VERSION ""

NS_ :

BS_:

BU_: Airbag Allrad EPS Teves_MK60_ESP LWS LWR Teves_MK70_MABS Waehlhebel EPB TRW_ESP ACC_Radar AFS Magne_Ride RKA_Plus Selespeed Waehlhebel_Sele PDC_PLA Lenkhilfe_APA VAQ Daempfer Hybrid_BMS Hybrid_PWR Hybrid_DQ200 EKlimakomp SWA HCA ACC_Lidar Lenkhilfe_ZF_3G FLA AG6 DQ Hybrid_MSG Diesel Otto Gateway_PQ35_A Gateway_PQ46_A Vector_XXX Fzg_CAN

BO_ 1488 mSysteminfo_1: 8 Gateway_PQ35_A
 SG_ SY1_Diag_Ant : 1|1@1+ (1,0) [0|1] "" Vector__XXX
 SG_ SY1_CAN_extern : 0|1@1+ (1,0) [0|1] "" Vector__XXX
 SG_ SY1_Diag_Komf : 3|1@1+ (1,0) [0|1] "" Vector__XXX
 SG_ SY1_Sleep_Info : 4|1@1+ (1,0) [0|1] "" Vector__XXX
 SG_ SY1_Sleep_Komf : 2|1@1+ (1,0) [0|1] "" Vector__XXX
 SG_ SY1_CAN_Info : 6|1@1+ (1,0) [0|1] "" Vector__XXX
 SG_ SY1_Diag_Info : 5|1@1+ (1,0) [0|1] "" Vector__XXX
 SG_ SY1_Verbauinfo : 7|1@1+ (1,0) [0|1] ""  Airbag,Diesel
 SG_ SY1_Fzg_Marke : 12|4@1+ (1,0) [0|15] "" Vector__XXX
 SG_ SY1_Fzg_Klasse : 8|4@1+ (1,0) [0|15] "" Vector__XXX
 SG_ SY1_Fzg_Index : 24|4@1+ (1,0) [0|15] "" Vector__XXX
 SG_ SY1_Fzg_Gen : 20|4@1+ (1,0) [0|15] "" Vector__XXX
 SG_ SY1_Tueren : 29|1@1+ (1,0) [0|1] "" Vector__XXX
 SG_ SY1_Fzg_Derivat : 16|4@1+ (1,0) [0|15] "" Vector__XXX
 SG_ SY1_Lenker : 28|1@1+ (1,0) [0|1] ""  TRW_ESP
 SG_ SY1_Fehlereintr : 31|1@1+ (1,0) [0|1] "" Vector__XXX
 SG_ SY1_Komf_HV : 36|4@1+ (1,0) [0|9] "" Vector__XXX
 SG_ SY1_Transportmode : 30|1@1+ (1,0) [0|1] ""  Daempfer
 SG_ SY1_Ant_NV : 40|4@1+ (1,0) [0|9] "" Vector__XXX
 SG_ SY1_Komf_NV : 32|4@1+ (1,0) [0|9] "" Vector__XXX
 SG_ SY1_Ant_HV : 44|4@1+ (1,0) [0|9] "" Vector__XXX
 SG_ SY1_Notbrems_Status : 56|1@1+ (1,0) [0|1] "" Vector__XXX
 SG_ SY1_ELV_Lock_Supply : 50|1@1+ (1,0) [0|1] "" Vector__XXX
 SG_ SY1_Relais_FAS_Zweig : 48|2@1+ (1,0) [0|3] ""  TRW_ESP,HCA
 SG_ SY1_QRS_Messmodus : 51|1@1+ (1,0) [0|1] ""  Otto
 SG_ SY1_res52 : 52|1@1+ (1,0) [0|1] "" Vector__XXX
 SG_ SY1_NWDF_gueltig : 54|1@1+ (1,0) [0|1] "" Vector__XXX
 SG_ SY1_res53 : 53|1@1+ (1,0) [0|1] "" Vector__XXX
 SG_ SY1_res59 : 59|1@1+ (1,0) [0|1] "" Vector__XXX
 SG_ SY1_NWDF : 55|1@1+ (1,0) [0|1] "" Vector__XXX
 SG_ SY1_res60 : 60|1@1+ (1,0) [0|1] "" Vector__XXX
 SG_ SY1_res62 : 62|1@1+ (1,0) [0|1] "" Vector__XXX
 SG_ SY1_res58 : 58|1@1+ (1,0) [0|1] "" Vector__XXX
 SG_ SY1_res57 : 57|1@1+ (1,0) [0|1] "" Vector__XXX
 SG_ SY1_res61 : 61|1@1+ (1,0) [0|1] "" Vector__XXX
 SG_ SY1_res63 : 63|1@1+ (1,0) [0|1] "" Vector__XXX

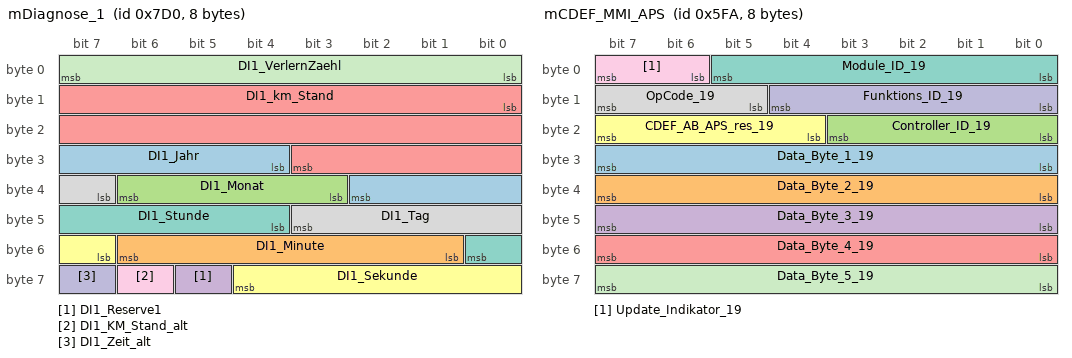
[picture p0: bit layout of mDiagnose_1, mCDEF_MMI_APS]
BO_ 2000 mDiagnose_1: 8 Gateway_PQ35_A
 SG_ DI1_Jahr : 28|7@1+ (1,2000) [2000|2127] "a"  Airbag,Diesel,Otto,Teves_MK60_ESP,LWR,Teves_MK70_MABS,EPB,TRW_ESP,ACC_Radar,AFS,Magne_Ride,RKA_Plus,PDC_PLA,Lenkhilfe_APA,VAQ,Daempfer,Hybrid_MSG,Hybrid_BMS,Hybrid_PWR,HCA,SWA,Allrad,ACC_Lidar,FLA,EPS,Lenkhilfe_ZF_3G
 SG_ DI1_Minute : 49|6@1+ (1,0) [0|59] "min"  Airbag,Diesel,Otto,LWR,EPB,TRW_ESP,ACC_Radar,AFS,Magne_Ride,RKA_Plus,PDC_PLA,Lenkhilfe_APA,VAQ,Daempfer,Hybrid_MSG,Hybrid_BMS,Hybrid_PWR,HCA,SWA,Allrad,ACC_Lidar,FLA,Teves_MK60_ESP,EPS,Lenkhilfe_ZF_3G
 SG_ DI1_Monat : 35|4@1+ (1,0) [0|15] ""  Airbag,Diesel,Otto,Teves_MK60_ESP,LWR,Teves_MK70_MABS,EPB,TRW_ESP,ACC_Radar,AFS,Magne_Ride,RKA_Plus,PDC_PLA,Lenkhilfe_APA,VAQ,Daempfer,Hybrid_MSG,Hybrid_BMS,Hybrid_PWR,HCA,SWA,Allrad,ACC_Lidar,FLA,Lenkhilfe_ZF_3G,EPS
 SG_ DI1_Reserve1 : 61|1@1+ (1,0) [0|1] ""  Allrad
 SG_ DI1_km_Stand : 8|20@1+ (1,0) [0|1048575] "km"  Airbag,Diesel,Otto,LWR,EPB,TRW_ESP,ACC_Radar,AFS,Magne_Ride,RKA_Plus,PDC_PLA,Lenkhilfe_APA,VAQ,Daempfer,Hybrid_MSG,Hybrid_BMS,Hybrid_PWR,HCA,SWA,Allrad,ACC_Lidar,FLA
 SG_ DI1_Sekunde : 55|6@1+ (1,0) [0|59] "s"  Airbag,Diesel,Otto,LWR,EPB,TRW_ESP,ACC_Radar,AFS,Magne_Ride,RKA_Plus,PDC_PLA,Lenkhilfe_APA,Daempfer,VAQ,Hybrid_MSG,Hybrid_BMS,Hybrid_PWR,HCA,SWA,Allrad,ACC_Lidar,FLA,Teves_MK60_ESP,EPS,Lenkhilfe_ZF_3G
 SG_ DI1_Stunde : 44|5@1+ (1,0) [0|23] "h"  Airbag,Diesel,Otto,LWR,EPB,TRW_ESP,ACC_Radar,AFS,Magne_Ride,RKA_Plus,PDC_PLA,Lenkhilfe_APA,VAQ,Daempfer,Hybrid_MSG,Hybrid_BMS,Hybrid_PWR,HCA,SWA,Allrad,ACC_Lidar,FLA,Teves_MK60_ESP,EPS,Lenkhilfe_ZF_3G
 SG_ DI1_Tag : 39|5@1+ (1,0) [0|31] ""  Airbag,Diesel,Otto,Teves_MK60_ESP,LWR,Teves_MK70_MABS,EPB,TRW_ESP,ACC_Radar,AFS,Magne_Ride,RKA_Plus,PDC_PLA,Lenkhilfe_APA,VAQ,Daempfer,Hybrid_MSG,Hybrid_BMS,Hybrid_PWR,HCA,SWA,Allrad,ACC_Lidar,FLA,EPS,Lenkhilfe_ZF_3G
 SG_ DI1_KM_Stand_alt : 62|1@1+ (1,0) [0|1] ""  Airbag,Diesel,Otto,LWR,EPB,TRW_ESP,ACC_Radar,AFS,Magne_Ride,RKA_Plus,PDC_PLA,Lenkhilfe_APA,VAQ,Hybrid_MSG,Hybrid_BMS,Hybrid_PWR,HCA,Daempfer,SWA,Allrad,ACC_Lidar,FLA
 SG_ DI1_Zeit_alt : 63|1@1+ (1,0) [0|1] ""  Airbag,Diesel,Otto,LWR,EPB,TRW_ESP,ACC_Radar,AFS,Magne_Ride,RKA_Plus,PDC_PLA,Lenkhilfe_APA,Hybrid_MSG,Hybrid_PWR,Hybrid_BMS,HCA,Daempfer,SWA,Allrad,ACC_Lidar,FLA,Teves_MK60_ESP,Lenkhilfe_ZF_3G,EPS
 SG_ DI1_VerlernZaehl : 0|8@1+ (1,0) [0|254] ""  Airbag,Diesel,Otto,LWR,EPB,TRW_ESP,ACC_Radar,AFS,Magne_Ride,RKA_Plus,PDC_PLA,Lenkhilfe_APA,VAQ,Daempfer,Hybrid_MSG,Hybrid_BMS,Hybrid_PWR,HCA,SWA,Allrad,ACC_Lidar,FLA,Teves_MK60_ESP

BO_ 1500 mSoll_Verbauliste_neu: 8 Gateway_PQ35_A
 SG_ VL1_Getr_SG : 1|1@1+ (1,0) [0|1] ""  TRW_ESP
 SG_ VL1_Airbag : 5|1@1+ (1,0) [0|1] ""  Otto,TRW_ESP,Hybrid_MSG
 SG_ VL1_Motor_SG : 0|1@1+ (1,0) [0|1] ""  TRW_ESP
 SG_ VL1_ABS : 2|1@1+ (1,0) [0|1] ""  Otto,Hybrid_MSG
 SG_ VL1_res_08 : 8|1@1+ (1,0) [0|1] "" Vector__XXX
 SG_ VL1_EPB : 12|1@1+ (1,0) [0|1] "" Vector__XXX
 SG_ VL1_Kombi : 3|1@1+ (1,0) [0|1] "" Vector__XXX
 SG_ VL1_Allrad : 9|1@1+ (1,0) [0|1] ""  Teves_MK60_ESP,Teves_MK70_MABS,TRW_ESP
 SG_ VL1_LSM : 4|1@1+ (1,0) [0|1] ""  Otto,Hybrid_MSG,TRW_ESP
 SG_ VL1_Lenkhilfe : 6|1@1+ (1,0) [0|1] "" Vector__XXX
 SG_ VL1_ADR : 10|1@1+ (1,0) [0|1] ""  TRW_ESP,Teves_MK60_ESP
 SG_ VL1_Daempfer : 14|1@1+ (1,0) [0|1] "" Vector__XXX
 SG_ VL1_dyn_LWR : 7|1@1+ (1,0) [0|1] "" Vector__XXX
 SG_ VL1_DAB : 57|1@1+ (1,0) [0|1] "" Vector__XXX
 SG_ VL1_MotorSlave : 16|1@1+ (1,0) [0|1] "" Vector__XXX
 SG_ VL1_res_13 : 13|1@1+ (1,0) [0|1] "" Vector__XXX
 SG_ VL1_TSG_BT : 27|1@1+ (1,0) [0|1] "" Vector__XXX
 SG_ VL1_TSG_FT : 26|1@1+ (1,0) [0|1] "" Vector__XXX
 SG_ VL1_TSG_HL : 28|1@1+ (1,0) [0|1] "" Vector__XXX
 SG_ VL1_ZKE : 25|1@1+ (1,0) [0|1] "" Vector__XXX
 SG_ VL1_BSG_Komf : 24|1@1+ (1,0) [0|1] ""  Otto,Hybrid_MSG
 SG_ VL1_Memory : 30|1@1+ (1,0) [0|1] "" Vector__XXX
 SG_ VL1_Dachmodul_K : 31|1@1+ (1,0) [0|1] "" Vector__XXX
 SG_ VL1_TSG_HR : 29|1@1+ (1,0) [0|1] "" Vector__XXX
 SG_ VL1_Zentralelektrik_II : 32|1@1+ (1,0) [0|1] "" Vector__XXX
 SG_ VL1_Lenksaeule : 34|1@1+ (1,0) [0|1] ""  Otto,Hybrid_MSG
 SG_ VL1_Einparkhilfe : 37|1@1+ (1,0) [0|1] "" Vector__XXX
 SG_ VL1_Gateway : 35|1@1+ (1,0) [0|1] ""  Otto,Hybrid_MSG
 SG_ VL1_RDK : 33|1@1+ (1,0) [0|1] "" Vector__XXX
 SG_ VL1_PTC_Heizung : 38|1@1+ (1,0) [0|1] "" Vector__XXX
 SG_ VL1_Standheiz : 39|1@1+ (1,0) [0|1] "" Vector__XXX
 SG_ VL1_Clima_Komf : 36|1@1+ (1,0) [0|1] ""  Diesel,Otto,Hybrid_MSG
 SG_ VL1_res_42 : 42|1@1+ (1,0) [0|1] "" Vector__XXX
 SG_ VL1_RSE_I : 41|1@1+ (1,0) [0|1] "" Vector__XXX
 SG_ VL1_Verdeck : 40|1@1+ (1,0) [0|1] "" Vector__XXX
 SG_ VL1_MDI_I : 43|1@1+ (1,0) [0|1] "" Vector__XXX
 SG_ VL1_Memory_BF : 45|1@1+ (1,0) [0|1] "" Vector__XXX
 SG_ VL1_Heckdeckel : 48|1@1+ (1,0) [0|1] "" Vector__XXX
 SG_ VL1_Anhaenger : 44|1@1+ (1,0) [0|1] ""  TRW_ESP
 SG_ VL1_Easy_Entry_VF : 46|1@1+ (1,0) [0|1] "" Vector__XXX
 SG_ VL1_Sonderfzg_SG : 50|1@1+ (1,0) [0|1] "" Vector__XXX
 SG_ VL1_Tastenmodul : 51|1@1+ (1,0) [0|1] "" Vector__XXX
 SG_ VL1_Radio : 62|1@1+ (1,0) [0|1] "" Vector__XXX
 SG_ VL1_Telefon : 63|1@1+ (1,0) [0|1] "" Vector__XXX
 SG_ VL1_Navigation : 59|1@1+ (1,0) [0|1] "" Vector__XXX
 SG_ VL1_Neigungsmodul_I : 61|1@1+ (1,0) [0|1] "" Vector__XXX
 SG_ VL1_ADR_getrennt : 11|1@1+ (1,0) [0|1] "" Vector__XXX
 SG_ VL1_DSP : 56|1@1+ (1,0) [0|1] "" Vector__XXX
 SG_ VL1_Easy_Entry_VB : 47|1@1+ (1,0) [0|1] "" Vector__XXX
 SG_ VL1_Telematik : 58|1@1+ (1,0) [0|1] "" Vector__XXX
 SG_ VL1_TV_Tuner : 60|1@1+ (1,0) [0|1] "" Vector__XXX
 SG_ VL1_WFS_K : 53|1@1+ (1,0) [0|1] "" Vector__XXX
 SG_ VL1_Kompass : 52|1@1+ (1,0) [0|1] "" Vector__XXX
 SG_ VL1_Rearview : 49|1@1+ (1,0) [0|1] "" Vector__XXX
 SG_ VL1_GSM_Pager : 54|1@1+ (1,0) [0|1] "" Vector__XXX
 SG_ VL1_InfoElektronik : 55|1@1+ (1,0) [0|1] "" Vector__XXX
 SG_ VL1_Kombi_KBI : 22|1@1+ (1,0) [0|1] "" Vector__XXX
 SG_ VL1_Soll_eq_Ist : 23|1@1+ (1,0) [0|1] ""  Otto,Hybrid_MSG
 SG_ VL1_Quersperre : 15|1@1+ (1,0) [0|1] "" Vector__XXX
 SG_ VL1_SWA : 17|1@1+ (1,0) [0|1] "" Vector__XXX
 SG_ VL1_PLA : 20|1@1+ (1,0) [0|1] "" Vector__XXX
 SG_ VL1_HCA : 18|1@1+ (1,0) [0|1] ""  HCA
 SG_ VL1_WFS_KBI : 21|1@1+ (1,0) [0|1] "" Vector__XXX
 SG_ VL1_RKA_Plus : 19|1@1+ (1,0) [0|1] "" Vector__XXX

BO_ 1504 mClima_1: 8 Gateway_PQ35_A
 SG_ CL1_Hecksch : 2|1@1+ (1,0) [0|1] "" Vector__XXX
 SG_ CL1_Heizleist : 5|1@1+ (1,0) [0|1] ""  Diesel
 SG_ CL1_Fa_Zuheiz : 1|1@1+ (1,0) [0|1] ""  Diesel,Hybrid_MSG
 SG_ CL1_Kompressor : 4|1@1+ (1,0) [0|1] ""  Diesel,Otto,Hybrid_MSG
 SG_ CL1_Sta_Druck : 7|1@1+ (1,0) [0|1] ""  Otto,Hybrid_MSG
 SG_ CL1_Frontsch : 3|1@1+ (1,0) [0|1] "" Vector__XXX
 SG_ CL1_Sta_Moment : 6|1@1+ (1,0) [0|1] ""  Otto,Hybrid_MSG
 SG_ CL1_Kompr_Last : 24|8@1+ (0.25,0) [0|63.5] "Nm"  Diesel,Otto,Hybrid_MSG
 SG_ CL1_Druck : 16|8@1+ (0.2,0) [0|50.8] "bar"  Diesel,Otto,Hybrid_MSG
 SG_ CL1_Aussentemp : 8|8@1+ (0.5,-50) [-50|77] "°C" Vector__XXX
 SG_ CL1_Gebl_last : 32|8@1+ (0.4,0) [0|101.6] "%"  Hybrid_BMS,Otto
 SG_ CL1_Einheit_Temp : 48|1@1+ (1,0) [0|1] "" Vector__XXX
 SG_ CL1_Luefter : 40|8@1+ (0.4,0) [0|101.6] "%"  Diesel,Otto,Hybrid_MSG
 SG_ CL1_Fehlereintr : 55|1@1+ (1,0) [0|1] "" Vector__XXX
 SG_ CL1_WAPU_Zuschaltung : 50|1@1+ (1,0) [0|1] "" Vector__XXX
 SG_ CL1_Restwaerme : 51|1@1+ (1,0) [0|1] "" Vector__XXX
 SG_ CL1_LL_Dz : 0|1@1+ (1,0) [0|1] ""  Diesel,Otto,Hybrid_MSG
 SG_ CL1_AC_Schalter : 49|1@1+ (1,0) [0|1] ""  Diesel,Otto
 SG_ CL1_Temp_Stoss : 56|8@1+ (0.5,-50) [-50|77] "°C" Vector__XXX
 SG_ CL1_PTC_Hzg : 52|3@1+ (25,0) [0|100] "%" Vector__XXX

BO_ 1952 mTP_Dyn_LWS: 8 Gateway_PQ35_A
 SG_ TPDyn_LWS : 0|64@1+ (1,0) [0|1.8446744074E+019] ""  LWS

BO_ 1857 mTP_Dyn_Motor_2: 8 Gateway_PQ35_A
 SG_ TPDyn_Motor_2 : 0|64@1+ (1,0) [0|1.8446744074E+019] ""  Diesel,Otto,Hybrid_MSG

BO_ 1856 mTP_Dyn_Motor_1: 8 Gateway_PQ35_A
 SG_ TPDyn_Motor_1 : 0|64@1+ (1,0) [0|1.8446744074E+019] ""  Diesel,Otto,Hybrid_MSG

BO_ 1859 mTP_Dyn_Motor_4: 8 Gateway_PQ35_A
 SG_ TPDyn_Motor_4 : 0|64@1+ (1,0) [0|1.8446744074E+019] ""  Diesel,Otto,Hybrid_MSG

BO_ 512 mTP_Er_Tester: 7 Gateway_PQ35_A
 SG_ Tester_TP_Er : 0|56@1+ (1,0) [0|7.2057594038E+016] ""  AG6,Airbag,Allrad,Diesel,EPS,Otto,Teves_MK60_ESP,LWS,LWR,Teves_MK70_MABS,DQ,EPB,TRW_ESP,ACC_Radar,AFS,Magne_Ride,RKA_Plus,Selespeed,PDC_PLA,Lenkhilfe_APA,VAQ,Daempfer,Hybrid_MSG,Hybrid_DQ200,SWA

BO_ 1858 mTP_Dyn_Motor_3: 8 Gateway_PQ35_A
 SG_ TPDyn_Motor_3 : 0|64@1+ (1,0) [0|1.8446744074E+019] ""  Diesel,Otto,Hybrid_MSG

BO_ 1893 mTP_Dyn_Allrad_2: 8 Gateway_PQ35_A
 SG_ TPDyn_Allrad_2 : 0|64@1+ (1,0) [0|1.8446744074E+019] ""  Allrad

BO_ 1906 mTP_Dyn_Daempfer_1: 8 Gateway_PQ35_A
 SG_ TPDyn_Daempfer_1 : 0|64@1+ (1,0) [0|1.8446744074E+019] ""  Magne_Ride,Daempfer

BO_ 1875 mTP_Dyn_RKA_Plus_2: 8 Gateway_PQ35_A
 SG_ TPDyn_RKA_Plus_2 : 0|64@1+ (1,0) [0|1.8446744074E+019] ""  RKA_Plus

BO_ 1874 mTP_Dyn_RKA_Plus_1: 8 Gateway_PQ35_A
 SG_ TPDyn_RKA_Plus_1 : 0|64@1+ (1,0) [0|1.8446744074E+019] ""  RKA_Plus

BO_ 914 mGate_Komf_2: 8 Gateway_PQ35_A
 SG_ GK2_Sta_Lichtsensor : 1|1@1+ (1,0) [0|1] ""  AFS,SWA
 SG_ GK2_Sta_Kessy_4 : 8|1@1+ (1,0) [0|1] ""  Diesel,Otto
 SG_ GK2_res_09 : 9|1@1+ (1,0) [0|1] "" Vector__XXX
 SG_ GK2_Sta_LSM : 0|1@1+ (1,0) [0|1] "" Vector__XXX
 SG_ GK2_Helligkeit : 16|3@1+ (714.286,0) [0|5000.002] "Lux"  AFS,SWA
 SG_ GK2_Sta_VSG : 3|1@1+ (1,0) [0|1] ""  Airbag,PDC_PLA,Otto
 SG_ GK2_Sta_Profil : 5|1@1+ (1,0) [0|1] ""  SWA,PDC_PLA
 SG_ GK2_Sta_Clima2 : 6|1@1+ (1,0) [0|1] ""  Diesel,Otto
 SG_ GK2_Sta_Licht1 : 2|1@1+ (1,0) [0|1] ""  HCA,SWA,AFS
 SG_ GK2_Feh_VLR : 10|1@1+ (1,0) [0|1] "" Vector__XXX
 SG_ GK2_Sta_BSG4 : 7|1@1+ (1,0) [0|1] ""  Diesel,Otto
 SG_ GK2_Blk_L_Kontrolle : 11|1@1+ (1,0) [0|1] ""  HCA,SWA
 SG_ GK2_Sta_Schluessel : 4|1@1+ (1,0) [0|1] ""  TRW_ESP,Daempfer,EPB
 SG_ GK2_res_13 : 13|1@1+ (1,0) [0|1] "" Vector__XXX
 SG_ GK2_LS_KomFehler : 14|1@1+ (1,0) [0|1] ""  AFS
 SG_ GK2_VD_zu_ver : 19|1@1+ (1,0) [0|1] ""  PDC_PLA
 SG_ GK2_Blk_R_Kontrolle : 12|1@1+ (1,0) [0|1] ""  HCA,SWA
 SG_ GK2_VD_offen_ver : 21|1@1+ (1,0) [0|1] ""  Airbag,PDC_PLA,Otto
 SG_ GK2_LS_def : 15|1@1+ (1,0) [0|1] ""  AFS
 SG_ GK2_Verdeck_Anf : 22|1@1+ (1,0) [0|1] ""  PDC_PLA
 SG_ GK2_VD_entriegelt : 20|1@1+ (1,0) [0|1] ""  PDC_PLA
 SG_ GK2_VDKD_auf : 23|1@1+ (1,0) [0|1] ""  PDC_PLA
 SG_ GK2_Schluessel : 24|4@1+ (1,0) [0|15] ""  Daempfer
 SG_ GK2_EM_LIN_ungueltig : 31|1@1+ (1,0) [0|1] ""  Diesel,Otto
 SG_ GK2_AFL_Schalter : 29|1@1+ (1,0) [0|1] ""  AFS
 SG_ GK2_Hardtop : 28|1@1+ (1,0) [0|1] ""  PDC_PLA
 SG_ GK2_Profil : 32|4@1+ (1,0) [0|15] ""  PDC_PLA,SWA
 SG_ GK2_Kl_StSt_Info : 36|2@1+ (1,0) [0|3] ""  Otto,Diesel
 SG_ GK2_BEM_P_Generator : 40|8@1+ (50,0) [0|12700] "W"  Diesel,Otto
 SG_ GK2_BEM_Abschaltstufen : 48|3@1+ (1,0) [0|7] ""  Diesel,Otto
 SG_ GK2_res_60 : 60|4@1+ (1,0) [0|15] "" Vector__XXX
 SG_ GK2_Nebelschluss : 30|1@1+ (1,0) [0|1] ""  AFS
 SG_ GK2_BSG_StSt_Info : 38|2@1+ (1,0) [0|3] ""  Otto,Diesel
 SG_ GK2_BEM_DFM : 51|5@1+ (3.225,0.025) [0.025|100] "%"  Diesel,Otto
 SG_ GK2_BEM_StSt_Info : 58|2@1+ (1,0) [0|3] ""  Diesel,Otto
 SG_ GK2_Kessy_StSt_Info : 56|2@1+ (1,0) [0|3] ""  Diesel,Otto

BO_ 1978 mTP_Dyn_PLA_PDC: 8 Gateway_PQ35_A
 SG_ TPDyn_PLA_PDC : 0|64@1+ (1,0) [0|1.8446744074E+019] ""  PDC_PLA

BO_ 1940 mTP_Dyn_EPB_1: 8 Gateway_PQ35_A
 SG_ TPDyn_EPB_1 : 0|64@1+ (1,0) [0|1.8446744074E+019] ""  EPB,TRW_ESP

BO_ 1880 mTP_Dyn_Quersperre_1: 8 Gateway_PQ35_A
 SG_ TPDyn_Quersperre_1 : 0|64@1+ (1,0) [0|1.8446744074E+019] ""  VAQ

BO_ 1881 mTP_Dyn_Quersperre_2: 8 Gateway_PQ35_A
 SG_ TPDyn_Quersperre_2 : 0|64@1+ (1,0) [0|1.8446744074E+019] ""  VAQ

BO_ 919 mZKE_5: 8 Gateway_PQ35_A
 SG_ ZK5_Endlage_ausgefahren : 12|1@1+ (1,0) [0|1] ""  Teves_MK60_ESP
 SG_ ZK5_Status_Spoiler : 14|1@1+ (1,0) [0|1] ""  Teves_MK60_ESP
 SG_ ZK5_Endlage_eingefahren : 13|1@1+ (1,0) [0|1] ""  Teves_MK60_ESP
 SG_ ZK5_res_15 : 15|1@1+ (1,0) [0|1] "" Vector__XXX
 SG_ ZK5_Zaehler : 8|4@1+ (1,0) [0|15] "Tabelle"  Teves_MK60_ESP
 SG_ ZK5_Checksumme : 0|8@1+ (1,0) [0|255] "Tabelle"  Teves_MK60_ESP
 SG_ ZK5_VD_Endlage_geschl : 16|1@1+ (1,0) [0|1] ""  Teves_MK60_ESP,PDC_PLA
 SG_ ZK5_VD_Endlage_abgelegt : 17|1@1+ (1,0) [0|1] ""  Teves_MK60_ESP,PDC_PLA
 SG_ ZK5_VD_Verbau : 18|1@1+ (1,0) [0|1] ""  Teves_MK60_ESP,PDC_PLA
 SG_ ZK5_res_20 : 20|1@1+ (1,0) [0|1] "" Vector__XXX
 SG_ ZK5_res_21 : 21|1@1+ (1,0) [0|1] "" Vector__XXX
 SG_ ZK5_res_22 : 22|1@1+ (1,0) [0|1] "" Vector__XXX
 SG_ ZK5_res_19 : 19|1@1+ (1,0) [0|1] "" Vector__XXX
 SG_ ZK5_res_23 : 23|1@1+ (1,0) [0|1] "" Vector__XXX
 SG_ ZK5_res_24 : 24|1@1+ (1,0) [0|1] "" Vector__XXX
 SG_ ZK5_res_25 : 25|1@1+ (1,0) [0|1] "" Vector__XXX
 SG_ ZK5_res_26 : 26|1@1+ (1,0) [0|1] "" Vector__XXX
 SG_ ZK5_res_27 : 27|1@1+ (1,0) [0|1] "" Vector__XXX
 SG_ ZK5_res_29 : 29|1@1+ (1,0) [0|1] "" Vector__XXX
 SG_ ZK5_res_31 : 31|1@1+ (1,0) [0|1] "" Vector__XXX
 SG_ ZK5_res_32 : 32|1@1+ (1,0) [0|1] "" Vector__XXX
 SG_ ZK5_res_33 : 33|1@1+ (1,0) [0|1] "" Vector__XXX
 SG_ ZK5_res_34 : 34|1@1+ (1,0) [0|1] "" Vector__XXX
 SG_ ZK5_res_30 : 30|1@1+ (1,0) [0|1] "" Vector__XXX
 SG_ ZK5_res_35 : 35|1@1+ (1,0) [0|1] "" Vector__XXX
 SG_ ZK5_res_28 : 28|1@1+ (1,0) [0|1] "" Vector__XXX
 SG_ ZK5_res_36 : 36|1@1+ (1,0) [0|1] "" Vector__XXX
 SG_ ZK5_res_37 : 37|1@1+ (1,0) [0|1] "" Vector__XXX
 SG_ ZK5_res_38 : 38|1@1+ (1,0) [0|1] "" Vector__XXX
 SG_ ZK5_res_40 : 40|1@1+ (1,0) [0|1] "" Vector__XXX
 SG_ ZK5_res_41 : 41|1@1+ (1,0) [0|1] "" Vector__XXX
 SG_ ZK5_res_42 : 42|1@1+ (1,0) [0|1] "" Vector__XXX
 SG_ ZK5_res_45 : 45|1@1+ (1,0) [0|1] "" Vector__XXX
 SG_ ZK5_res_46 : 46|1@1+ (1,0) [0|1] "" Vector__XXX
 SG_ ZK5_res_39 : 39|1@1+ (1,0) [0|1] "" Vector__XXX
 SG_ ZK5_res_47 : 47|1@1+ (1,0) [0|1] "" Vector__XXX
 SG_ ZK5_res_48 : 48|1@1+ (1,0) [0|1] "" Vector__XXX
 SG_ ZK5_res_49 : 49|1@1+ (1,0) [0|1] "" Vector__XXX
 SG_ ZK5_res_50 : 50|1@1+ (1,0) [0|1] "" Vector__XXX
 SG_ ZK5_res_51 : 51|1@1+ (1,0) [0|1] "" Vector__XXX
 SG_ ZK5_res_44 : 44|1@1+ (1,0) [0|1] "" Vector__XXX
 SG_ ZK5_res_52 : 52|1@1+ (1,0) [0|1] "" Vector__XXX
 SG_ ZK5_res_43 : 43|1@1+ (1,0) [0|1] "" Vector__XXX
 SG_ ZK5_res_53 : 53|1@1+ (1,0) [0|1] "" Vector__XXX
 SG_ ZK5_res_54 : 54|1@1+ (1,0) [0|1] "" Vector__XXX
 SG_ ZK5_res_55 : 55|1@1+ (1,0) [0|1] "" Vector__XXX
 SG_ ZK5_res_56 : 56|1@1+ (1,0) [0|1] "" Vector__XXX
 SG_ ZK5_res_57 : 57|1@1+ (1,0) [0|1] "" Vector__XXX
 SG_ ZK5_res_58 : 58|1@1+ (1,0) [0|1] "" Vector__XXX
 SG_ ZK5_res_59 : 59|1@1+ (1,0) [0|1] "" Vector__XXX
 SG_ ZK5_res_60 : 60|1@1+ (1,0) [0|1] "" Vector__XXX
 SG_ ZK5_res_63 : 63|1@1+ (1,0) [0|1] "" Vector__XXX
 SG_ ZK5_res_62 : 62|1@1+ (1,0) [0|1] "" Vector__XXX
 SG_ ZK5_res_61 : 61|1@1+ (1,0) [0|1] "" Vector__XXX

BO_ 1658 BAP_Anzeige_02: 8 Gateway_PQ35_A
 SG_ BAP_var_Anzeige_02 : 16|48@1+ (1,0) [0|2.8147497671E+014] "" Vector__XXX
 SG_ BAP_Data_Anzeige_02 : 0|16@1+ (1,0) [0|65535] ""  PDC_PLA,Hybrid_MSG

BO_ 1530 mCDEF_MMI_APS: 8 Gateway_PQ35_A
 SG_ Data_Byte_1_19 : 24|8@1+ (1,0) [0|255] ""  PDC_PLA
 SG_ Data_Byte_2_19 : 32|8@1+ (1,0) [0|255] ""  PDC_PLA
 SG_ Controller_ID_19 : 16|4@1+ (1,0) [0|15] ""  PDC_PLA
 SG_ Data_Byte_3_19 : 40|8@1+ (1,0) [0|255] ""  PDC_PLA
 SG_ Data_Byte_4_19 : 48|8@1+ (1,0) [0|255] ""  PDC_PLA
 SG_ CDEF_AB_APS_res_19 : 20|4@1+ (1,0) [0|15] "" Vector__XXX
 SG_ Module_ID_19 : 0|6@1+ (1,0) [0|63] ""  PDC_PLA
 SG_ OpCode_19 : 13|3@1+ (1,0) [0|7] ""  PDC_PLA
 SG_ Update_Indikator_19 : 6|2@1+ (1,0) [0|3] ""  PDC_PLA
 SG_ Funktions_ID_19 : 8|5@1+ (1,0) [0|31] ""  PDC_PLA
 SG_ Data_Byte_5_19 : 56|8@1+ (1,0) [0|255] ""  PDC_PLA

BO_ 2015 ISO_Funktionaler_Req_OBD: 8 Gateway_PQ35_A
 SG_ ISO_OBD_01_Req_Data : 0|64@1+ (1,0) [0|1.8446744074E+019] ""  Hybrid_DQ200,Hybrid_PWR,Hybrid_MSG,Hybrid_BMS,AG6,DQ,Diesel,Otto

BO_ 1792 ISO_Funktionaler_Req_All: 8 Gateway_PQ35_A
 SG_ ISO_ALL_01_Req_Data : 0|64@1+ (1,0) [0|1.8446744074E+019] ""  EKlimakomp,Hybrid_BMS,Hybrid_PWR,Hybrid_MSG,Hybrid_DQ200,DQ,Diesel,AG6,Otto,Airbag,ACC_Lidar,Lenkhilfe_ZF_3G,PDC_PLA

BO_ 2017 ISO_Getriebe_01_Req: 8 Gateway_PQ35_A
 SG_ ISO_Getriebe_01_Req_Data : 0|64@1+ (1,0) [0|1.8446744074E+019] ""  Hybrid_DQ200,AG6,DQ

BO_ 2016 ISO_MO_01_Req: 8 Gateway_PQ35_A
 SG_ ISO_MO_01_Req_Data : 0|64@1+ (1,0) [0|1.8446744074E+019] ""  Hybrid_MSG,Diesel,Otto

BO_ 1976 mTP_Dyn_SWA_1: 8 Gateway_PQ35_A
 SG_ TPDyn_SWA_1 : 0|64@1+ (1,0) [0|1.8446744074E+019] ""  SWA

BO_ 1977 mTP_Dyn_SWA_2: 8 Gateway_PQ35_A
 SG_ TPDyn_SWA_2 : 0|64@1+ (1,0) [0|1.8446744074E+019] ""  SWA

BO_ 1654 BAP_Anzeige: 8 Gateway_PQ35_A
 SG_ BAP_var_Anzeige : 16|48@1+ (1,0) [0|2.8147497671E+014] "" Vector__XXX
 SG_ BAP_Data_Anzeige : 0|16@1+ (1,0) [0|65535] ""  HCA,SWA,ACC_Radar,PDC_PLA,ACC_Lidar

BO_ 2018 ISO_MOS_01_Req: 8 Gateway_PQ35_A
 SG_ ISO_MOS_01_Req_Data : 0|64@1+ (1,0) [0|1.8446744074E+019] "" Vector__XXX

BO_ 2021 ISO_OBD_BECM_Req: 8 Gateway_PQ35_A
 SG_ ISO_OBD_BECM_Req_Data : 0|64@1+ (1,0) [0|1.8446744074E+019] "" Vector__XXX

BO_ 2023 ISO_OBD_reserv5_Req: 8 Gateway_PQ35_A
 SG_ ISO_OBD_reserv5_Req_Data : 0|64@1+ (1,0) [0|1.8446744074E+019] "" Vector__XXX

BO_ 2022 ISO_OBD_DMCM_Req: 8 Gateway_PQ35_A
 SG_ ISO_OBD_DMCM_Req_Data : 0|64@1+ (1,0) [0|1.8446744074E+019] "" Vector__XXX

BO_ 2020 ISO_OBD_reserv2_Req: 8 Gateway_PQ35_A
 SG_ ISO_OBD_reserv2_Req_Data : 0|64@1+ (1,0) [0|1.8446744074E+019] "" Vector__XXX

BO_ 2019 ISO_OBD_reserv1_Req: 8 Gateway_PQ35_A
 SG_ ISO_OBD_reserv1_Req_Data : 0|64@1+ (1,0) [0|1.8446744074E+019] "" Vector__XXX

BO_ 1811 ISO_ABS_Req: 8 Gateway_PQ35_A
 SG_ ISO_ABS_Req_Data : 0|64@1+ (1,0) [0|1.8446744074E+019] "" Vector__XXX

BO_ 1876 ISO_LWRAFS_Req: 8 Gateway_PQ35_A
 SG_ ISO_LWRAFS_Req_Data : 0|64@1+ (1,0) [0|1.8446744074E+019] "" Vector__XXX

BO_ 1810 ISO_Lenkhilfe_Req: 8 Gateway_PQ35_A
 SG_ ISO_Lenkhilfe_Req_Data : 0|64@1+ (1,0) [0|1.8446744074E+019] ""  Lenkhilfe_ZF_3G

BO_ 1813 ISO_Airbag_01_Req: 8 Gateway_PQ35_A
 SG_ ISO_Airbag_01_Req_Data : 0|64@1+ (1,0) [0|1.8446744074E+019] ""  Airbag

BO_ 1802 ISO_EPH_Req: 8 Gateway_PQ35_A
 SG_ ISO_EPH_Req_Data : 0|64@1+ (1,0) [0|1.8446744074E+019] ""  PDC_PLA

BO_ 1879 ISO_ACC_Req: 8 Gateway_PQ35_A
 SG_ ISO_ACC_Req_Data : 0|64@1+ (1,0) [0|1.8446744074E+019] ""  ACC_Lidar

BO_ 1824 NMH_Gateway: 7 Gateway_PQ35_A
 SG_ NMH_GW_Abschaltstufe_aktiv : 38|1@1+ (1,0) [0|1] "" Vector__XXX
 SG_ NMH_GW_Car_WakeUp : 6|1@1+ (1,0) [0|1] "" Vector__XXX
 SG_ NMH_GW_Eindraht_Fehler : 39|1@1+ (1,0) [0|1] "" Vector__XXX
 SG_ NMH_GW_Fkt_WakeUp : 13|3@1+ (1,0) [0|7] "" Vector__XXX
 SG_ NMH_GW_kein_NL : 24|1@1+ (1,0) [0|1] "" Vector__XXX
 SG_ NMH_GW_KompSchutz : 35|1@1+ (1,0) [0|1] "" Vector__XXX
 SG_ NMH_GW_Mute_Mode : 36|1@1+ (1,0) [0|1] "" Vector__XXX
 SG_ NMH_GW_CAN_Diag_deaktiv : 34|1@1+ (1,0) [0|1] "" Vector__XXX
 SG_ NMH_GW_NL_1 : 25|1@1+ (1,0) [0|1] "" Vector__XXX
 SG_ NMH_GW_NL_2 : 26|1@1+ (1,0) [0|1] "" Vector__XXX
 SG_ NMH_GW_NL_3 : 27|1@1+ (1,0) [0|1] "" Vector__XXX
 SG_ NMH_GW_NL_4 : 28|1@1+ (1,0) [0|1] "" Vector__XXX
 SG_ NMH_GW_NL_5 : 29|1@1+ (1,0) [0|1] "" Vector__XXX
 SG_ NMH_GW_NL_6 : 30|1@1+ (1,0) [0|1] "" Vector__XXX
 SG_ NMH_GW_NL_7 : 31|1@1+ (1,0) [0|1] "" Vector__XXX
 SG_ NMH_GW_NL_aktiv_5 : 20|1@1+ (1,0) [0|1] "" Vector__XXX
 SG_ NMH_GW_NL_aktiv_6 : 21|1@1+ (1,0) [0|1] "" Vector__XXX
 SG_ NMH_GW_NL_aktiv_7 : 22|1@1+ (1,0) [0|1] "" Vector__XXX
 SG_ NMH_GW_NL_aktiv_8 : 23|1@1+ (1,0) [0|1] "" Vector__XXX
 SG_ NMH_GW_NM_aktiv_Diagnose : 17|1@1+ (1,0) [0|1] "" Vector__XXX
 SG_ NMH_GW_NM_aktiv_Klemme_15 : 16|1@1+ (1,0) [0|1] "" Vector__XXX
 SG_ NMH_GW_NL_aktiv_4 : 19|1@1+ (1,0) [0|1] "" Vector__XXX
 SG_ NMH_GW_NM_aktiv_Start : 18|1@1+ (1,0) [0|1] "" Vector__XXX
 SG_ NMH_GW_Normal_Mode_1 : 2|1@1+ (1,0) [0|1] "" Vector__XXX
 SG_ NMH_GW_Normal_Mode_2 : 3|1@1+ (1,0) [0|1] "" Vector__XXX
 SG_ NMH_GW_Per_WakeUp : 8|5@1+ (1,0) [0|31] "" Vector__XXX
 SG_ NMH_GW_res_04 : 4|1@1+ (1,0) [0|1] "" Vector__XXX
 SG_ NMH_GW_res_05 : 5|1@1+ (1,0) [0|1] "" Vector__XXX
 SG_ NMH_GW_res_32 : 32|1@1+ (1,0) [0|1] "" Vector__XXX
 SG_ NMH_GW_res_07 : 7|1@1+ (1,0) [0|1] "" Vector__XXX
 SG_ NMH_GW_res_41 : 41|1@1+ (1,0) [0|1] "" Vector__XXX
 SG_ NMH_GW_res_42 : 42|1@1+ (1,0) [0|1] "" Vector__XXX
 SG_ NMH_GW_res_43 : 43|1@1+ (1,0) [0|1] "" Vector__XXX
 SG_ NMH_GW_res_44 : 44|1@1+ (1,0) [0|1] "" Vector__XXX
 SG_ NMH_GW_res_45 : 45|1@1+ (1,0) [0|1] "" Vector__XXX
 SG_ NMH_GW_res_46 : 46|1@1+ (1,0) [0|1] "" Vector__XXX
 SG_ NMH_GW_res_40 : 40|1@1+ (1,0) [0|1] "" Vector__XXX
 SG_ NMH_GW_res_47 : 47|1@1+ (1,0) [0|1] "" Vector__XXX
 SG_ NMH_GW_res_48 : 48|1@1+ (1,0) [0|1] "" Vector__XXX
 SG_ NMH_GW_res_49 : 49|1@1+ (1,0) [0|1] "" Vector__XXX
 SG_ NMH_GW_res_50 : 50|1@1+ (1,0) [0|1] "" Vector__XXX
 SG_ NMH_GW_res_52 : 52|1@1+ (1,0) [0|1] "" Vector__XXX
 SG_ NMH_GW_res_53 : 53|1@1+ (1,0) [0|1] "" Vector__XXX
 SG_ NMH_GW_res_54 : 54|1@1+ (1,0) [0|1] "" Vector__XXX
 SG_ NMH_GW_res_55 : 55|1@1+ (1,0) [0|1] "" Vector__XXX
 SG_ NMH_GW_Start_1 : 0|1@1+ (1,0) [0|1] ""  Teves_MK60_ESP,Teves_MK70_MABS,TRW_ESP
 SG_ NMH_GW_res_51 : 51|1@1+ (1,0) [0|1] "" Vector__XXX
 SG_ NMH_GW_Start_2 : 1|1@1+ (1,0) [0|1] "" Vector__XXX
 SG_ NMH_GW_TimeOut_Fehler : 33|1@1+ (1,0) [0|1] "" Vector__XXX
 SG_ NMH_GW_Transport_Mode : 37|1@1+ (1,0) [0|1] "" Vector__XXX

BO_ 1956 mTP_Dyn_LDW_1: 8 Gateway_PQ35_A
 SG_ TPDyn_LDW_1 : 0|64@1+ (1,0) [0|1.8446744074E+019] "" Vector__XXX

BO_ 1957 mTP_Dyn_LDW_2: 8 Gateway_PQ35_A
 SG_ TPDyn_LDW_2 : 0|64@1+ (1,0) [0|1.8446744074E+019] ""  HCA

BO_ 2033 Req_Airbag_Deployment: 8 Gateway_PQ35_A
 SG_ Req_Airbag_Deployment : 0|64@1+ (1,0) [0|1.8446744074E+019] ""  Airbag

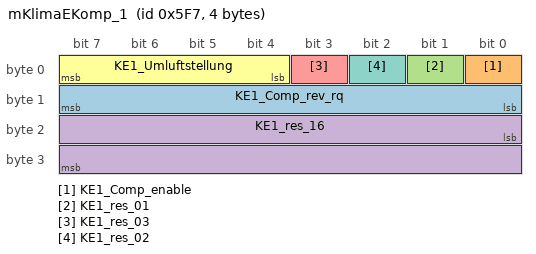
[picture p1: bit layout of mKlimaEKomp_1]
BO_ 1527 mKlimaEKomp_1: 4 Gateway_PQ35_A
 SG_ KE1_Comp_rev_rq : 8|8@1+ (50,0) [0|8600] "rpm"  EKlimakomp
 SG_ KE1_Comp_enable : 0|1@1+ (1,0) [0|1] ""  EKlimakomp
 SG_ KE1_res_01 : 1|1@1+ (1,0) [0|1] "" Vector__XXX
 SG_ KE1_res_16 : 16|16@1+ (1,0) [0|65535] "" Vector__XXX
 SG_ KE1_res_03 : 3|1@1+ (1,0) [0|1] "" Vector__XXX
 SG_ KE1_Umluftstellung : 4|4@1+ (10,0) [0|100] "%"  Hybrid_BMS
 SG_ KE1_res_02 : 2|1@1+ (1,0) [0|1] "" Vector__XXX

BO_ 1392 mBSG_Last: 5 Gateway_PQ46_A
 SG_ BSL_ZAS_Kl_50 : 3|1@1+ (1,0) [0|1] ""  TRW_ESP,Magne_Ride,EPB,Lenkhilfe_APA,Diesel
 SG_ BSL_Kl_L : 7|1@1+ (1,0) [0|1] ""  TRW_ESP
 SG_ BSL_ZAS_Kl_X : 2|1@1+ (1,0) [0|1] ""  TRW_ESP,EPB,HCA,Diesel,FLA
 SG_ BSL_ZAS_Kl_15 : 1|1@1+ (1,0) [0|1] ""  EPB,TRW_ESP,FLA
 SG_ BSL_Parklicht : 4|1@1+ (1,0) [0|1] ""  TRW_ESP
 SG_ BSL_ZAS_Kl_S : 0|1@1+ (1,0) [0|1] ""  TRW_ESP,EPB
 SG_ BSL_Motor_Haube : 15|1@1+ (1,0) [0|1] ""  TRW_ESP,Hybrid_MSG,Diesel,Otto
 SG_ BSL_Sta_UBat : 9|2@1+ (1,0) [0|3] ""  TRW_ESP
 SG_ BSL_Fehlereintr : 13|1@1+ (1,0) [0|1] ""  TRW_ESP
 SG_ BSL_LL_Anheb : 8|1@1+ (1,0) [0|1] ""  Diesel,Otto,TRW_ESP,Hybrid_MSG
 SG_ BSL_Frontsch : 25|1@1+ (1,0) [0|1] ""  TRW_ESP
 SG_ BSL_Sitzheiz : 27|1@1+ (1,0) [0|1] ""  TRW_ESP
 SG_ BSL_Lenkradheiz : 28|1@1+ (1,0) [0|1] ""  TRW_ESP
 SG_ BSL_Aussensp : 26|1@1+ (1,0) [0|1] ""  TRW_ESP
 SG_ BSL_Sitzbelueft : 30|1@1+ (1,0) [0|1] ""  TRW_ESP
 SG_ BSL_BSG_2_alt : 32|1@1+ (1,0) [0|1] ""  Diesel,Otto,TRW_ESP,Hybrid_MSG
 SG_ BSL_Hecksch : 24|1@1+ (1,0) [0|1] ""  TRW_ESP
 SG_ BSL_LL_Anheb2 : 5|1@1+ (1,0) [0|1] ""  Diesel,Otto,TRW_ESP,Hybrid_MSG
 SG_ BSL_Clima : 31|1@1+ (1,0) [0|1] ""  Diesel,Otto,TRW_ESP,Hybrid_MSG
 SG_ BSL_Weckursache_ACAN : 36|2@1+ (1,0) [0|3] ""  Otto,TRW_ESP,Hybrid_MSG
 SG_ BSL_BSG_3_alt : 33|1@1+ (1,0) [0|1] ""  Diesel,Otto,TRW_ESP,Hybrid_MSG,HCA,Lenkhilfe_APA,FLA
 SG_ BSL_Kl_15_Motor : 6|1@1+ (1,0) [0|1] ""  TRW_ESP
 SG_ BSL_UBat : 16|8@1+ (0.05,5) [5|17.7] "V"  TRW_ESP
 SG_ BSL_Kuehlerlueft : 34|1@1+ (1,0) [0|1] ""  Diesel,EPS,Otto,TRW_ESP,Hybrid_MSG,Lenkhilfe_ZF_3G
 SG_ BSL_Sta_LWR : 14|1@1+ (1,0) [0|1] ""  TRW_ESP
 SG_ BSL_Sta_StBat : 11|2@1+ (1,0) [0|3] ""  TRW_ESP
 SG_ BSL_Ab_Batterie : 35|1@1+ (1,0) [0|1] ""  Diesel,EPS,Otto,TRW_ESP,Lenkhilfe_APA,Hybrid_MSG,Lenkhilfe_ZF_3G
 SG_ BSL_Wasserheiz : 29|1@1+ (1,0) [0|1] ""  TRW_ESP
 SG_ BSL_Wake_Up_ACAN : 38|1@1+ (1,0) [0|1] ""  Otto,TRW_ESP,Hybrid_MSG
 SG_ BSL_Starterlaubnis : 39|1@1+ (1,0) [0|1] ""  TRW_ESP

BO_ 1394 mZAS_1: 1 Gateway_PQ46_A
 SG_ ZA1_S_Kontakt : 0|1@1+ (1,0) [0|1] ""  Diesel,Selespeed
 SG_ ZA1_Klemme_15 : 1|1@1+ (1,0) [0|1] ""  Diesel,Otto,PDC_PLA,Hybrid_MSG
 SG_ ZA1_Klemme_P : 4|1@1+ (1,0) [0|1] ""  Diesel
 SG_ ZA1_Klemme_X : 2|1@1+ (1,0) [0|1] ""  Diesel,AFS,PDC_PLA
 SG_ ZA1_Klemme_50 : 3|1@1+ (1,0) [0|1] ""  Diesel,Otto,AFS,Hybrid_MSG,Selespeed
 SG_ ZA1_Klemme_SV : 6|1@1+ (1,0) [0|1] "" Vector__XXX
 SG_ ZA1_Reserve3 : 12|3@1+ (1,0) [0|7] "" Vector__XXX
 SG_ ZA1_Reserve1 : 5|1@1+ (1,0) [0|1] "" Vector__XXX
 SG_ ZA1_Zaehler : 8|4@1+ (1,0) [0|15] "" Vector__XXX
 SG_ ZA1_Checksumme : 24|8@1+ (1,0) [0|255] "" Vector__XXX
 SG_ ZA1_Fehlereintr : 15|1@1+ (1,0) [0|1] "" Vector__XXX
 SG_ ZA1_res07 : 7|1@1+ (1,0) [0|1] "" Vector__XXX
 SG_ ZA1_Reserve4 : 16|8@1+ (1,0) [0|255] "" Vector__XXX

BO_ 1904 mTP_Dyn_ADR_1: 8 Gateway_PQ46_A
 SG_ TPDyn_ADR_1 : 0|64@1+ (1,0) [0|1.8446744074E+019] ""  ACC_Radar

BO_ 1864 mTP_Dyn_FLA_1: 8 Gateway_PQ46_A
 SG_ TPDyn_FLA_1 : 0|64@1+ (1,0) [0|1.8446744074E+019] ""  FLA

BO_ 1982 ISO_LWRAFS_Resp: 8 Vector_XXX
 SG_ ISO_LWRAFS_Resp_Data : 0|64@1+ (1,0) [0|1.8446744074E+019] ""  Gateway_PQ35_A,Gateway_PQ46_A

BO_ 1917 ISO_ABS_Resp: 8 Vector_XXX
 SG_ ISO_ABS_Resp_Data : 0|64@1+ (1,0) [0|1.8446744074E+019] ""  Gateway_PQ35_A,Gateway_PQ46_A

BO_ 2027 ISO_OBD_reserv1_Resp: 8 Vector_XXX
 SG_ ISO_OBD_reserv1_Resp_Data : 0|64@1+ (1,0) [0|1.8446744074E+019] ""  Gateway_PQ35_A,Gateway_PQ46_A

BO_ 2028 ISO_OBD_reserv2_Resp: 8 Vector_XXX
 SG_ ISO_OBD_reserv2_Resp_Data : 0|64@1+ (1,0) [0|1.8446744074E+019] ""  Gateway_PQ35_A,Gateway_PQ46_A

BO_ 2030 ISO_OBD_DMCM_Resp: 8 Vector_XXX
 SG_ ISO_OBD_DMCM_Resp_Data : 0|64@1+ (1,0) [0|1.8446744074E+019] ""  Gateway_PQ35_A,Gateway_PQ46_A

BO_ 2031 ISO_OBD_reserv5_Resp: 8 Vector_XXX
 SG_ ISO_OBD_reserv5_Resp_Data : 0|64@1+ (1,0) [0|1.8446744074E+019] ""  Gateway_PQ35_A,Gateway_PQ46_A

BO_ 2029 ISO_OBD_BECM_Resp: 8 Vector_XXX
 SG_ ISO_OBD_BECM_Resp_Data : 0|64@1+ (1,0) [0|1.8446744074E+019] ""  Gateway_PQ35_A,Gateway_PQ46_A

BO_ 2026 ISO_MOS_01_Resp: 8 Vector_XXX
 SG_ ISO_MOS_01_Resp_Data : 0|64@1+ (1,0) [0|1.8446744074E+019] ""  Gateway_PQ35_A,Gateway_PQ46_A

BO_ 1817 ISO_EKomp_Req: 8 Vector_XXX
 SG_ ISO_EKomp_Req_Data : 0|64@1+ (1,0) [0|1.8446744074E+019] ""  EKlimakomp

BO_TX_BU_ 1488 : Gateway_PQ46_A,Gateway_PQ35_A;
BO_TX_BU_ 2000 : Gateway_PQ46_A,Gateway_PQ35_A;
BO_TX_BU_ 1500 : Gateway_PQ46_A,Gateway_PQ35_A;
BO_TX_BU_ 1504 : Gateway_PQ46_A,Gateway_PQ35_A;
BO_TX_BU_ 1952 : Gateway_PQ46_A,Gateway_PQ35_A;
BO_TX_BU_ 1857 : Gateway_PQ46_A,Gateway_PQ35_A;
BO_TX_BU_ 1856 : Gateway_PQ46_A,Gateway_PQ35_A;
BO_TX_BU_ 1859 : Gateway_PQ46_A,Gateway_PQ35_A;
BO_TX_BU_ 512 : Gateway_PQ46_A,Gateway_PQ35_A;
BO_TX_BU_ 1858 : Gateway_PQ46_A,Gateway_PQ35_A;
BO_TX_BU_ 1893 : Gateway_PQ46_A,Gateway_PQ35_A;
BO_TX_BU_ 1906 : Gateway_PQ46_A,Gateway_PQ35_A;
BO_TX_BU_ 914 : Gateway_PQ46_A,Gateway_PQ35_A;
BO_TX_BU_ 1978 : Gateway_PQ46_A,Gateway_PQ35_A;
BO_TX_BU_ 1940 : Gateway_PQ46_A,Gateway_PQ35_A;
BO_TX_BU_ 1658 : Gateway_PQ46_A,Gateway_PQ35_A;
BO_TX_BU_ 2015 : Gateway_PQ46_A,Gateway_PQ35_A;
BO_TX_BU_ 1792 : Gateway_PQ46_A,Gateway_PQ35_A;
BO_TX_BU_ 2017 : Gateway_PQ46_A,Gateway_PQ35_A;
BO_TX_BU_ 2016 : Gateway_PQ46_A,Gateway_PQ35_A;
BO_TX_BU_ 1976 : Gateway_PQ46_A,Gateway_PQ35_A;
BO_TX_BU_ 1977 : Gateway_PQ46_A,Gateway_PQ35_A;
BO_TX_BU_ 1654 : Gateway_PQ46_A,Gateway_PQ35_A;
BO_TX_BU_ 2018 : Gateway_PQ46_A,Gateway_PQ35_A;
BO_TX_BU_ 2021 : Gateway_PQ46_A,Gateway_PQ35_A;
BO_TX_BU_ 2023 : Gateway_PQ46_A,Gateway_PQ35_A;
BO_TX_BU_ 2022 : Gateway_PQ46_A,Gateway_PQ35_A;
BO_TX_BU_ 2020 : Gateway_PQ46_A,Gateway_PQ35_A;
BO_TX_BU_ 2019 : Gateway_PQ46_A,Gateway_PQ35_A;
BO_TX_BU_ 1811 : Gateway_PQ46_A,Gateway_PQ35_A;
BO_TX_BU_ 1876 : Gateway_PQ46_A,Gateway_PQ35_A;
BO_TX_BU_ 1810 : Gateway_PQ46_A,Gateway_PQ35_A;
BO_TX_BU_ 1813 : Gateway_PQ46_A,Gateway_PQ35_A;
BO_TX_BU_ 1802 : Gateway_PQ46_A,Gateway_PQ35_A;
BO_TX_BU_ 1879 : Gateway_PQ46_A,Gateway_PQ35_A;
BO_TX_BU_ 1824 : Gateway_PQ46_A,Gateway_PQ35_A;
BO_TX_BU_ 1956 : Gateway_PQ46_A,Gateway_PQ35_A;
BO_TX_BU_ 1957 : Gateway_PQ46_A,Gateway_PQ35_A;
BO_TX_BU_ 2033 : Gateway_PQ46_A,Gateway_PQ35_A;
BO_TX_BU_ 1527 : Gateway_PQ46_A,Gateway_PQ35_A;
BO_TX_BU_ 1392 : Gateway_PQ46_A,Gateway_PQ35_A;
BO_TX_BU_ 1394 : Gateway_PQ46_A,Gateway_PQ35_A;
BO_TX_BU_ 1864 : Gateway_PQ35_A,Gateway_PQ46_A;
CM_ SG_ 1488 SY1_Diag_Ant "CAN-Antrieb in Diagnose
mindestens ein Teilnehmer hat die Diagnoseeröffnung auf dem CAN bestätigt; im PQ35/46 derzeit nicht unterstützt";
CM_ SG_ 1488 SY1_CAN_extern "CAN-Extern zugeschaltet
zweipoliger Schalter, der den CAN-Antrieb auf den Diagnosestecker legt, ist geschlossen oder es werden Nutzdaten des CAN-Antrieb auf den Diagnose-CAN gespiegelt";
CM_ SG_ 1488 SY1_Diag_Komf "CAN-Komfort in Diagnose
mindestens ein Teilnehmer hat die Diagnoseeröffnung auf dem Komfort-CAN bestätigt; im PQ35/46 derzeit nicht unterstützt";
CM_ SG_ 1488 SY1_Sleep_Info "Sleep CAN-Infotainment
CAN-Infotainment-Netzwerk schläft";
CM_ SG_ 1488 SY1_Sleep_Komf "Sleep CAN-Komfort
CAN-Komfort-Netzwerk schläft";
CM_ SG_ 1488 SY1_CAN_Info "CAN-Infotainment verbaut
der CAN-Infotainment ist vom CAN-Komfort physikalisch getrennt";
CM_ SG_ 1488 SY1_Diag_Info "CAN-Infotainment in Diagnose
mindestens ein Teilnehmer hat die Diagnoseeröffnung auf dem Infotainment-CAN bestätigt; im PQ35/46 derzeit nicht unterstützt";
CM_ SG_ 1488 SY1_Verbauinfo "Verbauinformation gültig
ungültig bedeutet: Verbauinformation ist noch nicht vollständig: Gateway nicht kodiert";
CM_ SG_ 1488 SY1_Fzg_Marke "Fahrzeug-Marke
Marke wird im Gateway-SG kodiert: Unkodierte PQ35-Gateway-SG geben '1' aus";
CM_ SG_ 1488 SY1_Fzg_Klasse "Fahrzeug-Klasse
bei PQ24 wird z.Zt. A0-Klasse ausgegeben";
CM_ SG_ 1488 SY1_Fzg_Index "Fahrzeug-Index
Im PQ35/46 derzeit nicht unterstützt: 15d für 'nicht bekannt' wird ausgegeben";
CM_ SG_ 1488 SY1_Fzg_Gen "Fahrzeug-Generation
z.B. 5 für PQ35";
CM_ SG_ 1488 SY1_Tueren "Viertürer
Info wird im Gateway-SG kodiert; Unkodierte PQ35/46-Gateway-SG geben 0 aus";
CM_ SG_ 1488 SY1_Fzg_Derivat "Fahrzeug-Derivat
Achtung: Derivate, die sich im Bordnetz nicht unterscheiden, werden ggfs. zusammengefaßtDerivat wird im Gateway-SG kodiert; Unkodierte PQ35/46-Gateway-SG geben 15d aus0 = Kurzheck oder Multivan; 1 = Stufenheck oder Nutzfzg.; 2 = Variant; 3 = Fliessheck; 4 = Coupe, Sportwagen; 5 = Cabrio, Roadstar, Spider; 6 = Offroad; 7 = CityVan, PickUp; 8 = MPV; 9 = sonstige; Nach Kenntnisstand des Senders'; Fh = nicht bekannt";
CM_ SG_ 1488 SY1_Lenker "Rechtslenker
Info wird im Gateway-SG kodiert; Unkodierte PQ35/46-Gateway-SG geben 0 aus";
CM_ SG_ 1488 SY1_Fehlereintr "Fehlerspeichereintrag (Systeminfo 1)
Bei gesetztem Bit ist mindestens ein KD-Fehler unter der Gateway Adresse abgelegt";
CM_ SG_ 1488 SY1_Komf_HV "CAN-Stand Komfort-Daten-Hauptversion
Anmerkung: das Gateway-Steuergerät erfüllt die Funktionalität dieser CAN-Version";
CM_ SG_ 1488 SY1_Transportmode "Transportmodus
1 = Transportmodus aktiv, funktionale Einschränkungen bzw. Änderungen für den Fzg.-Transport";
CM_ SG_ 1488 SY1_Ant_NV "CAN-Stand Antrieb-Daten-Nebenversion
Anmerkung: das Gateway-Steuergerät erfüllt die Funktionalität dieser CAN-Version";
CM_ SG_ 1488 SY1_Komf_NV "CAN-Stand Komfort-Daten-Nebenversion
Anmerkung: das Gateway-Steuergerät erfüllt die Funktionalität dieser CAN-Version";
CM_ SG_ 1488 SY1_Ant_HV "CAN-Stand Antrieb-Daten-Hauptversion
Anmerkung: das Gateway-Steuergerät erfüllt die Funktionalität dieser CAN-Version";
CM_ SG_ 1488 SY1_Notbrems_Status "Notbremsstatus
Gateway erkennt Notbremssituation (z. Zt. nur PQ46, PQ35 ab MJ07)";
CM_ SG_ 1488 SY1_ELV_Lock_Supply "Freigabe ELV verriegelt
Gateway gibt eine zusätzliche Freigabe für die ELV (elektrische Lenkradverriegelung) (z. Zt. nur PQ46)";
CM_ SG_ 1488 SY1_Relais_FAS_Zweig "CAN-Relais Zustand
FAS-Zweig (mit ACC, SWA,...) wird vom CAN-Antrieb über ein Relais abgetrennt:01: gewolltes Abschalten (zu schützende Kommunikation, z. B. im Hochlauf)10: nach zweimaligem BusOff bis ´Kl. 15´ aus abgetrennt(im PQ46 und Touareg GP, D1GP/BY61x)Hinweis: PQ46 bedient diese Bits auch dann, wenn die konkrete Hardwarevariante die Ansteuerung des Trennrelais nicht unterstütztFahrzeug-Konzepte ohne CAN-Relais schicken dauerhaft 00";
CM_ SG_ 1488 SY1_QRS_Messmodus "Quick-Ruhestrommessmodus (früher: Fabrikmodus)
1 = Quick-Ruhestrommessmodus (früher: Fabrikmodus), Fzg geht innerhalb 1min in Ruhestrom; siehe auch Lastenheft LH_TRM_QRS";
CM_ SG_ 1488 SY1_res52 " 
 ";
CM_ SG_ 1488 SY1_NWDF_gueltig "Netzwerk-Diagnose Freigabe gültig
Gültigkeit der Netzwerk-Diagnose Freigabe (Byte 7, Bit 7)";
CM_ SG_ 1488 SY1_res53 " 
 ";
CM_ SG_ 1488 SY1_res59 " 
 ";
CM_ SG_ 1488 SY1_NWDF "Netzwerk-Diagnose Freigabe
Netzwerk-Diagnose Freigabe zur zentralen Aktivierung der Netzwerkdiagnose";
CM_ SG_ 1488 SY1_res60 " 
 ";
CM_ SG_ 1488 SY1_res62 " 
 ";
CM_ SG_ 1488 SY1_res58 " 
 ";
CM_ SG_ 1488 SY1_res57 " 
 ";
CM_ SG_ 1488 SY1_res61 " 
 ";
CM_ SG_ 1488 SY1_res63 " 
 ";
CM_ SG_ 2000 DI1_Jahr "Jahr
0  für Datum unbekannt (z.B. keine Funkuhr)(bei relativem Datum ist auch der Wert 0 gültig siehe Spezifikation_Tageszähler_Kombi_01.doc)";
CM_ SG_ 2000 DI1_Minute "Minute
 ";
CM_ SG_ 2000 DI1_Monat "Monat
0 = Monat unbekannt; Dh = ungueltig; Eh = relatives Datum siehe Spezifikation_Tageszähler_Kombi_01.doc ; Fh = Keine Funkuhrinformation vorhanden und 12 h Anzeige (Monat, Tag, Jahr fehlen)";
CM_ SG_ 2000 DI1_Reserve1 " 
Reserviert für Time Indication Bit (Multiplex)";
CM_ SG_ 2000 DI1_km_Stand "KM Stand
Darstellung entspricht Kombi 3 (Byte 6...8)";
CM_ SG_ 2000 DI1_Sekunde "Sekunde
 ";
CM_ SG_ 2000 DI1_Stunde "Stunde
 ";
CM_ SG_ 2000 DI1_Tag "Tag
0  für Datum unbekannt (z.B. keine Funkuhr)(bei relativem Datum ist auch der Wert 0 gültig siehe Spezifikation_Tageszähler_Kombi_01.doc)";
CM_ SG_ 2000 DI1_KM_Stand_alt "Kilometerstand veraltet
Kilometerstand wurde aktuell (< 2 sec) vom Kombi empfangen";
CM_ SG_ 2000 DI1_Zeit_alt "Zeit veraltet
Zeit wurde aktuell (< 2 sec) vom Kombi empfangen";
CM_ SG_ 2000 DI1_VerlernZaehl "Verlernzähler
Binär, wrap aroundFFH: Fehler (ungültiger Zählerstand/ kein gültiger Fahrzyklus)";
CM_ SG_ 1500 VL1_Getr_SG "Getriebesteuergeraet
Getriebesteuergerät im CAN-Antrieb-Netzwerk (ggfs. auch Kupplungssteuergerät)   Anmerkungen: Bit auf 0 heißt nicht verbaut (Sollzustand) ; Initwert const bedeutet, daß der kodierte Zustand gesendet wird";
CM_ SG_ 1500 VL1_Airbag "Airbag
Airbag-Steuergerät im CAN-Antrieb-Netzwerk   Anmerkungen: Bit auf 0 heißt nicht verbaut (Sollzustand) ; Initwert const bedeutet, daß der kodierte Zustand gesendet wird";
CM_ SG_ 1500 VL1_Motor_SG "Motorsteuergeraet
Motorsteuergerät im CAN-Antrieb-Netzwerk   Anmerkungen: Bit auf 0 heißt nicht verbaut (Sollzustand) ; Initwert const bedeutet, daß der kodierte Zustand gesendet wird";
CM_ SG_ 1500 VL1_ABS "ABS
ABS-Steuergerät im CAN-Antrieb-Netzwerk (auch ASR-, ESP-Steuergerät)   Anmerkungen: Bit auf 0 heißt nicht verbaut (Sollzustand) ; Initwert const bedeutet, daß der kodierte Zustand gesendet wird";
CM_ SG_ 1500 VL1_res_08 " 
Reserviert für Niveauregulierung im CAN-Antrieb-Netzwerk  Anmerkungen: Bit auf 0 heißt nicht verbaut (Sollzustand) ; Initwert const bedeutet, daß der kodierte Zustand gesendet wird";
CM_ SG_ 1500 VL1_EPB "EPB
Parkbremse im CAN-Antrieb-Netzwerk oder am Bremsen-CAN   Anmerkungen: Bit auf 0 heißt nicht verbaut (Sollzustand) ; Initwert const bedeutet, daß der kodierte Zustand gesendet wird";
CM_ SG_ 1500 VL1_Kombi "Kombi am CAN-Antrieb
Kombi-Steuergerät  direkt im CAN-Antrieb-Netzwerk   Anmerkungen: Bit auf 0 heißt nicht verbaut (Sollzustand) ; Initwert const bedeutet, daß der kodierte Zustand gesendet wird";
CM_ SG_ 1500 VL1_Allrad "Allrad
Allradsteuergerät im CAN-Antrieb-Netzwerk Anmerkungen: Bit auf 0 heißt nicht verbaut (Sollzustand) ; Initwert const bedeutet, daß der kodierte Zustand gesendet wird";
CM_ SG_ 1500 VL1_LSM "LSM
LSM (Lenkwinkelsensor) im CAN-Antrieb-Netzwerk Anmerkungen: Bit auf 0 heißt nicht verbaut (Sollzustand) ; Initwert const bedeutet, daß der kodierte Zustand gesendet wird";
CM_ SG_ 1500 VL1_Lenkhilfe "Lenkhilfe
Lenkhilfe (Elektrohydraulische Servolenkung) im CAN-Antrieb-Netzwerk   Anmerkungen: Bit auf 0 heißt nicht verbaut (Sollzustand) ; Initwert const bedeutet, daß der kodierte Zustand gesendet wird";
CM_ SG_ 1500 VL1_ADR "ADR
ADR-Sensor im CAN-Antrieb-Netzwerk  Anmerkungen: Bit auf 0 heißt nicht verbaut (Sollzustand) ; Initwert const bedeutet, daß der kodierte Zustand gesendet wird";
CM_ SG_ 1500 VL1_Daempfer "Daempferregelung
Dämpferregelung im CAN-Antrieb-Netzwerk  Anmerkungen: Bit auf 0 heißt nicht verbaut (Sollzustand) ; Initwert const bedeutet, daß der kodierte Zustand gesendet wird";
CM_ SG_ 1500 VL1_dyn_LWR "Dynam. LWR / AFS
Dyn. Leuchtweitenregulierung / AFS im CAN-Antrieb-Netzwerk   Anmerkungen: Bit auf 0 heißt nicht verbaut (Sollzustand) ; Initwert const bedeutet, daß der kodierte Zustand gesendet wird";
CM_ SG_ 1500 VL1_DAB "DAB
DAB/SDARS-Tuner im CAN-Infotainment-Netzwerk (nur wenn Tuner mit eigener KD-Adresse eigendiagnosefähig)   Anmerkungen: Bit auf 0 heißt nicht verbaut (Sollzustand) ; Initwert const bedeutet, daß der kodierte Zustand gesendet wird";
CM_ SG_ 1500 VL1_MotorSlave "Motor Slave
Motor-Slave-Steuergerät im CAN-Antrieb-Netzwerk  Anmerkungen: Bit auf 0 heißt nicht verbaut (Sollzustand) ; Initwert const bedeutet, daß der kodierte Zustand gesendet wird";
CM_ SG_ 1500 VL1_res_13 " 
Reserviert für EZS (Elektronisches Zündanlaßschloß) im CAN-Antrieb-Netzwerk   Anmerkungen: Bit auf 0 heißt nicht verbaut (Sollzustand) ; Initwert const bedeutet, daß der kodierte Zustand gesendet wird";
CM_ SG_ 1500 VL1_TSG_BT "TSG_BT
Türsteuergerät Beifahrer (Fensterheber) ; im CAN-Komfort-Netzwerk   Anmerkungen: Bit auf 0 heißt nicht verbaut (Sollzustand) ; Initwert const bedeutet, daß der kodierte Zustand gesendet wird";
CM_ SG_ 1500 VL1_TSG_FT "TSG_FT
Türsteuergerät Fahrer (Fensterheber) ; im CAN-Komfort-Netzwerk   Anmerkungen: Bit auf 0 heißt nicht verbaut (Sollzustand) ; Initwert const bedeutet, daß der kodierte Zustand gesendet wird";
CM_ SG_ 1500 VL1_TSG_HL "TSG_HL
Türsteuergerät hinten links (Fensterheber) ; im CAN-Komfort-Netzwerk   Anmerkungen: Bit auf 0 heißt nicht verbaut (Sollzustand) ; Initwert const bedeutet, daß der kodierte Zustand gesendet wird";
CM_ SG_ 1500 VL1_ZKE "ZKE
Zentrale Komfort Elektronik (Komfortmodul) ; im CAN-Komfort-Netzwerk   Anmerkungen: Bit auf 0 heißt nicht verbaut (Sollzustand) ; Initwert const bedeutet, daß der kodierte Zustand gesendet wird";
CM_ SG_ 1500 VL1_BSG_Komf "BSG-Komfort
Bordnetzsteuergerät oder intelligentes Leistungsmodul (ILM) mit CAN-Komfort-Schnittstelle   Anmerkungen: Bit auf 0 heißt nicht verbaut (Sollzustand) ; Initwert const bedeutet, daß der kodierte Zustand gesendet wird";
CM_ SG_ 1500 VL1_Memory "Memory
Sitzmemory-Steuergerät (Fahrerseite) ; im CAN-Komfort-Netzwerk   Anmerkungen: Bit auf 0 heißt nicht verbaut (Sollzustand) ; Initwert const bedeutet, daß der kodierte Zustand gesendet wird";
CM_ SG_ 1500 VL1_Dachmodul_K "Dachmodul
Reserviert für Dachmodul / Dachdisplay; im CAN-Komfort-Netzwerk   Anmerkungen: Bit auf 0 heißt nicht verbaut (Sollzustand) ; Initwert const bedeutet, daß der kodierte Zustand gesendet wird";
CM_ SG_ 1500 VL1_TSG_HR "TSG_HR
Türsteuergerät hinten rechts (Fensterheber) ; im CAN-Komfort-Netzwerk   Anmerkungen: Bit auf 0 heißt nicht verbaut (Sollzustand) ; Initwert const bedeutet, daß der kodierte Zustand gesendet wird";
CM_ SG_ 1500 VL1_Zentralelektrik_II "Zentralelektrik II
Zentralelektrik II im CAN-Komfort-Netzwerk   Anmerkungen: Bit auf 0 heißt nicht verbaut (Sollzustand) ; Initwert const bedeutet, daß der kodierte Zustand gesendet wird";
CM_ SG_ 1500 VL1_Lenksaeule "Lenksaeulenmodul
Lenksäulenmodul (oder Multifunktionslenkrad) ; im CAN-Komfort-Netzwerk   Anmerkungen: Bit auf 0 heißt nicht verbaut (Sollzustand) ; Initwert const bedeutet, daß der kodierte Zustand gesendet wird";
CM_ SG_ 1500 VL1_Einparkhilfe "Einparkhilfe
Einparkhilfe im CAN-Komfort-Netzwerk   Anmerkungen: Bit auf 0 heißt nicht verbaut (Sollzustand) ; Initwert const bedeutet, daß der kodierte Zustand gesendet wird";
CM_ SG_ 1500 VL1_Gateway "Gateway
Gateway im CAN-Komfort-Netzwerk   Anmerkungen: Bit auf 0 heißt nicht verbaut (Sollzustand) ; Initwert const bedeutet, daß der kodierte Zustand gesendet wird";
CM_ SG_ 1500 VL1_RDK "Reifendruckkontrolle
Reifendruckkontrolle im CAN-Komfort-Netzwerk   Anmerkungen: Bit auf 0 heißt nicht verbaut (Sollzustand) ; Initwert const bedeutet, daß der kodierte Zustand gesendet wird";
CM_ SG_ 1500 VL1_PTC_Heizung "PTC-Heizung
PTC-Heizung im CAN-Komfort-Netzwerk  Anmerkungen: Bit auf 0 heißt nicht verbaut (Sollzustand) ; Initwert const bedeutet, daß der kodierte Zustand gesendet wird";
CM_ SG_ 1500 VL1_Standheiz "Standheizung
Standheizung im CAN-Komfort- oder CAN-Infotainment-Netzwerk   Anmerkungen: Bit auf 0 heißt nicht verbaut (Sollzustand) ; Initwert const bedeutet, daß der kodierte Zustand gesendet wird";
CM_ SG_ 1500 VL1_Clima_Komf "Klimasteuergerät_Komfort
Climatronic oder Halbautomat ; im CAN-Komfort-Netzwerk   Anmerkungen: Bit auf 0 heißt nicht verbaut (Sollzustand) ; Initwert const bedeutet, daß der kodierte Zustand gesendet wird";
CM_ SG_ 1500 VL1_res_42 " 
Reserviert für Wischermodul im CAN-Komfort / CAN-Infotainment-Netzwerk  Anmerkungen: Bit auf 0 heißt nicht verbaut (Sollzustand) ; Initwert const bedeutet, daß der kodierte Zustand gesendet wird";
CM_ SG_ 1500 VL1_RSE_I "Rear Seat Entertainment
RSE im CAN-Infotainment-Netzwerk   Anmerkungen: Bit auf 0 heißt nicht verbaut (Sollzustand) ; Initwert const bedeutet, daß der kodierte Zustand gesendet wird";
CM_ SG_ 1500 VL1_Verdeck "Verdecksteuergerät
Verdecksteuergerät / Grossdach im CAN-Komfort-Netzwerk   Anmerkungen: Bit auf 0 heißt nicht verbaut (Sollzustand) ; Initwert const bedeutet, daß der kodierte Zustand gesendet wird";
CM_ SG_ 1500 VL1_MDI_I "Mobile Device Interface
MDI im CAN-Infotainment-Netzwerk   Anmerkungen: Bit auf 0 heißt nicht verbaut (Sollzustand) ; Initwert const bedeutet, daß der kodierte Zustand gesendet wird";
CM_ SG_ 1500 VL1_Memory_BF "Sitzmemory Beifahrer
Sitzmemory Beifahrer im CAN-Komfort-Netzwerk   Anmerkungen: Bit auf 0 heißt nicht verbaut (Sollzustand) ; Initwert const bedeutet, daß der kodierte Zustand gesendet wird";
CM_ SG_ 1500 VL1_Heckdeckel "Heckdeckel-SG
Heckdeckel-SG im CAN-Komfort-Netzwerk   Anmerkungen: Bit auf 0 heißt nicht verbaut (Sollzustand) ; Initwert const bedeutet, daß der kodierte Zustand gesendet wird";
CM_ SG_ 1500 VL1_Anhaenger "Anhängersteuergerät
Anhängersteuergerät im CAN-Komfort-Netzwerk   Anmerkungen: Bit auf 0 heißt nicht verbaut (Sollzustand) ; Initwert const bedeutet, daß der kodierte Zustand gesendet wird";
CM_ SG_ 1500 VL1_Easy_Entry_VF "Easy Entry Fahrer
Easy Entry Fahrer im CAN-Komfort-Netzwerk   Anmerkungen: Bit auf 0 heißt nicht verbaut (Sollzustand) ; Initwert const bedeutet, daß der kodierte Zustand gesendet wird";
CM_ SG_ 1500 VL1_Sonderfzg_SG "Sonderfahrzeug-SG
Sonderfahrzeug-/ Multifunktions-SG am CAN-Komfort-Netzwerk   Anmerkungen: Bit auf 0 heißt nicht verbaut (Sollzustand) ; Initwert const bedeutet, daß der kodierte Zustand gesendet wird";
CM_ SG_ 1500 VL1_Tastenmodul "Tastenmodul
Tastenmodul im CAN-Infotainment-Netzwerk   Anmerkungen: Bit auf 0 heißt nicht verbaut (Sollzustand) ; Initwert const bedeutet, daß der kodierte Zustand gesendet wird";
CM_ SG_ 1500 VL1_Radio "Radio
Radio im CAN-Infotainment-Netzwerk   Anmerkungen: Bit auf 0 heißt nicht verbaut (Sollzustand) ; Initwert const bedeutet, daß der kodierte Zustand gesendet wird";
CM_ SG_ 1500 VL1_Telefon "Telefon
Telefon im CAN-Infotainment-Netzwerk    Anmerkungen: Bit auf 0 heißt nicht verbaut (Sollzustand) ; Initwert const bedeutet, daß der kodierte Zustand gesendet wird";
CM_ SG_ 1500 VL1_Navigation "Navigation
Navigation (auch RNS) im CAN-Infotainment-Netzwerk    Anmerkungen: Bit auf 0 heißt nicht verbaut (Sollzustand) ; Initwert const bedeutet, daß der kodierte Zustand gesendet wird";
CM_ SG_ 1500 VL1_Neigungsmodul_I "Neigungsmodul
Neigungsmodul im CAN-Infotainment-Netzwerk   Anmerkungen: Bit auf 0 heißt nicht verbaut (Sollzustand) ; Initwert const bedeutet, daß der kodierte Zustand gesendet wird";
CM_ SG_ 1500 VL1_ADR_getrennt "ADR getrennt
ADR-Sensor kann vom CAN-Antrieb abgetrennt werden:aktueller Zustand dieses Relais wird übertragenInitwert 0: Hardware ohne Abtrennmöglichkeit (z. Zt. PQ35)Initwert 1: Hardware mit bestückbarer Abtrennmöglichkeit (z. Zt. alle PQ46)";
CM_ SG_ 1500 VL1_DSP "DSP
DSP im CAN-Infotainment-Netzwerk   Anmerkungen: Bit auf 0 heißt nicht verbaut (Sollzustand) ; Initwert const bedeutet, daß der kodierte Zustand gesendet wird";
CM_ SG_ 1500 VL1_Easy_Entry_VB "Easy Entry Beifahrer
Easy Entry Beifahrer im CAN-Komfort-Netzwerk   Anmerkungen: Bit auf 0 heißt nicht verbaut (Sollzustand) ; Initwert const bedeutet, daß der kodierte Zustand gesendet wird";
CM_ SG_ 1500 VL1_Telematik "Telematik
Telematik im CAN-Infotainment-Netzwerk    Anmerkungen: Bit auf 0 heißt nicht verbaut (Sollzustand) ; Initwert const bedeutet, daß der kodierte Zustand gesendet wird";
CM_ SG_ 1500 VL1_TV_Tuner "TV-Tuner
TV-Tuner im CAN-Infotainment-Netzwerk   Anmerkungen: Bit auf 0 heißt nicht verbaut (Sollzustand) ; Initwert const bedeutet, daß der kodierte Zustand gesendet wird";
CM_ SG_ 1500 VL1_WFS_K "Wegfahrsperre am Komfort-CAN
Wegfahrsperre am CAN-Komfort-Netzwerk (z. B. PQ46)  Anmerkungen: Bit auf 0 heißt nicht verbaut (Sollzustand) ; Initwert const bedeutet, daß der kodierte Zustand gesendet wird";
CM_ SG_ 1500 VL1_Kompass "Kompass
Kompass im CAN-Infotainment-Netzwerk   Anmerkungen: Bit auf 0 heißt nicht verbaut (Sollzustand) ; Initwert const bedeutet, daß der kodierte Zustand gesendet wird";
CM_ SG_ 1500 VL1_Rearview "Rückfahrkamera
Rückfahrkamera im CAN-Infotainment-Netzwerk   Anmerkungen: Bit auf 0 heißt nicht verbaut (Sollzustand) ; Initwert const bedeutet, daß der kodierte Zustand gesendet wird";
CM_ SG_ 1500 VL1_GSM_Pager "GSM-Pager
GSM-Pager im CAN-Infotainment-Netzwerk   Anmerkungen: Bit auf 0 heißt nicht verbaut (Sollzustand) ; Initwert const bedeutet, daß der kodierte Zustand gesendet wird";
CM_ SG_ 1500 VL1_InfoElektronik "Informationselektronik
Informationselektronik im CAN-Infotainment-Netzwerk   Anmerkungen: Bit auf 0 heißt nicht verbaut (Sollzustand) ; Initwert const bedeutet, daß der kodierte Zustand gesendet wird";
CM_ SG_ 1500 VL1_Kombi_KBI "Kombi am Kombi-CAN
Kombiinstrument am Kombi-CAN   Anmerkungen: Bit auf 0 heißt nicht verbaut (Sollzustand) ; Initwert const bedeutet, daß der kodierte Zustand gesendet wird";
CM_ SG_ 1500 VL1_Soll_eq_Ist "Soll gleich Istverbau
Die ausgegebene Sollverbauliste ist identisch zur aktuell erkannten Istverbauliste";
CM_ SG_ 1500 VL1_Quersperre "Quersperre
Quersperre im CAN-Antrieb-Netzwerk";
CM_ SG_ 1500 VL1_SWA "SWA
SWA im CAN-Antrieb-Netzwerk";
CM_ SG_ 1500 VL1_PLA "PDC/PLA
PDC/PLA (Park-Lenk-Assistent) im CAN-Antrieb-Netzwerk  Anmerkungen: Bit auf 0 heißt nicht verbaut (Sollzustand) ; Initwert const bedeutet, daß der kodierte Zustand gesendet wird";
CM_ SG_ 1500 VL1_HCA "Heading Control
Heading Control im CAN-Antrieb-Netzwerk";
CM_ SG_ 1500 VL1_WFS_KBI "Wegfahrsperre am Kombi-CAN oder Antriebs-CAN
Wegfahrsperre am Kombi-CAN (z. B. PQ35) oder Antriebs-CAN (z. B. PQ25)  Anmerkungen: Bit auf 0 heißt nicht verbaut (Sollzustand) ; Initwert const bedeutet, daß der kodierte Zustand gesendet wird";
CM_ SG_ 1500 VL1_RKA_Plus "RKA Plus
Reifenkonrollanzeige (RKA Plus) im CAN-Antrieb-Netzwerk  Anmerkungen: Bit auf 0 heißt nicht verbaut (Sollzustand) ; Initwert const bedeutet, daß der kodierte Zustand gesendet wird";
CM_ SG_ 1504 CL1_Hecksch "Heizbare Heckscheibe
Im PQ35/46 wurde Taster/Schalter betätigt, d. h. nur Fahrerwunsch";
CM_ SG_ 1504 CL1_Heizleist "Keine Heizleistung gewünscht
keine Heizleistung bedeutet, daß der Temperaturregler auf blau eingestellt ist bzw. die Temperaturklappen auf 'kalt stehen (Audi)";
CM_ SG_ 1504 CL1_Fa_Zuheiz "Fahrerwunsch Zuheizer
nur TDI; gilt z.B. für Kühlwasser oder PTC-Heizung(im Hybrid Anforderung auf Lauf des VM zur Erhöhung der Abwärme für Heizleistung)";
CM_ SG_ 1504 CL1_Kompressor "Kompressorzustand
Zustand des Kompressors inc. 140msec Vorsteuerung ; (Achtung: PQ24 Halbautomat hat hier den AC-Schalter übertragen)";
CM_ SG_ 1504 CL1_Sta_Druck "Kältemitteldruck veraltet
 ";
CM_ SG_ 1504 CL1_Frontsch "Heizbare Frontscheibe
 ";
CM_ SG_ 1504 CL1_Sta_Moment "Kompressormoment veraltet
Bei Audi C5PA mit altem Kompressor immer 1";
CM_ SG_ 1504 CL1_Kompr_Last "Kompressorlast
Verlustmoment der Klimaanlage";
CM_ SG_ 1504 CL1_Druck "Klimadrucksignal
 ";
CM_ SG_ 1504 CL1_Aussentemp "Außentemperatur ungefiltert (Clima 1)
Die Klimaanlage wertet den Wasserkasten-Fühler (= Ansaugluft der Klimaanlage) aus und legt den Wert ungefiltert auf den Bus.  zu Außentemperatur ungefiltert (Byte 2): ;  ; Die Climatronic wertet den Wasserkastenfühler (nur Klima Fzg.) aus, das Kombi den Stoßstangenfühler (immer verbaut). Beide Steuergeräte ermitteln aus den ungefilterten Werten beider Sensoren die für sich relevante Temperatur. In Fahrzeugen ohne Climatronic arbeitet das Kombi automatisch nur mit eine";
CM_ SG_ 1504 CL1_Gebl_last "Gebläselast
Prozente vom Maximalwert (100%)";
CM_ SG_ 1504 CL1_Einheit_Temp "Temperatureinheit
die Temperaturanzeige für das Fahrzeug kann in der Klimaanlage umgestellt werden (z.Zt. nur Audi); bei VW PQ35/46 wird die angezeigte Einheit ausgegeben";
CM_ SG_ 1504 CL1_Luefter "Kühlerlüfteransteuerung (Clima 1)
Sollzustand der Kühlerlüfteransteuerung über die PWM Schnittstelle (Motor); Lüfterstufen (z.B. 14) werden in Prozente umgerechnet; Werte > 100% sind unzulässig, ; bei Audi ab B6 und C5PA";
CM_ SG_ 1504 CL1_Fehlereintr "Fehlerspeichereintrag (Clima 1)
Bei gesetztem Bit ist mindestens ein Kundendienstfehler eingetragen";
CM_ SG_ 1504 CL1_WAPU_Zuschaltung "Ein/ Ausschalten der Wasserpumpe
1 = Wasserpumpe ist nicht zugeschaltetEin/ Ausschalten der Wasserpumpe zwecks CO2 Einsparung";
CM_ SG_ 1504 CL1_Restwaerme "Restwärmefunktion
Status der Restwärmefunktion für das Motor-SG(Zur Zeit nur Colorado und T5)";
CM_ SG_ 1504 CL1_LL_Dz "Drehzahlanhebung
Signal für Leerlaufdrehzahlanhebung";
CM_ SG_ 1504 CL1_AC_Schalter "AC-Schalter oder Zustand
bei ´manueller Klimaanlage (Halbautomat) AC-Schalter;Zustand der Klimasteuerung beim Vollautomat (Aus = Klima ist im OFF-Modus): nicht im VW D1";
CM_ SG_ 1504 CL1_Temp_Stoss "Außentemperatur ungefiltert Stoßfänger
Die Klimaanlage wertet den Stoßstangen-Fühler aus (bisher nur im D1 und C5PA!) und legt den Wert ungefiltert auf den Bus(zuk. Neudefinition geplant wg. Motor Start-Stopp)";
CM_ SG_ 1504 CL1_PTC_Hzg "PTC_Heizung
Ansteuerung der PTC-Elemente 0...100% in 4 Stufen (0...175%)(zur Zeit nur D1 und Colorado)";
CM_ SG_ 1952 TPDyn_LWS "TP 2.0 Empfangskanal fuer Lenkwinkelsensor
LWS";
CM_ SG_ 1857 TPDyn_Motor_2 "TP 2.0 Empfangskanal 2 fuer Motor_SG
Motor";
CM_ SG_ 1856 TPDyn_Motor_1 "TP 2.0 Empfangskanal 1 fuer Motor_SG
Motor";
CM_ SG_ 1859 TPDyn_Motor_4 "TP 2.0 Empfangskanal 4 fuer Motor_SG
Motor";
CM_ SG_ 512 Tester_TP_Er "TP 2.0 Eroeffnungskanal
'Transportkanaleroeffnung vom Tester zu allen Steuergeraeten mit CAN-Diagnose; TP 2.0'";
CM_ SG_ 1858 TPDyn_Motor_3 "TP 2.0 Empfangskanal 3 fuer Motor_SG
Motor";
CM_ SG_ 1893 TPDyn_Allrad_2 "TP 2.0 Empfangskanal 2 fuer Allrad_SG
Allrad";
CM_ SG_ 1906 TPDyn_Daempfer_1 "TP 2.0 Empfangskanal 1 fuer Daempfer_SG
Dämpfer";
CM_ SG_ 1875 TPDyn_RKA_Plus_2 "TP 2.0 Empfangskanal 2 fuer RKA_Plus
RKA_Plus";
CM_ SG_ 1874 TPDyn_RKA_Plus_1 "TP 2.0 Empfangskanal 1 fuer RKA_Plus
RKA_Plus";
CM_ SG_ 914 GK2_Sta_Lichtsensor "Lichtsensor-Botschaft veraltet
mLichtsensor_1 - Botschaft nicht empfangen (100 msec)  oder  mRegen_Licht_Sensor-Botschaft nicht empfangen (200 msec)";
CM_ SG_ 914 GK2_Sta_Kessy_4 "Kessy4-Botschaft veraltet
mKessy_4-Botschaft nicht empfangen (400 msec)";
CM_ SG_ 914 GK2_res_09 " 
 ";
CM_ SG_ 914 GK2_Sta_LSM "LSM-Botschaft veraltet
LSM-Botschaft nicht empfangen (200 msec) (6 Byte DLC für LSM_1)";
CM_ SG_ 914 GK2_Helligkeit "Helligkeit
Signale bilden die Helligkeit, die der Lichtsensor empfängt";
CM_ SG_ 914 GK2_Sta_VSG "VSG1-Botschaft veraltet
VSG - Botschaft nicht empfangen (200 msec) ";
CM_ SG_ 914 GK2_Sta_Profil "Botschaft für Profil veraltet
Botschaft für Profilnummer nicht empfangen (2000 msec) ";
CM_ SG_ 914 GK2_Sta_Clima2 "Clima2-Botschaft veraltet
mClima2-Botschaft nicht empfangen (1600 ms)";
CM_ SG_ 914 GK2_Sta_Licht1 "Licht1-Botschaft veraltet
Licht - Botschaft nicht empfangen (100 msec) ";
CM_ SG_ 914 GK2_Feh_VLR "Fehler Vibrationslenkrad
 ";
CM_ SG_ 914 GK2_Sta_BSG4 "BSG4-Botschaft veraltet
mBSG4-Botschaft nicht empfangen (1000ms)";
CM_ SG_ 914 GK2_Blk_L_Kontrolle "Blinkerkontrollampe links
'1 = Kontrollampe Blinker links ein; 0 = Kontrollampe Blinker links aus'";
CM_ SG_ 914 GK2_Sta_Schluessel "Botschaft für Fahrberechtigungsschlüssel veraltet
Botschaft für Fahrberechtigungsschlüssel (Verweis auf Wegfahrsperre) nicht empfangen (200 msec) ";
CM_ SG_ 914 GK2_res_13 " 
 ";
CM_ SG_ 914 GK2_LS_KomFehler "Kommmunikationsfehler zwischen RS/LS und Master
Kommmunikationsfehler zwischen RS/LS und Master";
CM_ SG_ 914 GK2_VD_zu_ver "Verdeck geschlossen und verriegelt
1 = Zustand des Verdecks verriegelt und geschlossen";
CM_ SG_ 914 GK2_Blk_R_Kontrolle "Blinkerkontrollampe rechts
'1 = Kontrollampe Blinker rechts ein; 0 = Kontrollampe Blinker rechts aus'";
CM_ SG_ 914 GK2_VD_offen_ver "Verdeck offen und verriegelt
1 = Zustand des Verdecks geoeffnet und abgelegt (In Ablage verriegelt)";
CM_ SG_ 914 GK2_LS_def "Lichtsensor defekt
Fehlerhafte Daten vom LS trotz aktiver Kommunikation";
CM_ SG_ 914 GK2_Verdeck_Anf "Anforderung Verdeck
Abbild des Schalters zur Anfoprderung eines Verdeckbetriebes";
CM_ SG_ 914 GK2_VD_entriegelt "Verdeck bzw. Verdeckkastendeckel entriegelt
Verrriegeltzustand des Verdeck bzw. des Verdeckkastendeckel (VDKD)";
CM_ SG_ 914 GK2_VDKD_auf "Verdeckkastendeckel vollstaendig geoeffnet
Signal wird gesetzt, wenn der Verdeckkastendeckels vollstaendig geoeffnet ist";
CM_ SG_ 914 GK2_Schluessel "Nummer des Schluessels zur Fahrberechtigung
Im PQ35 gespiegelt aus mKombi_K1, Byte 5, Bit 3..0Im PQ46 gespiegelt aus mELV_Kessy_WFS, Byte 1, Bit 3..0(abhängig von der Position der WFS in der Fahrzeugarchitektur)";
CM_ SG_ 914 GK2_EM_LIN_ungueltig "EM_LIN_ungültig
Energie-LIN-Signale sind gültig vom Slave Batteriedatenmodul oder Generator";
CM_ SG_ 914 GK2_AFL_Schalter "Schalter in Stellung Assistenzfahrlicht
1 = Schalter in Stellung Assistenzfahrlicht";
CM_ SG_ 914 GK2_Hardtop "Hardtop montiert
1 = Hardtop ist montiert";
CM_ SG_ 914 GK2_Profil "Profil
Aktuelle ProfilnummerIm PQ35/46 gespiegelt aus mEinheiten, Byte 2, Bit 3..0";
CM_ SG_ 914 GK2_Kl_StSt_Info "Klima Start Stopp Info
Stopp-Freigabe/Start-Anforderung für den Start-Stopp-Koordinator";
CM_ SG_ 914 GK2_BEM_P_Generator "BEM_P_Generator
Mechanische Generatorleistung dient dem Motorsteuergerät zur Berechnung der Motorlast; Genauigkeit ca. +/- (500W + 20% vom Messwert)";
CM_ SG_ 914 GK2_BEM_Abschaltstufen "BEM_Abschaltstufen
Abschaltstufen des Ruhestrommanagements (Initialisierungswert aus EEPROM)";
CM_ SG_ 914 GK2_res_60 " 
 ";
CM_ SG_ 914 GK2_Nebelschluss "Kl83b Nebelschlussleuchte ein
1 = Nebelschlusslicht eingeschaltet";
CM_ SG_ 914 GK2_BSG_StSt_Info "BSG Start Stopp Info
Stopp-Freigabe/Start-Anforderung für den Start-Stopp-Koordinator";
CM_ SG_ 914 GK2_BEM_DFM "BEM_DFM
Generatorauslastungsgrad, vom Generator über LIN an das Gateway gesandt. Das Motorsteuergerät regelt auf dieses Signal die PTC, das Energiemanagement im BSG/BCM kalkuliert die Bordnetzauslastung";
CM_ SG_ 914 GK2_BEM_StSt_Info "BEM Start Stopp Info
Stopp-Freigabe/Start-Anforderung für den Start-Stopp-Koordinator";
CM_ SG_ 914 GK2_Kessy_StSt_Info "Kessy Start Stopp Info
Stopp-Freigabe/Start-Anforderung für den Start-Stopp-Koordinator";
CM_ SG_ 1978 TPDyn_PLA_PDC "TP 2.0 Empfangskanal fuer PLA_SG
PLA_PDC";
CM_ SG_ 1940 TPDyn_EPB_1 "TP 2.0 Empfangskanal 1 fuer EPB_SG
EPB";
CM_ SG_ 1880 TPDyn_Quersperre_1 "TP 2.0 Empfangskanal 1 fuer Quersperre_SG
Quersperre";
CM_ SG_ 1881 TPDyn_Quersperre_2 "TP 2.0 Empfangskanal 2 fuer Quersperre_SG
Quersperre";
CM_ SG_ 919 ZK5_Endlage_ausgefahren "Spoiler in Endlage ausgefahren
1 = Endlage erreicht";
CM_ SG_ 919 ZK5_Status_Spoiler "Status Spoiler
Status Spoiler (Spiegelung des WL-Bits zum Kombi)";
CM_ SG_ 919 ZK5_Endlage_eingefahren "Spoiler in Endlage eingefahren
1 = Endlage erreicht";
CM_ SG_ 919 ZK5_res_15 " 
 ";
CM_ SG_ 919 ZK5_Zaehler "Botschaftszaehler
Botschaftszaehler zur Erkennung fehlender ZKE_5-Botschaften; Definition gemaess Lastenheft";
CM_ SG_ 919 ZK5_Checksumme "Pruefsumme
Pruefsumme, Definition im CAN-Lastenheft";
CM_ SG_ 919 ZK5_VD_Endlage_geschl "Verdeck geschlossen, Endlage erreicht
Verdeck geschlossen und Endlage erreicht";
CM_ SG_ 919 ZK5_VD_Endlage_abgelegt "Verdeck abgelegt, Endlage erreicht
Verdeck geoeffnet und in Endlage abgelegt";
CM_ SG_ 919 ZK5_VD_Verbau "Verbau man oder autom Verdeck
Verbau manuelles oder automatisches Verdeck";
CM_ SG_ 919 ZK5_res_20 " 
 ";
CM_ SG_ 919 ZK5_res_21 " 
 ";
CM_ SG_ 919 ZK5_res_22 " 
 ";
CM_ SG_ 919 ZK5_res_19 " 
 ";
CM_ SG_ 919 ZK5_res_23 " 
 ";
CM_ SG_ 919 ZK5_res_24 " 
 ";
CM_ SG_ 919 ZK5_res_25 " 
 ";
CM_ SG_ 919 ZK5_res_26 " 
 ";
CM_ SG_ 919 ZK5_res_27 " 
 ";
CM_ SG_ 919 ZK5_res_29 " 
 ";
CM_ SG_ 919 ZK5_res_31 " 
 ";
CM_ SG_ 919 ZK5_res_32 " 
 ";
CM_ SG_ 919 ZK5_res_33 " 
 ";
CM_ SG_ 919 ZK5_res_34 " 
 ";
CM_ SG_ 919 ZK5_res_30 " 
 ";
CM_ SG_ 919 ZK5_res_35 " 
 ";
CM_ SG_ 919 ZK5_res_28 " 
 ";
CM_ SG_ 919 ZK5_res_36 " 
 ";
CM_ SG_ 919 ZK5_res_37 " 
 ";
CM_ SG_ 919 ZK5_res_38 " 
 ";
CM_ SG_ 919 ZK5_res_40 " 
 ";
CM_ SG_ 919 ZK5_res_41 " 
 ";
CM_ SG_ 919 ZK5_res_42 " 
 ";
CM_ SG_ 919 ZK5_res_45 " 
 ";
CM_ SG_ 919 ZK5_res_46 " 
 ";
CM_ SG_ 919 ZK5_res_39 " 
 ";
CM_ SG_ 919 ZK5_res_47 " 
 ";
CM_ SG_ 919 ZK5_res_48 " 
 ";
CM_ SG_ 919 ZK5_res_49 " 
 ";
CM_ SG_ 919 ZK5_res_50 " 
 ";
CM_ SG_ 919 ZK5_res_51 " 
 ";
CM_ SG_ 919 ZK5_res_44 " 
 ";
CM_ SG_ 919 ZK5_res_52 " 
 ";
CM_ SG_ 919 ZK5_res_43 " 
 ";
CM_ SG_ 919 ZK5_res_53 " 
 ";
CM_ SG_ 919 ZK5_res_54 " 
 ";
CM_ SG_ 919 ZK5_res_55 " 
 ";
CM_ SG_ 919 ZK5_res_56 " 
 ";
CM_ SG_ 919 ZK5_res_57 " 
 ";
CM_ SG_ 919 ZK5_res_58 " 
 ";
CM_ SG_ 919 ZK5_res_59 " 
 ";
CM_ SG_ 919 ZK5_res_60 " 
 ";
CM_ SG_ 919 ZK5_res_63 " 
 ";
CM_ SG_ 919 ZK5_res_62 " 
 ";
CM_ SG_ 919 ZK5_res_61 " 
 ";
CM_ SG_ 1658 BAP_var_Anzeige_02 " 
 ";
CM_ SG_ 1658 BAP_Data_Anzeige_02 " 
 ";
CM_ SG_ 1530 Data_Byte_1_19 "Datenbyte 1
Festlegung der Datenbytes siehe CAN Data Exchange Function Datenfestlegung";
CM_ SG_ 1530 Data_Byte_2_19 "Datenbyte 2
Festlegung der Datenbytes siehe CAN Data Exchange Function Datenfestlegung";
CM_ SG_ 1530 Controller_ID_19 " 
 ";
CM_ SG_ 1530 Data_Byte_3_19 "Datenbyte 3
Festlegung der Datenbytes siehe CAN Data Exchange Function Datenfestlegung";
CM_ SG_ 1530 Data_Byte_4_19 "Datenbyte 4
Festlegung der Datenbytes siehe CAN Data Exchange Function Datenfestlegung";
CM_ SG_ 1530 CDEF_AB_APS_res_19 " 
 ";
CM_ SG_ 1530 Module_ID_19 "APS
 ";
CM_ SG_ 1530 OpCode_19 " 
 ";
CM_ SG_ 1530 Update_Indikator_19 " 
 ";
CM_ SG_ 1530 Funktions_ID_19 " 
 ";
CM_ SG_ 1530 Data_Byte_5_19 "Datenbyte 5
Festlegung der Datenbytes siehe CAN Data Exchange Function Datenfestlegung";
CM_ SG_ 2015 ISO_OBD_01_Req_Data "ISO Request Kanal
 ";
CM_ SG_ 1792 ISO_ALL_01_Req_Data "ISO Request Kanal
 ";
CM_ SG_ 2017 ISO_Getriebe_01_Req_Data "ISO Request Kanal
 ";
CM_ SG_ 2016 ISO_MO_01_Req_Data "ISO Request Kanal
 ";
CM_ SG_ 1976 TPDyn_SWA_1 "TP 2.0 Empfangskanal fuer SWA_SG
SWA";
CM_ SG_ 1977 TPDyn_SWA_2 "TP 2.0 Empfangskanal fuer SWA_SG
SWA";
CM_ SG_ 1654 BAP_var_Anzeige " 
 ";
CM_ SG_ 1654 BAP_Data_Anzeige " 
 ";
CM_ SG_ 2018 ISO_MOS_01_Req_Data "ISO Request Kanal
 ";
CM_ SG_ 2021 ISO_OBD_BECM_Req_Data "ISO Request Kanal
 ";
CM_ SG_ 2023 ISO_OBD_reserv5_Req_Data "ISO Request Kanal
 ";
CM_ SG_ 2022 ISO_OBD_DMCM_Req_Data "ISO Request Kanal
 ";
CM_ SG_ 2020 ISO_OBD_reserv2_Req_Data "ISO Request Kanal
 ";
CM_ SG_ 2019 ISO_OBD_reserv1_Req_Data "ISO Request Kanal
 ";
CM_ SG_ 1811 ISO_ABS_Req_Data "ISO Request Kanal
 ";
CM_ SG_ 1876 ISO_LWRAFS_Req_Data "ISO Request Kanal
 ";
CM_ SG_ 1810 ISO_Lenkhilfe_Req_Data "ISO Request Kanal
 ";
CM_ SG_ 1813 ISO_Airbag_01_Req_Data "ISO Request Kanal
 ";
CM_ SG_ 1802 ISO_EPH_Req_Data "ISO Request Kanal
 ";
CM_ SG_ 1879 ISO_ACC_Req_Data "ISO Request Kanal
 ";
CM_ SG_ 1824 NMH_GW_Abschaltstufe_aktiv " 
1 = Funktionsabschaltung wegen Abschaltstufe";
CM_ SG_ 1824 NMH_GW_Car_WakeUp " 
Car WakeUp optional";
CM_ SG_ 1824 NMH_GW_Eindraht_Fehler " 
1 = Eindrahtbetrieb erkannt";
CM_ SG_ 1824 NMH_GW_Fkt_WakeUp " 
´Weckursache Funktion´0 = wenn Peripheriewakeup1 = Antriebs-CAN-Ereignis fordert diesen Bus2 = Kombi-CAN-Ereignis fordert diesen Bus3 = Komfort-CAN-Ereignis fordert diesen Bus4 = Infotainment-CAN-Ereignis fordert diesen Bus5 = Extended-CAN-Ereignis fordert diesen Bus6 = LIN1-CAN-Ereignis fordert diesen Bus7 = LIN2-CAN-Ereignis fordert diesen Bus";
CM_ SG_ 1824 NMH_GW_kein_NL " 
kein lokaler / SG interner Nachlauf vor Wakeup";
CM_ SG_ 1824 NMH_GW_KompSchutz " 
1 = Funktionseinschränkung aufgrund Komponentenschutz / WFS aktiv";
CM_ SG_ 1824 NMH_GW_Mute_Mode " 
1 = Funktionseinschränkung aufgrund Mute Mode aktiv, nur VW";
CM_ SG_ 1824 NMH_GW_CAN_Diag_deaktiv " 
1 = Keine CAN Bus bezogene Eigendiagnose";
CM_ SG_ 1824 NMH_GW_NL_1 " 
Nachlauf 1";
CM_ SG_ 1824 NMH_GW_NL_2 " 
Nachlauf 2";
CM_ SG_ 1824 NMH_GW_NL_3 " 
Nachlauf 3";
CM_ SG_ 1824 NMH_GW_NL_4 " 
Nachlauf 4";
CM_ SG_ 1824 NMH_GW_NL_5 " 
Nachlauf 5";
CM_ SG_ 1824 NMH_GW_NL_6 " 
Nachlauf 6";
CM_ SG_ 1824 NMH_GW_NL_7 " 
Nachlauf 7";
CM_ SG_ 1824 NMH_GW_NL_aktiv_5 " 
Nachlaufursache 51 = Komfort-CAN fordert Antriebs-CAN (ACAN)1 = Kombi fordert Komfort oder Kombi-Sleep-Indication-Bit (KombiCAN)";
CM_ SG_ 1824 NMH_GW_NL_aktiv_6 " 
Nachlaufursache 61 = Antriebs-CAN-Nachlauf (inkl. NM-High) (KombiCAN)";
CM_ SG_ 1824 NMH_GW_NL_aktiv_7 " 
Nachlaufursache 71 = Infortainment-CAN aktiv (KombiCAN)";
CM_ SG_ 1824 NMH_GW_NL_aktiv_8 " 
Nachlaufursache 81 = Komfort-CAN aktiv (KombiCAN)";
CM_ SG_ 1824 NMH_GW_NM_aktiv_Diagnose " 
NM-Nachlaufursache, nicht ´Ready To Sleep´1 = Diagnose bei Kl 15 aus";
CM_ SG_ 1824 NMH_GW_NM_aktiv_Klemme_15 " 
NM-Nachlaufursache, nicht ´Ready To Sleep´1 = Klemme 15 ein";
CM_ SG_ 1824 NMH_GW_NL_aktiv_4 " 
Nachlaufursache 41 = ACAN-Nachlauf über Sleep-Indication-Bit (ACAN)1 = Kombi-Wakeup-Leitung aktiv (KombiCAN)";
CM_ SG_ 1824 NMH_GW_NM_aktiv_Start " 
NM-Nachlaufursache, nicht ´Ready To Sleep´1 = Mindestaktivzeit Zustand ´Start´";
CM_ SG_ 1824 NMH_GW_Normal_Mode_1 " 
Zustand Normal Mode (<-- Start)";
CM_ SG_ 1824 NMH_GW_Normal_Mode_2 " 
Zustand Normal Mode (<-- Ready to Sleep)";
CM_ SG_ 1824 NMH_GW_Per_WakeUp " 
Weckurasche Peripherie0 = wenn Funktionswakeup1 = CAN2 = P-Wakeup, Ursache nicht bekannt3 = KL 15 HW (falls vorhanden)6 = Weckereignis am Komfort-CAN-Transceiver erkannt7 = Weckereignis am Infotainment-CAN-Transceiver erkannt9 = Weckereignis am LIN1-Transceiver erkannt11 = Weckereignis an der (Kombi-)Wakeup-Leitung";
CM_ SG_ 1824 NMH_GW_res_04 " 
 ";
CM_ SG_ 1824 NMH_GW_res_05 " 
 ";
CM_ SG_ 1824 NMH_GW_res_32 " 
 ";
CM_ SG_ 1824 NMH_GW_res_07 " 
 ";
CM_ SG_ 1824 NMH_GW_res_41 " 
 ";
CM_ SG_ 1824 NMH_GW_res_42 " 
 ";
CM_ SG_ 1824 NMH_GW_res_43 " 
 ";
CM_ SG_ 1824 NMH_GW_res_44 " 
 ";
CM_ SG_ 1824 NMH_GW_res_45 " 
 ";
CM_ SG_ 1824 NMH_GW_res_46 " 
 ";
CM_ SG_ 1824 NMH_GW_res_40 " 
 ";
CM_ SG_ 1824 NMH_GW_res_47 " 
 ";
CM_ SG_ 1824 NMH_GW_res_48 " 
 ";
CM_ SG_ 1824 NMH_GW_res_49 " 
 ";
CM_ SG_ 1824 NMH_GW_res_50 " 
 ";
CM_ SG_ 1824 NMH_GW_res_52 " 
 ";
CM_ SG_ 1824 NMH_GW_res_53 " 
 ";
CM_ SG_ 1824 NMH_GW_res_54 " 
 ";
CM_ SG_ 1824 NMH_GW_res_55 " 
 ";
CM_ SG_ 1824 NMH_GW_Start_1 " 
Zustand Start (<--Sleep)";
CM_ SG_ 1824 NMH_GW_res_51 " 
 ";
CM_ SG_ 1824 NMH_GW_Start_2 " 
Zustand Start (<--Prepare to Sleep)";
CM_ SG_ 1824 NMH_GW_TimeOut_Fehler " 
1 = Timeout Fehlerspeichereintrag";
CM_ SG_ 1824 NMH_GW_Transport_Mode " 
1 = Funktionseinschränkung aufgrund Transport Mode aktiv";
CM_ SG_ 1956 TPDyn_LDW_1 "TP 2.0 Empfangskanal fuer LDW_SG
LDW";
CM_ SG_ 1957 TPDyn_LDW_2 "TP 2.0 Empfangskanal fuer LDW_SG
LDW";
CM_ SG_ 2033 Req_Airbag_Deployment " 
 ";
CM_ SG_ 1527 KE1_Comp_rev_rq "KE1_Comp_rev_rq
Requested compressor revolution0, 800-8600 rpmbelow 800 rpm = compressor stop800 - 8600 rpm = operationover 8600 rpm = compressor stop";
CM_ SG_ 1527 KE1_Comp_enable "KE1_Comp_enable
Enable to start for compressorAfter 1 second when High-voltage becomes available, turn on '1'";
CM_ SG_ 1527 KE1_res_01 " 
 ";
CM_ SG_ 1527 KE1_res_16 " 
 ";
CM_ SG_ 1527 KE1_res_03 " 
 ";
CM_ SG_ 1527 KE1_Umluftstellung "Umluftstellung
Reserviert für Umluftstellung 0-100%";
CM_ SG_ 1527 KE1_res_02 " 
 ";
CM_ SG_ 1392 BSL_ZAS_Kl_50 "ZAS_Klemme_50
Klemme 50:PQ24: ZündanlaßschloßPQ35: Ausgang 'Klemme 50'D1/Colorado: Bit nicht bedient";
CM_ SG_ 1392 BSL_Kl_L "Klemme_L
Klemme L (Ladekontrolllampe)";
CM_ SG_ 1392 BSL_ZAS_Kl_X "ZAS_Klemme_X
Klemme X (Startvorgang):PQ24: Zündanlaßschloß;PQ35: Ausgang Klemme X (75)D1/Colorado: Bit nicht bedient0: Grundzustand (Initialisierungswert ) => kein Startvorgang => UKlemme X = 12 V => Nebenverbraucher über Relais zugeschaltet1: Klemme X aktiv => Startvorgang => UKlemme X = 0 V => Nebenverbraucher über Relais abgeschaltet";
CM_ SG_ 1392 BSL_ZAS_Kl_15 "ZAS_Klemme_15
Klemme 15 (Zuendung ein):PQ24: Zündanlaßschloß Klemme 15PQ35: Ist-Zustand Klemme 15 InnenraumD1/Colorado: Bit nicht bedient";
CM_ SG_ 1392 BSL_Parklicht "ZAS_Parklicht
Klemme P:PQ35: aus 'mZAS_Status' gespiegeltPQ24/D1/Colorado: Bit nicht bedient";
CM_ SG_ 1392 BSL_ZAS_Kl_S "ZAS_Klemme_S
S-Kontakt (Schluessel steckt):PQ24: Zündanlaßschloß;PQ35: aus 'mZAS_Status' gespiegelt;D1/Colorado: Bit nicht bedient ";
CM_ SG_ 1392 BSL_Motor_Haube "Motorhaubenkontakt
Status des Motorhaubenkontaktes";
CM_ SG_ 1392 BSL_Sta_UBat "Zustand der Bordnetzbatterie
Zustandssignalisierung für die Bordnetzbatterie";
CM_ SG_ 1392 BSL_Fehlereintr "Fehlerspeichereintrag (BSG_Last)
Bei gesetztem Bit ist mindestens ein Kundendienstfehler eingetragen";
CM_ SG_ 1392 BSL_LL_Anheb "LL-Drehzahlanhebung Stufe 1
Das Bit wird gesetzt, wenn Lastmanagement im BSG Leerlauf-Drehzahlanhebung auf Stufe 1 fordert.";
CM_ SG_ 1392 BSL_Frontsch "Heizbare_Frontscheibe abschalten
Auforderung vom Lastmanagement zur Abschaltung der heizbaren Frontscheibe";
CM_ SG_ 1392 BSL_Sitzheiz "Heizbare_Sitze abschalten
Auforderung vom Lastmanagement zur Abschaltung der heizbaren Sitze";
CM_ SG_ 1392 BSL_Lenkradheiz "Lenkradheizung abschalten
Auforderung vom Lastmanagement zur Abschaltung der Lenkradheizung";
CM_ SG_ 1392 BSL_Aussensp "Heizbare_Aussenspiegel abschalten
Auforderung vom Lastmanagement zur Abschaltung der heizbaren Außenspiegel";
CM_ SG_ 1392 BSL_Sitzbelueft "Sitzbelüftung abschalten
Auforderung vom Lastmanagement zur Abschaltung der Sitzbelüftung";
CM_ SG_ 1392 BSL_BSG_2_alt "BSG_2 veraltet
mBSG_2 Botschaft nicht empfangen (1 Sekunde)";
CM_ SG_ 1392 BSL_Hecksch "Heizbare_Heckscheibe abschalten
Auforderung vom Lastmanagement zur Abschaltung der heizbaren Heckscheibe";
CM_ SG_ 1392 BSL_LL_Anheb2 "LL-Drehzahlanhebung Stufe 2
Das Bit wird gesetzt, wenn Lastmanagement im BSG Leerlauf-Drehzahlanhebung auf Stufe 2 fordert: Drehzahl Stufe 2 > Drehzahl Stufe 1 (nicht PQ24)";
CM_ SG_ 1392 BSL_Clima "Klimaanlage abschalten
Auforderung vom Lastmanagement zur Abschaltung der Klimanlage";
CM_ SG_ 1392 BSL_Weckursache_ACAN "Weckursache A-CAN
Abhängig von der genannten Weckursache wird eine entsprechende Kraftstoffpumpen-Vorförderung angesteuert. Die Dauer der Vorförderung wird vom MSG anhand der Weckursache bestimmt (ggf. auch bedarfsgeregelt). Anschließend schaltet sich das MSG wieder ab (Info aus mBSG_2, Byte 6, Bit 4,3 gespiegelt)";
CM_ SG_ 1392 BSL_BSG_3_alt "BSG_3 veraltet
mBSG_3 Botschaft nicht empfangen (400 msec)";
CM_ SG_ 1392 BSL_Kl_15_Motor "Klemme 15 Motorraum
Klemme 15 Motorraum (= Klemme 14) ist aktiv";
CM_ SG_ 1392 BSL_UBat "Batteriespannung Bordnetzbatterie
Spannungsmessung vom Lastmanagement (Bordnetzbatterie)";
CM_ SG_ 1392 BSL_Kuehlerlueft "Kühlerlüfter einschalten
Zur Spannungsstabilisierung für Hochstromverbraucher bei Batteriedefekt (Bit aus mBSG3, Byte 3, Bit 2  gespiegelt)";
CM_ SG_ 1392 BSL_Sta_LWR "Leuchtweitenregulierung
Statusanzeige der Leuchtweitenregulierung (nicht PQ35)";
CM_ SG_ 1392 BSL_Sta_StBat "Zustand der Starterbatterie
Zustandssignalisierung für die Starterbatterie (nicht PQ35)";
CM_ SG_ 1392 BSL_Ab_Batterie "Batterie-Ab erkannt
Batterie-Ab-Erkennung:Info aus mBSG3, Byte 3, Bit 3 gespiegelt";
CM_ SG_ 1392 BSL_Wasserheiz "Wischwasserheizung abschalten
Auforderung vom Lastmanagement zur Abschaltung der Wischwasserheizung (nicht PQ35)";
CM_ SG_ 1392 BSL_Wake_Up_ACAN "Wecken A-CAN
Das Gateway weckt bei gesetztem Bit (Info aus mBSG_2, Byte 4, Bit 7 gespiegelt) den A-CAN. Das MSG plausibilisiert bei gesetztem Bit die Weckursache (BSG_Last, Byte 5, Bit 5,4)";
CM_ SG_ 1392 BSL_Starterlaubnis "Starterlaubnis
Bit wird gesetzt, wenn Kupplung getreten (Interlock-Schalter) oder Getriebe-Wählhebel in PN-Stellung";
CM_ SG_ 1394 ZA1_S_Kontakt "S-Kontakt (Schluessel steckt)
Schlüsselschalterkontakt geschlossen";
CM_ SG_ 1394 ZA1_Klemme_15 "Klemme 15 (Zuendung ein)
Im PQ35 nur Soll-Zustand";
CM_ SG_ 1394 ZA1_Klemme_P "Klemme P (Parklichtstellung)
 ";
CM_ SG_ 1394 ZA1_Klemme_X "Klemme X (Startvorgang)
Klemme X (Kl.75) entspricht der Klemme 15 außer im Startvorgang0: Grundzustand (Initialisierungswert ) => kein Startvorgang => UKlemme X = 12 V => Nebenverbraucher über Relais zugeschaltet1: Klemme X aktiv => Startvorgang => UKlemme X = 0 V => Nebenverbraucher über Relais abgeschaltet";
CM_ SG_ 1394 ZA1_Klemme_50 "Klemme 50 (Starten)
Anlasser wird bestromt oder Fahrer fordert den Motorstart anIm PQ35 nur Soll-Zustand";
CM_ SG_ 1394 ZA1_Klemme_SV "Klemme 15 SV
Im VW D1 / Colorado sind Startrelevante Kl. 15 Verbraucher nur ueber Kl. 15 SV versorgt; Im Audi D3 wird der Status der ´KL 15-CAN´ ausgegeben";
CM_ SG_ 1394 ZA1_Reserve3 " 
 ";
CM_ SG_ 1394 ZA1_Reserve1 " 
 ";
CM_ SG_ 1394 ZA1_Zaehler "Zähler (ZAS 1)
überlaufender Botschaftszähler zur Lebenderkennung (nicht VW D1/Colorado)";
CM_ SG_ 1394 ZA1_Checksumme "Checksumme
Prüfsumme, Definition im CAN Lastenheft (nicht VW D1/Colorado)";
CM_ SG_ 1394 ZA1_Fehlereintr "Fehlerspeichereintrag (ZAS 1)
Bei gesetztem Bit ist mindestens ein Kundendienstfehler eingetragen";
CM_ SG_ 1394 ZA1_res07 " 
 ";
CM_ SG_ 1394 ZA1_Reserve4 " 
 ";
CM_ SG_ 1904 TPDyn_ADR_1 "TP 2.0 Empfangskanal 1 fuer ADR_SG
ADR";
CM_ SG_ 1864 TPDyn_FLA_1 "TP 2.0 Empfangskanal 1 fuer FLA_SG
Quersperre";
CM_ SG_ 1982 ISO_LWRAFS_Resp_Data "ISO Response Kanal
 ";
CM_ SG_ 1917 ISO_ABS_Resp_Data "ISO Response Kanal
 ";
CM_ SG_ 2027 ISO_OBD_reserv1_Resp_Data "ISO Response Kanal
 ";
CM_ SG_ 2028 ISO_OBD_reserv2_Resp_Data "ISO Response Kanal
 ";
CM_ SG_ 2030 ISO_OBD_DMCM_Resp_Data "ISO Response Kanal
 ";
CM_ SG_ 2031 ISO_OBD_reserv5_Resp_Data "ISO Response Kanal
 ";
CM_ SG_ 2029 ISO_OBD_BECM_Resp_Data "ISO Response Kanal
 ";
CM_ SG_ 2026 ISO_MOS_01_Resp_Data "ISO Response Kanal
 ";
CM_ SG_ 1817 ISO_EKomp_Req_Data "ISO Request Kanal
 ";
BA_DEF_ BO_  "VAGTP20_API" HEX 0 255;
BA_DEF_ BO_  "VAGTP20_StatConnection" ENUM  "No","Yes";
BA_DEF_ BO_  "VAGTP20_DynConnection" ENUM  "No","Yes";
BA_DEF_ BO_  "VAGTP20_DynSetup" ENUM  "No","Yes";
BA_DEF_ BO_  "NmMessage" ENUM  "No","Yes";
BA_DEF_ BO_  "NmhMessage" ENUM  "No","Yes";
BA_DEF_ BO_  "GenMsgCycleTime" INT 0 65535;
BA_DEF_ BO_  "GenMsgSendType" ENUM  "cyclicX","spontanX","cyclicIfActiveX","spontanWithDelay","cyclicAndSpontanX","cyclicAndSpontanWithDelay","spontanWithRepitition","cyclicIfActiveAndSpontanWD","NoMsgSendType","cyclicWithRepeatOnDemand";
BA_DEF_ BO_  "GenMsgCycleTimeFast" INT 0 65535;
BA_DEF_ BO_  "GenMsgNrOfRepetition" INT 0 255;
BA_DEF_ BO_  "GenMsgDelayTime" INT 0 100000;
BA_DEF_ BO_  "GenMsgILSupport" ENUM  "No","Yes";
BA_DEF_ BO_  "GenMsgTimeoutTime" INT 0 100000;
BA_DEF_ BO_  "GenMsgAutoGenDsp" ENUM  "No","Yes";
BA_DEF_ BO_  "GenMsgAutoGenSnd" ENUM  "No","Yes";
BA_DEF_ BO_  "DiagRequest" ENUM  "No","Yes";
BA_DEF_ BO_  "DiagResponse" ENUM  "No","Yes";
BA_DEF_ BO_  "DiagState" ENUM  "No","Yes";
BA_DEF_ SG_  "GenSigSendType" ENUM  "Cyclic","OnWrite","OnWriteWithRepetition","OnChange","OnChangeWithRepetition","IfActive","IfActiveWithRepetition","NoSigSendType";
BA_DEF_ SG_  "GenSigStartValue" INT 0 4294967295;
BA_DEF_ SG_  "GenSigInactiveValue" INT 0 2147483647;
BA_DEF_ SG_  "GenSigAutoGenDsp" ENUM  "No","Yes";
BA_DEF_ SG_  "GenSigAutoGenSnd" ENUM  "No","Yes";
BA_DEF_ SG_  "GenSigEnvVarType" STRING ;
BA_DEF_ SG_  "GenSigFuncType" ENUM  "NoFunction","MsgCounter","CRC-8","XOR","XOR-2","DatedBit","SW-Kl15","CHK","Constant","Protokoll";
BA_DEF_ SG_  "NWM-WakeUpAllowed" ENUM  "No","Yes";
BA_DEF_ SG_  "INIT" STRING ;
BA_DEF_ SG_  "GenSigTimeoutMsg_Airbag" HEX 0 2047;
BA_DEF_ SG_  "GenSigTimeoutTime_Airbag" INT 0 65535;
BA_DEF_ SG_  "GenSigTimeoutMsg_Allrad" HEX 0 2047;
BA_DEF_ SG_  "GenSigTimeoutTime_Allrad" INT 0 65535;
BA_DEF_ SG_  "GenSigTimeoutMsg_Lenkhilfe_ZF_2" HEX 0 2047;
BA_DEF_ SG_  "GenSigTimeoutTime_Lenkhilfe_ZF_2" INT 0 65535;
BA_DEF_ SG_  "GenSigTimeoutMsg_Teves_MK60_ESP" HEX 0 2047;
BA_DEF_ SG_  "GenSigTimeoutTime_Teves_MK60_ESP" INT 0 65535;
BA_DEF_ SG_  "GenSigTimeoutMsg_LWS" HEX 0 2047;
BA_DEF_ SG_  "GenSigTimeoutTime_LWS" INT 0 65535;
BA_DEF_ SG_  "GenSigTimeoutMsg_LWR" HEX 0 2047;
BA_DEF_ SG_  "GenSigTimeoutTime_LWR" INT 0 65535;
BA_DEF_ SG_  "GenSigTimeoutMsg_Teves_MK70_MAB" HEX 0 2047;
BA_DEF_ SG_  "GenSigTimeoutTime_Teves_MK70_MAB" INT 0 65535;
BA_DEF_ SG_  "GenSigTimeoutMsg_Waehlhebel" HEX 0 2047;
BA_DEF_ SG_  "GenSigTimeoutTime_Waehlhebel" INT 0 65535;
BA_DEF_ SG_  "GenSigTimeoutMsg_EPB" HEX 0 2047;
BA_DEF_ SG_  "GenSigTimeoutTime_EPB" INT 0 65535;
BA_DEF_ SG_  "GenSigTimeoutMsg_TRW_ESP" HEX 0 2047;
BA_DEF_ SG_  "GenSigTimeoutTime_TRW_ESP" INT 0 65535;
BA_DEF_ SG_  "GenSigTimeoutMsg_ACC_Radar" HEX 0 2047;
BA_DEF_ SG_  "GenSigTimeoutTime_ACC_Radar" INT 0 65535;
BA_DEF_ SG_  "GenSigTimeoutMsg_AFS" HEX 0 2047;
BA_DEF_ SG_  "GenSigTimeoutTime_AFS" INT 0 65535;
BA_DEF_ SG_  "GenSigTimeoutMsg_Magne_Ride" HEX 0 2047;
BA_DEF_ SG_  "GenSigTimeoutTime_Magne_Ride" INT 0 65535;
BA_DEF_ SG_  "GenSigTimeoutMsg_RKA_Plus" HEX 0 2047;
BA_DEF_ SG_  "GenSigTimeoutTime_RKA_Plus" INT 0 65535;
BA_DEF_ SG_  "GenSigTimeoutMsg_Selespeed" HEX 0 2047;
BA_DEF_ SG_  "GenSigTimeoutTime_Selespeed" INT 0 65535;
BA_DEF_ SG_  "GenSigTimeoutMsg_Waehlhebel_Sel" HEX 0 2047;
BA_DEF_ SG_  "GenSigTimeoutTime_Waehlhebel_Sel" INT 0 65535;
BA_DEF_ SG_  "GenSigTimeoutMsg_PDC_PLA" HEX 0 2047;
BA_DEF_ SG_  "GenSigTimeoutTime_PDC_PLA" INT 0 65535;
BA_DEF_ SG_  "GenSigTimeoutMsg_Lenkhilfe_APA" HEX 0 2047;
BA_DEF_ SG_  "GenSigTimeoutTime_Lenkhilfe_APA" INT 0 65535;
BA_DEF_ SG_  "GenSigTimeoutMsg_VAQ" HEX 0 2047;
BA_DEF_ SG_  "GenSigTimeoutTime_VAQ" INT 0 65535;
BA_DEF_ SG_  "GenSigTimeoutMsg_Daempfer" HEX 0 2047;
BA_DEF_ SG_  "GenSigTimeoutTime_Daempfer" INT 0 65535;
BA_DEF_ SG_  "GenSigTimeoutMsg_Hybrid_BMS" HEX 0 2047;
BA_DEF_ SG_  "GenSigTimeoutTime_Hybrid_BMS" INT 0 65535;
BA_DEF_ SG_  "GenSigTimeoutMsg_Hybrid_PWR" HEX 0 2047;
BA_DEF_ SG_  "GenSigTimeoutTime_Hybrid_PWR" INT 0 65535;
BA_DEF_ SG_  "GenSigTimeoutMsg_Hybrid_DQ200" HEX 0 2047;
BA_DEF_ SG_  "GenSigTimeoutTime_Hybrid_DQ200" INT 0 65535;
BA_DEF_ SG_  "GenSigTimeoutMsg_EKlimakomp" HEX 0 2047;
BA_DEF_ SG_  "GenSigTimeoutTime_EKlimakomp" INT 0 65535;
BA_DEF_ SG_  "GenSigTimeoutMsg_SWA" HEX 0 2047;
BA_DEF_ SG_  "GenSigTimeoutTime_SWA" INT 0 65535;
BA_DEF_ SG_  "GenSigTimeoutMsg_HCA" HEX 0 2047;
BA_DEF_ SG_  "GenSigTimeoutTime_HCA" INT 0 65535;
BA_DEF_ SG_  "GenSigTimeoutMsg_ACC_Lidar" HEX 0 2047;
BA_DEF_ SG_  "GenSigTimeoutTime_ACC_Lidar" INT 0 65535;
BA_DEF_ SG_  "GenSigTimeoutMsg_Lenkhilfe_ZF_3" HEX 0 2047;
BA_DEF_ SG_  "GenSigTimeoutTime_Lenkhilfe_ZF_3" INT 0 65535;
BA_DEF_ SG_  "GenSigTimeoutMsg_FLA" HEX 0 2047;
BA_DEF_ SG_  "GenSigTimeoutTime_FLA" INT 0 65535;
BA_DEF_ SG_  "GenSigTimeoutMsg_AG6" HEX 0 2047;
BA_DEF_ SG_  "GenSigTimeoutTime_AG6" INT 0 65535;
BA_DEF_ SG_  "GenSigTimeoutMsg_DQ" HEX 0 2047;
BA_DEF_ SG_  "GenSigTimeoutTime_DQ" INT 0 65535;
BA_DEF_ SG_  "GenSigTimeoutMsg_Hybrid_MSG" HEX 0 2047;
BA_DEF_ SG_  "GenSigTimeoutTime_Hybrid_MSG" INT 0 65535;
BA_DEF_ SG_  "GenSigTimeoutMsg_Diesel" HEX 0 2047;
BA_DEF_ SG_  "GenSigTimeoutTime_Diesel" INT 0 65535;
BA_DEF_ SG_  "GenSigTimeoutMsg_Otto" HEX 0 2047;
BA_DEF_ SG_  "GenSigTimeoutTime_Otto" INT 0 65535;
BA_DEF_ SG_  "GenSigTimeoutMsg_Gateway_PQ35_A" HEX 0 2047;
BA_DEF_ SG_  "GenSigTimeoutTime_Gateway_PQ35_A" INT 0 65535;
BA_DEF_ SG_  "GenSigTimeoutMsg_Gateway_PQ46_A" HEX 0 2047;
BA_DEF_ SG_  "GenSigTimeoutTime_Gateway_PQ46_A" INT 0 65535;
BA_DEF_DEF_  "VAGTP20_API" 0;
BA_DEF_DEF_  "VAGTP20_StatConnection" "No";
BA_DEF_DEF_  "VAGTP20_DynConnection" "No";
BA_DEF_DEF_  "VAGTP20_DynSetup" "No";
BA_DEF_DEF_  "NmMessage" "No";
BA_DEF_DEF_  "NmhMessage" "No";
BA_DEF_DEF_  "GenMsgCycleTime" 0;
BA_DEF_DEF_  "GenMsgSendType" "NoMsgSendType";
BA_DEF_DEF_  "GenMsgCycleTimeFast" 0;
BA_DEF_DEF_  "GenMsgNrOfRepetition" 0;
BA_DEF_DEF_  "GenMsgDelayTime" 0;
BA_DEF_DEF_  "GenMsgILSupport" "No";
BA_DEF_DEF_  "GenMsgTimeoutTime" 0;
BA_DEF_DEF_  "GenMsgAutoGenDsp" "Yes";
BA_DEF_DEF_  "GenMsgAutoGenSnd" "Yes";
BA_DEF_DEF_  "DiagRequest" "No";
BA_DEF_DEF_  "DiagResponse" "No";
BA_DEF_DEF_  "DiagState" "No";
BA_DEF_DEF_  "GenSigSendType" "NoSigSendType";
BA_DEF_DEF_  "GenSigStartValue" 0;
BA_DEF_DEF_  "GenSigInactiveValue" 0;
BA_DEF_DEF_  "GenSigAutoGenDsp" "Yes";
BA_DEF_DEF_  "GenSigAutoGenSnd" "Yes";
BA_DEF_DEF_  "GenSigEnvVarType" "Undef";
BA_DEF_DEF_  "GenSigFuncType" "NoFunction";
BA_DEF_DEF_  "NWM-WakeUpAllowed" "No";
BA_DEF_DEF_  "INIT" "";
BA_DEF_DEF_  "GenSigTimeoutMsg_Airbag" 0;
BA_DEF_DEF_  "GenSigTimeoutTime_Airbag" 0;
BA_DEF_DEF_  "GenSigTimeoutMsg_Allrad" 0;
BA_DEF_DEF_  "GenSigTimeoutTime_Allrad" 0;
BA_DEF_DEF_  "GenSigTimeoutMsg_Lenkhilfe_ZF_2" 0;
BA_DEF_DEF_  "GenSigTimeoutTime_Lenkhilfe_ZF_2" 0;
BA_DEF_DEF_  "GenSigTimeoutMsg_Teves_MK60_ESP" 0;
BA_DEF_DEF_  "GenSigTimeoutTime_Teves_MK60_ESP" 0;
BA_DEF_DEF_  "GenSigTimeoutMsg_LWS" 0;
BA_DEF_DEF_  "GenSigTimeoutTime_LWS" 0;
BA_DEF_DEF_  "GenSigTimeoutMsg_LWR" 0;
BA_DEF_DEF_  "GenSigTimeoutTime_LWR" 0;
BA_DEF_DEF_  "GenSigTimeoutMsg_Teves_MK70_MAB" 0;
BA_DEF_DEF_  "GenSigTimeoutTime_Teves_MK70_MAB" 0;
BA_DEF_DEF_  "GenSigTimeoutMsg_Waehlhebel" 0;
BA_DEF_DEF_  "GenSigTimeoutTime_Waehlhebel" 0;
BA_DEF_DEF_  "GenSigTimeoutMsg_EPB" 0;
BA_DEF_DEF_  "GenSigTimeoutTime_EPB" 0;
BA_DEF_DEF_  "GenSigTimeoutMsg_TRW_ESP" 0;
BA_DEF_DEF_  "GenSigTimeoutTime_TRW_ESP" 0;
BA_DEF_DEF_  "GenSigTimeoutMsg_ACC_Radar" 0;
BA_DEF_DEF_  "GenSigTimeoutTime_ACC_Radar" 0;
BA_DEF_DEF_  "GenSigTimeoutMsg_AFS" 0;
BA_DEF_DEF_  "GenSigTimeoutTime_AFS" 0;
BA_DEF_DEF_  "GenSigTimeoutMsg_Magne_Ride" 0;
BA_DEF_DEF_  "GenSigTimeoutTime_Magne_Ride" 0;
BA_DEF_DEF_  "GenSigTimeoutMsg_RKA_Plus" 0;
BA_DEF_DEF_  "GenSigTimeoutTime_RKA_Plus" 0;
BA_DEF_DEF_  "GenSigTimeoutMsg_Selespeed" 0;
BA_DEF_DEF_  "GenSigTimeoutTime_Selespeed" 0;
BA_DEF_DEF_  "GenSigTimeoutMsg_Waehlhebel_Sel" 0;
BA_DEF_DEF_  "GenSigTimeoutTime_Waehlhebel_Sel" 0;
BA_DEF_DEF_  "GenSigTimeoutMsg_PDC_PLA" 0;
BA_DEF_DEF_  "GenSigTimeoutTime_PDC_PLA" 0;
BA_DEF_DEF_  "GenSigTimeoutMsg_Lenkhilfe_APA" 0;
BA_DEF_DEF_  "GenSigTimeoutTime_Lenkhilfe_APA" 0;
BA_DEF_DEF_  "GenSigTimeoutMsg_VAQ" 0;
BA_DEF_DEF_  "GenSigTimeoutTime_VAQ" 0;
BA_DEF_DEF_  "GenSigTimeoutMsg_Daempfer" 0;
BA_DEF_DEF_  "GenSigTimeoutTime_Daempfer" 0;
BA_DEF_DEF_  "GenSigTimeoutMsg_Hybrid_BMS" 0;
BA_DEF_DEF_  "GenSigTimeoutTime_Hybrid_BMS" 0;
BA_DEF_DEF_  "GenSigTimeoutMsg_Hybrid_PWR" 0;
BA_DEF_DEF_  "GenSigTimeoutTime_Hybrid_PWR" 0;
BA_DEF_DEF_  "GenSigTimeoutMsg_Hybrid_DQ200" 0;
BA_DEF_DEF_  "GenSigTimeoutTime_Hybrid_DQ200" 0;
BA_DEF_DEF_  "GenSigTimeoutMsg_EKlimakomp" 0;
BA_DEF_DEF_  "GenSigTimeoutTime_EKlimakomp" 0;
BA_DEF_DEF_  "GenSigTimeoutMsg_SWA" 0;
BA_DEF_DEF_  "GenSigTimeoutTime_SWA" 0;
BA_DEF_DEF_  "GenSigTimeoutMsg_HCA" 0;
BA_DEF_DEF_  "GenSigTimeoutTime_HCA" 0;
BA_DEF_DEF_  "GenSigTimeoutMsg_ACC_Lidar" 0;
BA_DEF_DEF_  "GenSigTimeoutTime_ACC_Lidar" 0;
BA_DEF_DEF_  "GenSigTimeoutMsg_Lenkhilfe_ZF_3" 0;
BA_DEF_DEF_  "GenSigTimeoutTime_Lenkhilfe_ZF_3" 0;
BA_DEF_DEF_  "GenSigTimeoutMsg_FLA" 0;
BA_DEF_DEF_  "GenSigTimeoutTime_FLA" 0;
BA_DEF_DEF_  "GenSigTimeoutMsg_AG6" 0;
BA_DEF_DEF_  "GenSigTimeoutTime_AG6" 0;
BA_DEF_DEF_  "GenSigTimeoutMsg_DQ" 0;
BA_DEF_DEF_  "GenSigTimeoutTime_DQ" 0;
BA_DEF_DEF_  "GenSigTimeoutMsg_Hybrid_MSG" 0;
BA_DEF_DEF_  "GenSigTimeoutTime_Hybrid_MSG" 0;
BA_DEF_DEF_  "GenSigTimeoutMsg_Diesel" 0;
BA_DEF_DEF_  "GenSigTimeoutTime_Diesel" 0;
BA_DEF_DEF_  "GenSigTimeoutMsg_Otto" 0;
BA_DEF_DEF_  "GenSigTimeoutTime_Otto" 0;
BA_DEF_DEF_  "GenSigTimeoutMsg_Gateway_PQ35_A" 0;
BA_DEF_DEF_  "GenSigTimeoutTime_Gateway_PQ35_A" 0;
BA_DEF_DEF_  "GenSigTimeoutMsg_Gateway_PQ46_A" 0;
BA_DEF_DEF_  "GenSigTimeoutTime_Gateway_PQ46_A" 0;
BA_ "GenMsgTimeoutTime" BO_ 1488 1000;
BA_ "GenMsgDelayTime" BO_ 1488 10;
BA_ "GenMsgSendType" BO_ 1488 5;
BA_ "GenMsgCycleTime" BO_ 1488 100;
BA_ "GenMsgTimeoutTime" BO_ 2000 5000;
BA_ "GenMsgSendType" BO_ 2000 0;
BA_ "GenMsgCycleTime" BO_ 2000 1000;
BA_ "GenMsgTimeoutTime" BO_ 1500 1000;
BA_ "GenMsgSendType" BO_ 1500 0;
BA_ "GenMsgCycleTime" BO_ 1500 100;
BA_ "GenMsgTimeoutTime" BO_ 1504 1000;
BA_ "GenMsgSendType" BO_ 1504 0;
BA_ "GenMsgCycleTime" BO_ 1504 100;
BA_ "GenMsgSendType" BO_ 1952 1;
BA_ "VAGTP20_DynConnection" BO_ 1952 1;
BA_ "GenMsgSendType" BO_ 1857 1;
BA_ "VAGTP20_DynConnection" BO_ 1857 1;
BA_ "GenMsgSendType" BO_ 1856 1;
BA_ "VAGTP20_DynConnection" BO_ 1856 1;
BA_ "GenMsgSendType" BO_ 1859 1;
BA_ "VAGTP20_DynConnection" BO_ 1859 1;
BA_ "GenMsgSendType" BO_ 512 1;
BA_ "VAGTP20_DynSetup" BO_ 512 1;
BA_ "GenMsgSendType" BO_ 1858 1;
BA_ "VAGTP20_DynConnection" BO_ 1858 1;
BA_ "GenMsgSendType" BO_ 1893 1;
BA_ "VAGTP20_DynConnection" BO_ 1893 1;
BA_ "GenMsgSendType" BO_ 1906 1;
BA_ "VAGTP20_DynConnection" BO_ 1906 1;
BA_ "GenMsgSendType" BO_ 1875 1;
BA_ "VAGTP20_DynConnection" BO_ 1875 1;
BA_ "GenMsgSendType" BO_ 1874 1;
BA_ "VAGTP20_DynConnection" BO_ 1874 1;
BA_ "GenMsgTimeoutTime" BO_ 914 1000;
BA_ "GenMsgSendType" BO_ 914 0;
BA_ "GenMsgCycleTime" BO_ 914 100;
BA_ "GenMsgSendType" BO_ 1978 1;
BA_ "VAGTP20_DynConnection" BO_ 1978 1;
BA_ "GenMsgSendType" BO_ 1940 1;
BA_ "VAGTP20_DynConnection" BO_ 1940 1;
BA_ "GenMsgSendType" BO_ 1880 1;
BA_ "VAGTP20_DynConnection" BO_ 1880 1;
BA_ "GenMsgSendType" BO_ 1881 1;
BA_ "VAGTP20_DynConnection" BO_ 1881 1;
BA_ "GenMsgTimeoutTime" BO_ 919 1000;
BA_ "GenMsgSendType" BO_ 919 0;
BA_ "GenMsgCycleTime" BO_ 919 100;
BA_ "GenMsgSendType" BO_ 1658 1;
BA_ "GenMsgDelayTime" BO_ 1530 50;
BA_ "GenMsgCycleTimeFast" BO_ 1530 50;
BA_ "GenMsgSendType" BO_ 1530 7;
BA_ "DiagState" BO_ 2015 1;
BA_ "GenMsgSendType" BO_ 2015 1;
BA_ "DiagState" BO_ 1792 1;
BA_ "GenMsgSendType" BO_ 1792 1;
BA_ "DiagRequest" BO_ 2017 1;
BA_ "GenMsgSendType" BO_ 2017 1;
BA_ "DiagRequest" BO_ 2016 1;
BA_ "GenMsgSendType" BO_ 2016 1;
BA_ "GenMsgSendType" BO_ 1976 1;
BA_ "VAGTP20_DynConnection" BO_ 1976 1;
BA_ "GenMsgSendType" BO_ 1977 1;
BA_ "VAGTP20_DynConnection" BO_ 1977 1;
BA_ "GenMsgSendType" BO_ 1654 1;
BA_ "DiagRequest" BO_ 2018 1;
BA_ "GenMsgSendType" BO_ 2018 1;
BA_ "DiagRequest" BO_ 2021 1;
BA_ "GenMsgSendType" BO_ 2021 1;
BA_ "DiagRequest" BO_ 2023 1;
BA_ "GenMsgSendType" BO_ 2023 1;
BA_ "DiagRequest" BO_ 2022 1;
BA_ "GenMsgSendType" BO_ 2022 1;
BA_ "DiagRequest" BO_ 2020 1;
BA_ "GenMsgSendType" BO_ 2020 1;
BA_ "DiagRequest" BO_ 2019 1;
BA_ "GenMsgSendType" BO_ 2019 1;
BA_ "DiagRequest" BO_ 1811 1;
BA_ "GenMsgSendType" BO_ 1811 1;
BA_ "DiagRequest" BO_ 1876 1;
BA_ "GenMsgSendType" BO_ 1876 1;
BA_ "DiagRequest" BO_ 1810 1;
BA_ "GenMsgSendType" BO_ 1810 1;
BA_ "DiagRequest" BO_ 1813 1;
BA_ "GenMsgSendType" BO_ 1813 1;
BA_ "DiagRequest" BO_ 1802 1;
BA_ "GenMsgSendType" BO_ 1802 1;
BA_ "DiagRequest" BO_ 1879 1;
BA_ "GenMsgSendType" BO_ 1879 1;
BA_ "GenMsgTimeoutTime" BO_ 1824 2000;
BA_ "GenMsgSendType" BO_ 1824 0;
BA_ "GenMsgCycleTime" BO_ 1824 200;
BA_ "NmhMessage" BO_ 1824 1;
BA_ "GenMsgSendType" BO_ 1956 1;
BA_ "VAGTP20_DynConnection" BO_ 1956 1;
BA_ "GenMsgSendType" BO_ 1957 1;
BA_ "VAGTP20_DynConnection" BO_ 1957 1;
BA_ "GenMsgSendType" BO_ 2033 1;
BA_ "GenMsgTimeoutTime" BO_ 1527 5000;
BA_ "GenMsgSendType" BO_ 1527 0;
BA_ "GenMsgCycleTime" BO_ 1527 500;
BA_ "GenMsgTimeoutTime" BO_ 1392 1000;
BA_ "GenMsgSendType" BO_ 1392 0;
BA_ "GenMsgCycleTime" BO_ 1392 100;
BA_ "GenMsgTimeoutTime" BO_ 1394 1000;
BA_ "GenMsgDelayTime" BO_ 1394 10;
BA_ "GenMsgSendType" BO_ 1394 5;
BA_ "GenMsgCycleTime" BO_ 1394 100;
BA_ "GenMsgSendType" BO_ 1904 1;
BA_ "VAGTP20_DynConnection" BO_ 1904 1;
BA_ "GenMsgSendType" BO_ 1864 1;
BA_ "VAGTP20_DynConnection" BO_ 1864 1;
BA_ "DiagResponse" BO_ 1982 1;
BA_ "GenMsgSendType" BO_ 1982 1;
BA_ "DiagResponse" BO_ 1917 1;
BA_ "GenMsgSendType" BO_ 1917 1;
BA_ "DiagResponse" BO_ 2027 1;
BA_ "GenMsgSendType" BO_ 2027 1;
BA_ "DiagResponse" BO_ 2028 1;
BA_ "GenMsgSendType" BO_ 2028 1;
BA_ "DiagResponse" BO_ 2030 1;
BA_ "GenMsgSendType" BO_ 2030 1;
BA_ "DiagResponse" BO_ 2031 1;
BA_ "GenMsgSendType" BO_ 2031 1;
BA_ "DiagResponse" BO_ 2029 1;
BA_ "GenMsgSendType" BO_ 2029 1;
BA_ "DiagResponse" BO_ 2026 1;
BA_ "GenMsgSendType" BO_ 2026 1;
BA_ "DiagRequest" BO_ 1817 1;
BA_ "GenMsgSendType" BO_ 1817 1;
BA_ "GenSigSendType" SG_ 1488 SY1_Diag_Ant 0;
BA_ "GenSigSendType" SG_ 1488 SY1_CAN_extern 0;
BA_ "GenSigSendType" SG_ 1488 SY1_Diag_Komf 0;
BA_ "GenSigSendType" SG_ 1488 SY1_Sleep_Info 0;
BA_ "GenSigSendType" SG_ 1488 SY1_Sleep_Komf 0;
BA_ "GenSigSendType" SG_ 1488 SY1_CAN_Info 0;
BA_ "INIT" SG_ 1488 SY1_CAN_Info "const";
BA_ "GenSigSendType" SG_ 1488 SY1_Diag_Info 0;
BA_ "GenSigTimeoutTime_Diesel" SG_ 1488 SY1_Verbauinfo 1000;
BA_ "GenSigTimeoutMsg_Diesel" SG_ 1488 SY1_Verbauinfo 1488;
BA_ "GenSigTimeoutTime_Airbag" SG_ 1488 SY1_Verbauinfo 1000;
BA_ "GenSigTimeoutMsg_Airbag" SG_ 1488 SY1_Verbauinfo 1488;
BA_ "GenSigSendType" SG_ 1488 SY1_Verbauinfo 0;
BA_ "GenSigSendType" SG_ 1488 SY1_Fzg_Marke 0;
BA_ "INIT" SG_ 1488 SY1_Fzg_Marke "const";
BA_ "GenSigSendType" SG_ 1488 SY1_Fzg_Klasse 0;
BA_ "INIT" SG_ 1488 SY1_Fzg_Klasse "const";
BA_ "GenSigSendType" SG_ 1488 SY1_Fzg_Index 0;
BA_ "INIT" SG_ 1488 SY1_Fzg_Index "const";
BA_ "GenSigSendType" SG_ 1488 SY1_Fzg_Gen 0;
BA_ "INIT" SG_ 1488 SY1_Fzg_Gen "const";
BA_ "GenSigSendType" SG_ 1488 SY1_Tueren 0;
BA_ "INIT" SG_ 1488 SY1_Tueren "const";
BA_ "GenSigSendType" SG_ 1488 SY1_Fzg_Derivat 0;
BA_ "INIT" SG_ 1488 SY1_Fzg_Derivat "const";
BA_ "GenSigTimeoutTime_TRW_ESP" SG_ 1488 SY1_Lenker 1000;
BA_ "GenSigTimeoutMsg_TRW_ESP" SG_ 1488 SY1_Lenker 1488;
BA_ "GenSigSendType" SG_ 1488 SY1_Lenker 0;
BA_ "INIT" SG_ 1488 SY1_Lenker "const";
BA_ "GenSigSendType" SG_ 1488 SY1_Fehlereintr 0;
BA_ "GenSigSendType" SG_ 1488 SY1_Komf_HV 0;
BA_ "INIT" SG_ 1488 SY1_Komf_HV "const";
BA_ "GenSigTimeoutTime_Daempfer" SG_ 1488 SY1_Transportmode 1000;
BA_ "GenSigTimeoutMsg_Daempfer" SG_ 1488 SY1_Transportmode 1488;
BA_ "GenSigSendType" SG_ 1488 SY1_Transportmode 0;
BA_ "GenSigSendType" SG_ 1488 SY1_Ant_NV 0;
BA_ "INIT" SG_ 1488 SY1_Ant_NV "const";
BA_ "GenSigSendType" SG_ 1488 SY1_Komf_NV 0;
BA_ "INIT" SG_ 1488 SY1_Komf_NV "const";
BA_ "GenSigSendType" SG_ 1488 SY1_Ant_HV 0;
BA_ "INIT" SG_ 1488 SY1_Ant_HV "const";
BA_ "GenSigSendType" SG_ 1488 SY1_Notbrems_Status 3;
BA_ "GenSigSendType" SG_ 1488 SY1_ELV_Lock_Supply 3;
BA_ "GenSigTimeoutTime_HCA" SG_ 1488 SY1_Relais_FAS_Zweig 1000;
BA_ "GenSigTimeoutMsg_HCA" SG_ 1488 SY1_Relais_FAS_Zweig 1488;
BA_ "GenSigTimeoutTime_TRW_ESP" SG_ 1488 SY1_Relais_FAS_Zweig 1000;
BA_ "GenSigTimeoutMsg_TRW_ESP" SG_ 1488 SY1_Relais_FAS_Zweig 1488;
BA_ "GenSigSendType" SG_ 1488 SY1_Relais_FAS_Zweig 3;
BA_ "INIT" SG_ 1488 SY1_Relais_FAS_Zweig "0/1";
BA_ "GenSigTimeoutTime_Otto" SG_ 1488 SY1_QRS_Messmodus 1000;
BA_ "GenSigTimeoutMsg_Otto" SG_ 1488 SY1_QRS_Messmodus 1488;
BA_ "GenSigSendType" SG_ 1488 SY1_QRS_Messmodus 3;
BA_ "GenSigSendType" SG_ 1488 SY1_res52 3;
BA_ "GenSigSendType" SG_ 1488 SY1_NWDF_gueltig 3;
BA_ "GenSigSendType" SG_ 1488 SY1_res53 3;
BA_ "GenSigSendType" SG_ 1488 SY1_res59 3;
BA_ "GenSigSendType" SG_ 1488 SY1_NWDF 3;
BA_ "GenSigSendType" SG_ 1488 SY1_res60 3;
BA_ "GenSigSendType" SG_ 1488 SY1_res62 3;
BA_ "GenSigSendType" SG_ 1488 SY1_res58 3;
BA_ "GenSigSendType" SG_ 1488 SY1_res57 3;
BA_ "GenSigSendType" SG_ 1488 SY1_res61 3;
BA_ "GenSigSendType" SG_ 1488 SY1_res63 3;
BA_ "GenSigTimeoutTime_Lenkhilfe_ZF_3" SG_ 2000 DI1_Jahr 5000;
BA_ "GenSigTimeoutMsg_Lenkhilfe_ZF_3" SG_ 2000 DI1_Jahr 2000;
BA_ "GenSigTimeoutTime_Lenkhilfe_ZF_2" SG_ 2000 DI1_Jahr 5000;
BA_ "GenSigTimeoutMsg_Lenkhilfe_ZF_2" SG_ 2000 DI1_Jahr 2000;
BA_ "GenSigTimeoutTime_FLA" SG_ 2000 DI1_Jahr 5000;
BA_ "GenSigTimeoutMsg_FLA" SG_ 2000 DI1_Jahr 2000;
BA_ "GenSigTimeoutTime_ACC_Lidar" SG_ 2000 DI1_Jahr 5000;
BA_ "GenSigTimeoutMsg_ACC_Lidar" SG_ 2000 DI1_Jahr 2000;
BA_ "GenSigTimeoutTime_Allrad" SG_ 2000 DI1_Jahr 5000;
BA_ "GenSigTimeoutMsg_Allrad" SG_ 2000 DI1_Jahr 2000;
BA_ "GenSigTimeoutTime_SWA" SG_ 2000 DI1_Jahr 5000;
BA_ "GenSigTimeoutMsg_SWA" SG_ 2000 DI1_Jahr 2000;
BA_ "GenSigTimeoutTime_HCA" SG_ 2000 DI1_Jahr 5000;
BA_ "GenSigTimeoutMsg_HCA" SG_ 2000 DI1_Jahr 2000;
BA_ "GenSigTimeoutTime_Hybrid_PWR" SG_ 2000 DI1_Jahr 5000;
BA_ "GenSigTimeoutMsg_Hybrid_PWR" SG_ 2000 DI1_Jahr 2000;
BA_ "GenSigTimeoutTime_Hybrid_BMS" SG_ 2000 DI1_Jahr 5000;
BA_ "GenSigTimeoutMsg_Hybrid_BMS" SG_ 2000 DI1_Jahr 2000;
BA_ "GenSigTimeoutTime_Hybrid_MSG" SG_ 2000 DI1_Jahr 5000;
BA_ "GenSigTimeoutMsg_Hybrid_MSG" SG_ 2000 DI1_Jahr 2000;
BA_ "GenSigTimeoutTime_Daempfer" SG_ 2000 DI1_Jahr 5000;
BA_ "GenSigTimeoutMsg_Daempfer" SG_ 2000 DI1_Jahr 2000;
BA_ "GenSigTimeoutTime_VAQ" SG_ 2000 DI1_Jahr 5000;
BA_ "GenSigTimeoutMsg_VAQ" SG_ 2000 DI1_Jahr 2000;
BA_ "GenSigTimeoutTime_Lenkhilfe_APA" SG_ 2000 DI1_Jahr 5000;
BA_ "GenSigTimeoutMsg_Lenkhilfe_APA" SG_ 2000 DI1_Jahr 2000;
BA_ "GenSigTimeoutTime_PDC_PLA" SG_ 2000 DI1_Jahr 5000;
BA_ "GenSigTimeoutMsg_PDC_PLA" SG_ 2000 DI1_Jahr 2000;
BA_ "GenSigTimeoutTime_RKA_Plus" SG_ 2000 DI1_Jahr 5000;
BA_ "GenSigTimeoutMsg_RKA_Plus" SG_ 2000 DI1_Jahr 2000;
BA_ "GenSigTimeoutTime_Magne_Ride" SG_ 2000 DI1_Jahr 5000;
BA_ "GenSigTimeoutMsg_Magne_Ride" SG_ 2000 DI1_Jahr 2000;
BA_ "GenSigTimeoutTime_AFS" SG_ 2000 DI1_Jahr 5000;
BA_ "GenSigTimeoutMsg_AFS" SG_ 2000 DI1_Jahr 2000;
BA_ "GenSigTimeoutTime_ACC_Radar" SG_ 2000 DI1_Jahr 5000;
BA_ "GenSigTimeoutMsg_ACC_Radar" SG_ 2000 DI1_Jahr 2000;
BA_ "GenSigTimeoutTime_TRW_ESP" SG_ 2000 DI1_Jahr 5000;
BA_ "GenSigTimeoutMsg_TRW_ESP" SG_ 2000 DI1_Jahr 2000;
BA_ "GenSigTimeoutTime_EPB" SG_ 2000 DI1_Jahr 5000;
BA_ "GenSigTimeoutMsg_EPB" SG_ 2000 DI1_Jahr 2000;
BA_ "GenSigTimeoutTime_Teves_MK70_MAB" SG_ 2000 DI1_Jahr 5000;
BA_ "GenSigTimeoutMsg_Teves_MK70_MAB" SG_ 2000 DI1_Jahr 2000;
BA_ "GenSigTimeoutTime_LWR" SG_ 2000 DI1_Jahr 5000;
BA_ "GenSigTimeoutMsg_LWR" SG_ 2000 DI1_Jahr 2000;
BA_ "GenSigTimeoutTime_Teves_MK60_ESP" SG_ 2000 DI1_Jahr 5000;
BA_ "GenSigTimeoutMsg_Teves_MK60_ESP" SG_ 2000 DI1_Jahr 2000;
BA_ "GenSigTimeoutTime_Otto" SG_ 2000 DI1_Jahr 5000;
BA_ "GenSigTimeoutMsg_Otto" SG_ 2000 DI1_Jahr 2000;
BA_ "GenSigTimeoutTime_Diesel" SG_ 2000 DI1_Jahr 5000;
BA_ "GenSigTimeoutMsg_Diesel" SG_ 2000 DI1_Jahr 2000;
BA_ "GenSigTimeoutTime_Airbag" SG_ 2000 DI1_Jahr 5000;
BA_ "GenSigTimeoutMsg_Airbag" SG_ 2000 DI1_Jahr 2000;
BA_ "GenSigSendType" SG_ 2000 DI1_Jahr 0;
BA_ "GenSigTimeoutTime_Lenkhilfe_ZF_3" SG_ 2000 DI1_Minute 5000;
BA_ "GenSigTimeoutMsg_Lenkhilfe_ZF_3" SG_ 2000 DI1_Minute 2000;
BA_ "GenSigTimeoutTime_Lenkhilfe_ZF_2" SG_ 2000 DI1_Minute 5000;
BA_ "GenSigTimeoutMsg_Lenkhilfe_ZF_2" SG_ 2000 DI1_Minute 2000;
BA_ "GenSigTimeoutTime_Teves_MK60_ESP" SG_ 2000 DI1_Minute 5000;
BA_ "GenSigTimeoutMsg_Teves_MK60_ESP" SG_ 2000 DI1_Minute 2000;
BA_ "GenSigTimeoutTime_FLA" SG_ 2000 DI1_Minute 5000;
BA_ "GenSigTimeoutMsg_FLA" SG_ 2000 DI1_Minute 2000;
BA_ "GenSigTimeoutTime_ACC_Lidar" SG_ 2000 DI1_Minute 5000;
BA_ "GenSigTimeoutMsg_ACC_Lidar" SG_ 2000 DI1_Minute 2000;
BA_ "GenSigTimeoutTime_Allrad" SG_ 2000 DI1_Minute 5000;
BA_ "GenSigTimeoutMsg_Allrad" SG_ 2000 DI1_Minute 2000;
BA_ "GenSigTimeoutTime_SWA" SG_ 2000 DI1_Minute 5000;
BA_ "GenSigTimeoutMsg_SWA" SG_ 2000 DI1_Minute 2000;
BA_ "GenSigTimeoutTime_HCA" SG_ 2000 DI1_Minute 5000;
BA_ "GenSigTimeoutMsg_HCA" SG_ 2000 DI1_Minute 2000;
BA_ "GenSigTimeoutTime_Hybrid_PWR" SG_ 2000 DI1_Minute 5000;
BA_ "GenSigTimeoutMsg_Hybrid_PWR" SG_ 2000 DI1_Minute 2000;
BA_ "GenSigTimeoutTime_Hybrid_BMS" SG_ 2000 DI1_Minute 5000;
BA_ "GenSigTimeoutMsg_Hybrid_BMS" SG_ 2000 DI1_Minute 2000;
BA_ "GenSigTimeoutTime_Hybrid_MSG" SG_ 2000 DI1_Minute 5000;
BA_ "GenSigTimeoutMsg_Hybrid_MSG" SG_ 2000 DI1_Minute 2000;
BA_ "GenSigTimeoutTime_Daempfer" SG_ 2000 DI1_Minute 5000;
BA_ "GenSigTimeoutMsg_Daempfer" SG_ 2000 DI1_Minute 2000;
BA_ "GenSigTimeoutTime_VAQ" SG_ 2000 DI1_Minute 5000;
BA_ "GenSigTimeoutMsg_VAQ" SG_ 2000 DI1_Minute 2000;
BA_ "GenSigTimeoutTime_Lenkhilfe_APA" SG_ 2000 DI1_Minute 5000;
BA_ "GenSigTimeoutMsg_Lenkhilfe_APA" SG_ 2000 DI1_Minute 2000;
BA_ "GenSigTimeoutTime_PDC_PLA" SG_ 2000 DI1_Minute 5000;
BA_ "GenSigTimeoutMsg_PDC_PLA" SG_ 2000 DI1_Minute 2000;
BA_ "GenSigTimeoutTime_RKA_Plus" SG_ 2000 DI1_Minute 5000;
BA_ "GenSigTimeoutMsg_RKA_Plus" SG_ 2000 DI1_Minute 2000;
BA_ "GenSigTimeoutTime_Magne_Ride" SG_ 2000 DI1_Minute 5000;
BA_ "GenSigTimeoutMsg_Magne_Ride" SG_ 2000 DI1_Minute 2000;
BA_ "GenSigTimeoutTime_AFS" SG_ 2000 DI1_Minute 5000;
BA_ "GenSigTimeoutMsg_AFS" SG_ 2000 DI1_Minute 2000;
BA_ "GenSigTimeoutTime_ACC_Radar" SG_ 2000 DI1_Minute 5000;
BA_ "GenSigTimeoutMsg_ACC_Radar" SG_ 2000 DI1_Minute 2000;
BA_ "GenSigTimeoutTime_TRW_ESP" SG_ 2000 DI1_Minute 5000;
BA_ "GenSigTimeoutMsg_TRW_ESP" SG_ 2000 DI1_Minute 2000;
BA_ "GenSigTimeoutTime_EPB" SG_ 2000 DI1_Minute 5000;
BA_ "GenSigTimeoutMsg_EPB" SG_ 2000 DI1_Minute 2000;
BA_ "GenSigTimeoutTime_LWR" SG_ 2000 DI1_Minute 5000;
BA_ "GenSigTimeoutMsg_LWR" SG_ 2000 DI1_Minute 2000;
BA_ "GenSigTimeoutTime_Otto" SG_ 2000 DI1_Minute 5000;
BA_ "GenSigTimeoutMsg_Otto" SG_ 2000 DI1_Minute 2000;
BA_ "GenSigTimeoutTime_Diesel" SG_ 2000 DI1_Minute 5000;
BA_ "GenSigTimeoutMsg_Diesel" SG_ 2000 DI1_Minute 2000;
BA_ "GenSigTimeoutTime_Airbag" SG_ 2000 DI1_Minute 5000;
BA_ "GenSigTimeoutMsg_Airbag" SG_ 2000 DI1_Minute 2000;
BA_ "GenSigSendType" SG_ 2000 DI1_Minute 0;
BA_ "GenSigTimeoutTime_Lenkhilfe_ZF_2" SG_ 2000 DI1_Monat 5000;
BA_ "GenSigTimeoutMsg_Lenkhilfe_ZF_2" SG_ 2000 DI1_Monat 2000;
BA_ "GenSigTimeoutTime_Lenkhilfe_ZF_3" SG_ 2000 DI1_Monat 5000;
BA_ "GenSigTimeoutMsg_Lenkhilfe_ZF_3" SG_ 2000 DI1_Monat 2000;
BA_ "GenSigTimeoutTime_FLA" SG_ 2000 DI1_Monat 5000;
BA_ "GenSigTimeoutMsg_FLA" SG_ 2000 DI1_Monat 2000;
BA_ "GenSigTimeoutTime_ACC_Lidar" SG_ 2000 DI1_Monat 5000;
BA_ "GenSigTimeoutMsg_ACC_Lidar" SG_ 2000 DI1_Monat 2000;
BA_ "GenSigTimeoutTime_Allrad" SG_ 2000 DI1_Monat 5000;
BA_ "GenSigTimeoutMsg_Allrad" SG_ 2000 DI1_Monat 2000;
BA_ "GenSigTimeoutTime_SWA" SG_ 2000 DI1_Monat 5000;
BA_ "GenSigTimeoutMsg_SWA" SG_ 2000 DI1_Monat 2000;
BA_ "GenSigTimeoutTime_HCA" SG_ 2000 DI1_Monat 5000;
BA_ "GenSigTimeoutMsg_HCA" SG_ 2000 DI1_Monat 2000;
BA_ "GenSigTimeoutTime_Hybrid_PWR" SG_ 2000 DI1_Monat 5000;
BA_ "GenSigTimeoutMsg_Hybrid_PWR" SG_ 2000 DI1_Monat 2000;
BA_ "GenSigTimeoutTime_Hybrid_BMS" SG_ 2000 DI1_Monat 5000;
BA_ "GenSigTimeoutMsg_Hybrid_BMS" SG_ 2000 DI1_Monat 2000;
BA_ "GenSigTimeoutTime_Hybrid_MSG" SG_ 2000 DI1_Monat 5000;
BA_ "GenSigTimeoutMsg_Hybrid_MSG" SG_ 2000 DI1_Monat 2000;
BA_ "GenSigTimeoutTime_Daempfer" SG_ 2000 DI1_Monat 5000;
BA_ "GenSigTimeoutMsg_Daempfer" SG_ 2000 DI1_Monat 2000;
BA_ "GenSigTimeoutTime_VAQ" SG_ 2000 DI1_Monat 5000;
BA_ "GenSigTimeoutMsg_VAQ" SG_ 2000 DI1_Monat 2000;
BA_ "GenSigTimeoutTime_Lenkhilfe_APA" SG_ 2000 DI1_Monat 5000;
BA_ "GenSigTimeoutMsg_Lenkhilfe_APA" SG_ 2000 DI1_Monat 2000;
BA_ "GenSigTimeoutTime_PDC_PLA" SG_ 2000 DI1_Monat 5000;
BA_ "GenSigTimeoutMsg_PDC_PLA" SG_ 2000 DI1_Monat 2000;
BA_ "GenSigTimeoutTime_RKA_Plus" SG_ 2000 DI1_Monat 5000;
BA_ "GenSigTimeoutMsg_RKA_Plus" SG_ 2000 DI1_Monat 2000;
BA_ "GenSigTimeoutTime_Magne_Ride" SG_ 2000 DI1_Monat 5000;
BA_ "GenSigTimeoutMsg_Magne_Ride" SG_ 2000 DI1_Monat 2000;
BA_ "GenSigTimeoutTime_AFS" SG_ 2000 DI1_Monat 5000;
BA_ "GenSigTimeoutMsg_AFS" SG_ 2000 DI1_Monat 2000;
BA_ "GenSigTimeoutTime_ACC_Radar" SG_ 2000 DI1_Monat 5000;
BA_ "GenSigTimeoutMsg_ACC_Radar" SG_ 2000 DI1_Monat 2000;
BA_ "GenSigTimeoutTime_TRW_ESP" SG_ 2000 DI1_Monat 5000;
BA_ "GenSigTimeoutMsg_TRW_ESP" SG_ 2000 DI1_Monat 2000;
BA_ "GenSigTimeoutTime_EPB" SG_ 2000 DI1_Monat 5000;
BA_ "GenSigTimeoutMsg_EPB" SG_ 2000 DI1_Monat 2000;
BA_ "GenSigTimeoutTime_Teves_MK70_MAB" SG_ 2000 DI1_Monat 5000;
BA_ "GenSigTimeoutMsg_Teves_MK70_MAB" SG_ 2000 DI1_Monat 2000;
BA_ "GenSigTimeoutTime_LWR" SG_ 2000 DI1_Monat 5000;
BA_ "GenSigTimeoutMsg_LWR" SG_ 2000 DI1_Monat 2000;
BA_ "GenSigTimeoutTime_Teves_MK60_ESP" SG_ 2000 DI1_Monat 5000;
BA_ "GenSigTimeoutMsg_Teves_MK60_ESP" SG_ 2000 DI1_Monat 2000;
BA_ "GenSigTimeoutTime_Otto" SG_ 2000 DI1_Monat 5000;
BA_ "GenSigTimeoutMsg_Otto" SG_ 2000 DI1_Monat 2000;
BA_ "GenSigTimeoutTime_Diesel" SG_ 2000 DI1_Monat 5000;
BA_ "GenSigTimeoutMsg_Diesel" SG_ 2000 DI1_Monat 2000;
BA_ "GenSigTimeoutTime_Airbag" SG_ 2000 DI1_Monat 5000;
BA_ "GenSigTimeoutMsg_Airbag" SG_ 2000 DI1_Monat 2000;
BA_ "GenSigSendType" SG_ 2000 DI1_Monat 0;
BA_ "GenSigSendType" SG_ 2000 DI1_Reserve1 0;
BA_ "GenSigTimeoutTime_FLA" SG_ 2000 DI1_km_Stand 5000;
BA_ "GenSigTimeoutMsg_FLA" SG_ 2000 DI1_km_Stand 2000;
BA_ "GenSigTimeoutTime_ACC_Lidar" SG_ 2000 DI1_km_Stand 5000;
BA_ "GenSigTimeoutMsg_ACC_Lidar" SG_ 2000 DI1_km_Stand 2000;
BA_ "GenSigTimeoutTime_Allrad" SG_ 2000 DI1_km_Stand 5000;
BA_ "GenSigTimeoutMsg_Allrad" SG_ 2000 DI1_km_Stand 2000;
BA_ "GenSigTimeoutTime_SWA" SG_ 2000 DI1_km_Stand 5000;
BA_ "GenSigTimeoutMsg_SWA" SG_ 2000 DI1_km_Stand 2000;
BA_ "GenSigTimeoutTime_HCA" SG_ 2000 DI1_km_Stand 5000;
BA_ "GenSigTimeoutMsg_HCA" SG_ 2000 DI1_km_Stand 2000;
BA_ "GenSigTimeoutTime_Hybrid_PWR" SG_ 2000 DI1_km_Stand 5000;
BA_ "GenSigTimeoutMsg_Hybrid_PWR" SG_ 2000 DI1_km_Stand 2000;
BA_ "GenSigTimeoutTime_Hybrid_BMS" SG_ 2000 DI1_km_Stand 5000;
BA_ "GenSigTimeoutMsg_Hybrid_BMS" SG_ 2000 DI1_km_Stand 2000;
BA_ "GenSigTimeoutTime_Hybrid_MSG" SG_ 2000 DI1_km_Stand 5000;
BA_ "GenSigTimeoutMsg_Hybrid_MSG" SG_ 2000 DI1_km_Stand 2000;
BA_ "GenSigTimeoutTime_Daempfer" SG_ 2000 DI1_km_Stand 5000;
BA_ "GenSigTimeoutMsg_Daempfer" SG_ 2000 DI1_km_Stand 2000;
BA_ "GenSigTimeoutTime_VAQ" SG_ 2000 DI1_km_Stand 5000;
BA_ "GenSigTimeoutMsg_VAQ" SG_ 2000 DI1_km_Stand 2000;
BA_ "GenSigTimeoutTime_Lenkhilfe_APA" SG_ 2000 DI1_km_Stand 5000;
BA_ "GenSigTimeoutMsg_Lenkhilfe_APA" SG_ 2000 DI1_km_Stand 2000;
BA_ "GenSigTimeoutTime_PDC_PLA" SG_ 2000 DI1_km_Stand 5000;
BA_ "GenSigTimeoutMsg_PDC_PLA" SG_ 2000 DI1_km_Stand 2000;
BA_ "GenSigTimeoutTime_RKA_Plus" SG_ 2000 DI1_km_Stand 5000;
BA_ "GenSigTimeoutMsg_RKA_Plus" SG_ 2000 DI1_km_Stand 2000;
BA_ "GenSigTimeoutTime_Magne_Ride" SG_ 2000 DI1_km_Stand 5000;
BA_ "GenSigTimeoutMsg_Magne_Ride" SG_ 2000 DI1_km_Stand 2000;
BA_ "GenSigTimeoutTime_AFS" SG_ 2000 DI1_km_Stand 5000;
BA_ "GenSigTimeoutMsg_AFS" SG_ 2000 DI1_km_Stand 2000;
BA_ "GenSigTimeoutTime_ACC_Radar" SG_ 2000 DI1_km_Stand 5000;
BA_ "GenSigTimeoutMsg_ACC_Radar" SG_ 2000 DI1_km_Stand 2000;
BA_ "GenSigTimeoutTime_TRW_ESP" SG_ 2000 DI1_km_Stand 5000;
BA_ "GenSigTimeoutMsg_TRW_ESP" SG_ 2000 DI1_km_Stand 2000;
BA_ "GenSigTimeoutTime_EPB" SG_ 2000 DI1_km_Stand 5000;
BA_ "GenSigTimeoutMsg_EPB" SG_ 2000 DI1_km_Stand 2000;
BA_ "GenSigTimeoutTime_LWR" SG_ 2000 DI1_km_Stand 5000;
BA_ "GenSigTimeoutMsg_LWR" SG_ 2000 DI1_km_Stand 2000;
BA_ "GenSigTimeoutTime_Otto" SG_ 2000 DI1_km_Stand 5000;
BA_ "GenSigTimeoutMsg_Otto" SG_ 2000 DI1_km_Stand 2000;
BA_ "GenSigTimeoutTime_Diesel" SG_ 2000 DI1_km_Stand 5000;
BA_ "GenSigTimeoutMsg_Diesel" SG_ 2000 DI1_km_Stand 2000;
BA_ "GenSigTimeoutTime_Airbag" SG_ 2000 DI1_km_Stand 5000;
BA_ "GenSigTimeoutMsg_Airbag" SG_ 2000 DI1_km_Stand 2000;
BA_ "GenSigSendType" SG_ 2000 DI1_km_Stand 0;
BA_ "GenSigTimeoutTime_Lenkhilfe_ZF_3" SG_ 2000 DI1_Sekunde 5000;
BA_ "GenSigTimeoutMsg_Lenkhilfe_ZF_3" SG_ 2000 DI1_Sekunde 2000;
BA_ "GenSigTimeoutTime_Lenkhilfe_ZF_2" SG_ 2000 DI1_Sekunde 5000;
BA_ "GenSigTimeoutMsg_Lenkhilfe_ZF_2" SG_ 2000 DI1_Sekunde 2000;
BA_ "GenSigTimeoutTime_Teves_MK60_ESP" SG_ 2000 DI1_Sekunde 5000;
BA_ "GenSigTimeoutMsg_Teves_MK60_ESP" SG_ 2000 DI1_Sekunde 2000;
BA_ "GenSigTimeoutTime_FLA" SG_ 2000 DI1_Sekunde 5000;
BA_ "GenSigTimeoutMsg_FLA" SG_ 2000 DI1_Sekunde 2000;
BA_ "GenSigTimeoutTime_ACC_Lidar" SG_ 2000 DI1_Sekunde 5000;
BA_ "GenSigTimeoutMsg_ACC_Lidar" SG_ 2000 DI1_Sekunde 2000;
BA_ "GenSigTimeoutTime_Allrad" SG_ 2000 DI1_Sekunde 5000;
BA_ "GenSigTimeoutMsg_Allrad" SG_ 2000 DI1_Sekunde 2000;
BA_ "GenSigTimeoutTime_SWA" SG_ 2000 DI1_Sekunde 5000;
BA_ "GenSigTimeoutMsg_SWA" SG_ 2000 DI1_Sekunde 2000;
BA_ "GenSigTimeoutTime_HCA" SG_ 2000 DI1_Sekunde 5000;
BA_ "GenSigTimeoutMsg_HCA" SG_ 2000 DI1_Sekunde 2000;
BA_ "GenSigTimeoutTime_Hybrid_PWR" SG_ 2000 DI1_Sekunde 5000;
BA_ "GenSigTimeoutMsg_Hybrid_PWR" SG_ 2000 DI1_Sekunde 2000;
BA_ "GenSigTimeoutTime_Hybrid_BMS" SG_ 2000 DI1_Sekunde 5000;
BA_ "GenSigTimeoutMsg_Hybrid_BMS" SG_ 2000 DI1_Sekunde 2000;
BA_ "GenSigTimeoutTime_Hybrid_MSG" SG_ 2000 DI1_Sekunde 5000;
BA_ "GenSigTimeoutMsg_Hybrid_MSG" SG_ 2000 DI1_Sekunde 2000;
BA_ "GenSigTimeoutTime_VAQ" SG_ 2000 DI1_Sekunde 5000;
BA_ "GenSigTimeoutMsg_VAQ" SG_ 2000 DI1_Sekunde 2000;
BA_ "GenSigTimeoutTime_Daempfer" SG_ 2000 DI1_Sekunde 5000;
BA_ "GenSigTimeoutMsg_Daempfer" SG_ 2000 DI1_Sekunde 2000;
BA_ "GenSigTimeoutTime_Lenkhilfe_APA" SG_ 2000 DI1_Sekunde 5000;
BA_ "GenSigTimeoutMsg_Lenkhilfe_APA" SG_ 2000 DI1_Sekunde 2000;
BA_ "GenSigTimeoutTime_PDC_PLA" SG_ 2000 DI1_Sekunde 5000;
BA_ "GenSigTimeoutMsg_PDC_PLA" SG_ 2000 DI1_Sekunde 2000;
BA_ "GenSigTimeoutTime_RKA_Plus" SG_ 2000 DI1_Sekunde 5000;
BA_ "GenSigTimeoutMsg_RKA_Plus" SG_ 2000 DI1_Sekunde 2000;
BA_ "GenSigTimeoutTime_Magne_Ride" SG_ 2000 DI1_Sekunde 5000;
BA_ "GenSigTimeoutMsg_Magne_Ride" SG_ 2000 DI1_Sekunde 2000;
BA_ "GenSigTimeoutTime_AFS" SG_ 2000 DI1_Sekunde 5000;
BA_ "GenSigTimeoutMsg_AFS" SG_ 2000 DI1_Sekunde 2000;
BA_ "GenSigTimeoutTime_ACC_Radar" SG_ 2000 DI1_Sekunde 5000;
BA_ "GenSigTimeoutMsg_ACC_Radar" SG_ 2000 DI1_Sekunde 2000;
BA_ "GenSigTimeoutTime_TRW_ESP" SG_ 2000 DI1_Sekunde 5000;
BA_ "GenSigTimeoutMsg_TRW_ESP" SG_ 2000 DI1_Sekunde 2000;
BA_ "GenSigTimeoutTime_EPB" SG_ 2000 DI1_Sekunde 5000;
BA_ "GenSigTimeoutMsg_EPB" SG_ 2000 DI1_Sekunde 2000;
BA_ "GenSigTimeoutTime_LWR" SG_ 2000 DI1_Sekunde 5000;
BA_ "GenSigTimeoutMsg_LWR" SG_ 2000 DI1_Sekunde 2000;
BA_ "GenSigTimeoutTime_Otto" SG_ 2000 DI1_Sekunde 5000;
BA_ "GenSigTimeoutMsg_Otto" SG_ 2000 DI1_Sekunde 2000;
BA_ "GenSigTimeoutTime_Diesel" SG_ 2000 DI1_Sekunde 5000;
BA_ "GenSigTimeoutMsg_Diesel" SG_ 2000 DI1_Sekunde 2000;
BA_ "GenSigTimeoutTime_Airbag" SG_ 2000 DI1_Sekunde 5000;
BA_ "GenSigTimeoutMsg_Airbag" SG_ 2000 DI1_Sekunde 2000;
BA_ "GenSigSendType" SG_ 2000 DI1_Sekunde 0;
BA_ "GenSigTimeoutTime_Lenkhilfe_ZF_3" SG_ 2000 DI1_Stunde 5000;
BA_ "GenSigTimeoutMsg_Lenkhilfe_ZF_3" SG_ 2000 DI1_Stunde 2000;
BA_ "GenSigTimeoutTime_Lenkhilfe_ZF_2" SG_ 2000 DI1_Stunde 5000;
BA_ "GenSigTimeoutMsg_Lenkhilfe_ZF_2" SG_ 2000 DI1_Stunde 2000;
BA_ "GenSigTimeoutTime_Teves_MK60_ESP" SG_ 2000 DI1_Stunde 5000;
BA_ "GenSigTimeoutMsg_Teves_MK60_ESP" SG_ 2000 DI1_Stunde 2000;
BA_ "GenSigTimeoutTime_FLA" SG_ 2000 DI1_Stunde 5000;
BA_ "GenSigTimeoutMsg_FLA" SG_ 2000 DI1_Stunde 2000;
BA_ "GenSigTimeoutTime_ACC_Lidar" SG_ 2000 DI1_Stunde 5000;
BA_ "GenSigTimeoutMsg_ACC_Lidar" SG_ 2000 DI1_Stunde 2000;
BA_ "GenSigTimeoutTime_Allrad" SG_ 2000 DI1_Stunde 5000;
BA_ "GenSigTimeoutMsg_Allrad" SG_ 2000 DI1_Stunde 2000;
BA_ "GenSigTimeoutTime_SWA" SG_ 2000 DI1_Stunde 5000;
BA_ "GenSigTimeoutMsg_SWA" SG_ 2000 DI1_Stunde 2000;
BA_ "GenSigTimeoutTime_HCA" SG_ 2000 DI1_Stunde 5000;
BA_ "GenSigTimeoutMsg_HCA" SG_ 2000 DI1_Stunde 2000;
BA_ "GenSigTimeoutTime_Hybrid_PWR" SG_ 2000 DI1_Stunde 5000;
BA_ "GenSigTimeoutMsg_Hybrid_PWR" SG_ 2000 DI1_Stunde 2000;
BA_ "GenSigTimeoutTime_Hybrid_BMS" SG_ 2000 DI1_Stunde 5000;
BA_ "GenSigTimeoutMsg_Hybrid_BMS" SG_ 2000 DI1_Stunde 2000;
BA_ "GenSigTimeoutTime_Hybrid_MSG" SG_ 2000 DI1_Stunde 5000;
BA_ "GenSigTimeoutMsg_Hybrid_MSG" SG_ 2000 DI1_Stunde 2000;
BA_ "GenSigTimeoutTime_Daempfer" SG_ 2000 DI1_Stunde 5000;
BA_ "GenSigTimeoutMsg_Daempfer" SG_ 2000 DI1_Stunde 2000;
BA_ "GenSigTimeoutTime_VAQ" SG_ 2000 DI1_Stunde 5000;
BA_ "GenSigTimeoutMsg_VAQ" SG_ 2000 DI1_Stunde 2000;
BA_ "GenSigTimeoutTime_Lenkhilfe_APA" SG_ 2000 DI1_Stunde 5000;
BA_ "GenSigTimeoutMsg_Lenkhilfe_APA" SG_ 2000 DI1_Stunde 2000;
BA_ "GenSigTimeoutTime_PDC_PLA" SG_ 2000 DI1_Stunde 5000;
BA_ "GenSigTimeoutMsg_PDC_PLA" SG_ 2000 DI1_Stunde 2000;
BA_ "GenSigTimeoutTime_RKA_Plus" SG_ 2000 DI1_Stunde 5000;
BA_ "GenSigTimeoutMsg_RKA_Plus" SG_ 2000 DI1_Stunde 2000;
BA_ "GenSigTimeoutTime_Magne_Ride" SG_ 2000 DI1_Stunde 5000;
BA_ "GenSigTimeoutMsg_Magne_Ride" SG_ 2000 DI1_Stunde 2000;
BA_ "GenSigTimeoutTime_AFS" SG_ 2000 DI1_Stunde 5000;
BA_ "GenSigTimeoutMsg_AFS" SG_ 2000 DI1_Stunde 2000;
BA_ "GenSigTimeoutTime_ACC_Radar" SG_ 2000 DI1_Stunde 5000;
BA_ "GenSigTimeoutMsg_ACC_Radar" SG_ 2000 DI1_Stunde 2000;
BA_ "GenSigTimeoutTime_TRW_ESP" SG_ 2000 DI1_Stunde 5000;
BA_ "GenSigTimeoutMsg_TRW_ESP" SG_ 2000 DI1_Stunde 2000;
BA_ "GenSigTimeoutTime_EPB" SG_ 2000 DI1_Stunde 5000;
BA_ "GenSigTimeoutMsg_EPB" SG_ 2000 DI1_Stunde 2000;
BA_ "GenSigTimeoutTime_LWR" SG_ 2000 DI1_Stunde 5000;
BA_ "GenSigTimeoutMsg_LWR" SG_ 2000 DI1_Stunde 2000;
BA_ "GenSigTimeoutTime_Otto" SG_ 2000 DI1_Stunde 5000;
BA_ "GenSigTimeoutMsg_Otto" SG_ 2000 DI1_Stunde 2000;
BA_ "GenSigTimeoutTime_Diesel" SG_ 2000 DI1_Stunde 5000;
BA_ "GenSigTimeoutMsg_Diesel" SG_ 2000 DI1_Stunde 2000;
BA_ "GenSigTimeoutTime_Airbag" SG_ 2000 DI1_Stunde 5000;
BA_ "GenSigTimeoutMsg_Airbag" SG_ 2000 DI1_Stunde 2000;
BA_ "GenSigSendType" SG_ 2000 DI1_Stunde 0;
BA_ "GenSigTimeoutTime_Lenkhilfe_ZF_3" SG_ 2000 DI1_Tag 5000;
BA_ "GenSigTimeoutMsg_Lenkhilfe_ZF_3" SG_ 2000 DI1_Tag 2000;
BA_ "GenSigTimeoutTime_Lenkhilfe_ZF_2" SG_ 2000 DI1_Tag 5000;
BA_ "GenSigTimeoutMsg_Lenkhilfe_ZF_2" SG_ 2000 DI1_Tag 2000;
BA_ "GenSigTimeoutTime_FLA" SG_ 2000 DI1_Tag 5000;
BA_ "GenSigTimeoutMsg_FLA" SG_ 2000 DI1_Tag 2000;
BA_ "GenSigTimeoutTime_ACC_Lidar" SG_ 2000 DI1_Tag 5000;
BA_ "GenSigTimeoutMsg_ACC_Lidar" SG_ 2000 DI1_Tag 2000;
BA_ "GenSigTimeoutTime_Allrad" SG_ 2000 DI1_Tag 5000;
BA_ "GenSigTimeoutMsg_Allrad" SG_ 2000 DI1_Tag 2000;
BA_ "GenSigTimeoutTime_SWA" SG_ 2000 DI1_Tag 5000;
BA_ "GenSigTimeoutMsg_SWA" SG_ 2000 DI1_Tag 2000;
BA_ "GenSigTimeoutTime_HCA" SG_ 2000 DI1_Tag 5000;
BA_ "GenSigTimeoutMsg_HCA" SG_ 2000 DI1_Tag 2000;
BA_ "GenSigTimeoutTime_Hybrid_PWR" SG_ 2000 DI1_Tag 5000;
BA_ "GenSigTimeoutMsg_Hybrid_PWR" SG_ 2000 DI1_Tag 2000;
BA_ "GenSigTimeoutTime_Hybrid_BMS" SG_ 2000 DI1_Tag 5000;
BA_ "GenSigTimeoutMsg_Hybrid_BMS" SG_ 2000 DI1_Tag 2000;
BA_ "GenSigTimeoutTime_Hybrid_MSG" SG_ 2000 DI1_Tag 5000;
BA_ "GenSigTimeoutMsg_Hybrid_MSG" SG_ 2000 DI1_Tag 2000;
BA_ "GenSigTimeoutTime_Daempfer" SG_ 2000 DI1_Tag 5000;
BA_ "GenSigTimeoutMsg_Daempfer" SG_ 2000 DI1_Tag 2000;
BA_ "GenSigTimeoutTime_VAQ" SG_ 2000 DI1_Tag 5000;
BA_ "GenSigTimeoutMsg_VAQ" SG_ 2000 DI1_Tag 2000;
BA_ "GenSigTimeoutTime_Lenkhilfe_APA" SG_ 2000 DI1_Tag 5000;
BA_ "GenSigTimeoutMsg_Lenkhilfe_APA" SG_ 2000 DI1_Tag 2000;
BA_ "GenSigTimeoutTime_PDC_PLA" SG_ 2000 DI1_Tag 5000;
BA_ "GenSigTimeoutMsg_PDC_PLA" SG_ 2000 DI1_Tag 2000;
BA_ "GenSigTimeoutTime_RKA_Plus" SG_ 2000 DI1_Tag 5000;
BA_ "GenSigTimeoutMsg_RKA_Plus" SG_ 2000 DI1_Tag 2000;
BA_ "GenSigTimeoutTime_Magne_Ride" SG_ 2000 DI1_Tag 5000;
BA_ "GenSigTimeoutMsg_Magne_Ride" SG_ 2000 DI1_Tag 2000;
BA_ "GenSigTimeoutTime_AFS" SG_ 2000 DI1_Tag 5000;
BA_ "GenSigTimeoutMsg_AFS" SG_ 2000 DI1_Tag 2000;
BA_ "GenSigTimeoutTime_ACC_Radar" SG_ 2000 DI1_Tag 5000;
BA_ "GenSigTimeoutMsg_ACC_Radar" SG_ 2000 DI1_Tag 2000;
BA_ "GenSigTimeoutTime_TRW_ESP" SG_ 2000 DI1_Tag 5000;
BA_ "GenSigTimeoutMsg_TRW_ESP" SG_ 2000 DI1_Tag 2000;
BA_ "GenSigTimeoutTime_EPB" SG_ 2000 DI1_Tag 5000;
BA_ "GenSigTimeoutMsg_EPB" SG_ 2000 DI1_Tag 2000;
BA_ "GenSigTimeoutTime_Teves_MK70_MAB" SG_ 2000 DI1_Tag 5000;
BA_ "GenSigTimeoutMsg_Teves_MK70_MAB" SG_ 2000 DI1_Tag 2000;
BA_ "GenSigTimeoutTime_LWR" SG_ 2000 DI1_Tag 5000;
BA_ "GenSigTimeoutMsg_LWR" SG_ 2000 DI1_Tag 2000;
BA_ "GenSigTimeoutTime_Teves_MK60_ESP" SG_ 2000 DI1_Tag 5000;
BA_ "GenSigTimeoutMsg_Teves_MK60_ESP" SG_ 2000 DI1_Tag 2000;
BA_ "GenSigTimeoutTime_Otto" SG_ 2000 DI1_Tag 5000;
BA_ "GenSigTimeoutMsg_Otto" SG_ 2000 DI1_Tag 2000;
BA_ "GenSigTimeoutTime_Diesel" SG_ 2000 DI1_Tag 5000;
BA_ "GenSigTimeoutMsg_Diesel" SG_ 2000 DI1_Tag 2000;
BA_ "GenSigTimeoutTime_Airbag" SG_ 2000 DI1_Tag 5000;
BA_ "GenSigTimeoutMsg_Airbag" SG_ 2000 DI1_Tag 2000;
BA_ "GenSigSendType" SG_ 2000 DI1_Tag 0;
BA_ "GenSigTimeoutTime_FLA" SG_ 2000 DI1_KM_Stand_alt 5000;
BA_ "GenSigTimeoutMsg_FLA" SG_ 2000 DI1_KM_Stand_alt 2000;
BA_ "GenSigTimeoutTime_ACC_Lidar" SG_ 2000 DI1_KM_Stand_alt 5000;
BA_ "GenSigTimeoutMsg_ACC_Lidar" SG_ 2000 DI1_KM_Stand_alt 2000;
BA_ "GenSigTimeoutTime_Allrad" SG_ 2000 DI1_KM_Stand_alt 5000;
BA_ "GenSigTimeoutMsg_Allrad" SG_ 2000 DI1_KM_Stand_alt 2000;
BA_ "GenSigTimeoutTime_SWA" SG_ 2000 DI1_KM_Stand_alt 5000;
BA_ "GenSigTimeoutMsg_SWA" SG_ 2000 DI1_KM_Stand_alt 2000;
BA_ "GenSigTimeoutTime_Daempfer" SG_ 2000 DI1_KM_Stand_alt 5000;
BA_ "GenSigTimeoutMsg_Daempfer" SG_ 2000 DI1_KM_Stand_alt 2000;
BA_ "GenSigTimeoutTime_HCA" SG_ 2000 DI1_KM_Stand_alt 5000;
BA_ "GenSigTimeoutMsg_HCA" SG_ 2000 DI1_KM_Stand_alt 2000;
BA_ "GenSigTimeoutTime_Hybrid_PWR" SG_ 2000 DI1_KM_Stand_alt 5000;
BA_ "GenSigTimeoutMsg_Hybrid_PWR" SG_ 2000 DI1_KM_Stand_alt 2000;
BA_ "GenSigTimeoutTime_Hybrid_BMS" SG_ 2000 DI1_KM_Stand_alt 5000;
BA_ "GenSigTimeoutMsg_Hybrid_BMS" SG_ 2000 DI1_KM_Stand_alt 2000;
BA_ "GenSigTimeoutTime_Hybrid_MSG" SG_ 2000 DI1_KM_Stand_alt 5000;
BA_ "GenSigTimeoutMsg_Hybrid_MSG" SG_ 2000 DI1_KM_Stand_alt 2000;
BA_ "GenSigTimeoutTime_VAQ" SG_ 2000 DI1_KM_Stand_alt 5000;
BA_ "GenSigTimeoutMsg_VAQ" SG_ 2000 DI1_KM_Stand_alt 2000;
BA_ "GenSigTimeoutTime_Lenkhilfe_APA" SG_ 2000 DI1_KM_Stand_alt 5000;
BA_ "GenSigTimeoutMsg_Lenkhilfe_APA" SG_ 2000 DI1_KM_Stand_alt 2000;
BA_ "GenSigTimeoutTime_PDC_PLA" SG_ 2000 DI1_KM_Stand_alt 5000;
BA_ "GenSigTimeoutMsg_PDC_PLA" SG_ 2000 DI1_KM_Stand_alt 2000;
BA_ "GenSigTimeoutTime_RKA_Plus" SG_ 2000 DI1_KM_Stand_alt 5000;
BA_ "GenSigTimeoutMsg_RKA_Plus" SG_ 2000 DI1_KM_Stand_alt 2000;
BA_ "GenSigTimeoutTime_Magne_Ride" SG_ 2000 DI1_KM_Stand_alt 5000;
BA_ "GenSigTimeoutMsg_Magne_Ride" SG_ 2000 DI1_KM_Stand_alt 2000;
BA_ "GenSigTimeoutTime_AFS" SG_ 2000 DI1_KM_Stand_alt 5000;
BA_ "GenSigTimeoutMsg_AFS" SG_ 2000 DI1_KM_Stand_alt 2000;
BA_ "GenSigTimeoutTime_ACC_Radar" SG_ 2000 DI1_KM_Stand_alt 5000;
BA_ "GenSigTimeoutMsg_ACC_Radar" SG_ 2000 DI1_KM_Stand_alt 2000;
BA_ "GenSigTimeoutTime_TRW_ESP" SG_ 2000 DI1_KM_Stand_alt 5000;
BA_ "GenSigTimeoutMsg_TRW_ESP" SG_ 2000 DI1_KM_Stand_alt 2000;
BA_ "GenSigTimeoutTime_EPB" SG_ 2000 DI1_KM_Stand_alt 5000;
BA_ "GenSigTimeoutMsg_EPB" SG_ 2000 DI1_KM_Stand_alt 2000;
BA_ "GenSigTimeoutTime_LWR" SG_ 2000 DI1_KM_Stand_alt 5000;
BA_ "GenSigTimeoutMsg_LWR" SG_ 2000 DI1_KM_Stand_alt 2000;
BA_ "GenSigTimeoutTime_Otto" SG_ 2000 DI1_KM_Stand_alt 5000;
BA_ "GenSigTimeoutMsg_Otto" SG_ 2000 DI1_KM_Stand_alt 2000;
BA_ "GenSigTimeoutTime_Diesel" SG_ 2000 DI1_KM_Stand_alt 5000;
BA_ "GenSigTimeoutMsg_Diesel" SG_ 2000 DI1_KM_Stand_alt 2000;
BA_ "GenSigTimeoutTime_Airbag" SG_ 2000 DI1_KM_Stand_alt 5000;
BA_ "GenSigTimeoutMsg_Airbag" SG_ 2000 DI1_KM_Stand_alt 2000;
BA_ "GenSigSendType" SG_ 2000 DI1_KM_Stand_alt 0;
BA_ "GenSigStartValue" SG_ 2000 DI1_KM_Stand_alt 1;
BA_ "GenSigTimeoutTime_Lenkhilfe_ZF_2" SG_ 2000 DI1_Zeit_alt 5000;
BA_ "GenSigTimeoutMsg_Lenkhilfe_ZF_2" SG_ 2000 DI1_Zeit_alt 2000;
BA_ "GenSigTimeoutTime_Lenkhilfe_ZF_3" SG_ 2000 DI1_Zeit_alt 5000;
BA_ "GenSigTimeoutMsg_Lenkhilfe_ZF_3" SG_ 2000 DI1_Zeit_alt 2000;
BA_ "GenSigTimeoutTime_Teves_MK60_ESP" SG_ 2000 DI1_Zeit_alt 5000;
BA_ "GenSigTimeoutMsg_Teves_MK60_ESP" SG_ 2000 DI1_Zeit_alt 2000;
BA_ "GenSigTimeoutTime_FLA" SG_ 2000 DI1_Zeit_alt 5000;
BA_ "GenSigTimeoutMsg_FLA" SG_ 2000 DI1_Zeit_alt 2000;
BA_ "GenSigTimeoutTime_ACC_Lidar" SG_ 2000 DI1_Zeit_alt 5000;
BA_ "GenSigTimeoutMsg_ACC_Lidar" SG_ 2000 DI1_Zeit_alt 2000;
BA_ "GenSigTimeoutTime_Allrad" SG_ 2000 DI1_Zeit_alt 5000;
BA_ "GenSigTimeoutMsg_Allrad" SG_ 2000 DI1_Zeit_alt 2000;
BA_ "GenSigTimeoutTime_SWA" SG_ 2000 DI1_Zeit_alt 5000;
BA_ "GenSigTimeoutMsg_SWA" SG_ 2000 DI1_Zeit_alt 2000;
BA_ "GenSigTimeoutTime_Daempfer" SG_ 2000 DI1_Zeit_alt 5000;
BA_ "GenSigTimeoutMsg_Daempfer" SG_ 2000 DI1_Zeit_alt 2000;
BA_ "GenSigTimeoutTime_HCA" SG_ 2000 DI1_Zeit_alt 5000;
BA_ "GenSigTimeoutMsg_HCA" SG_ 2000 DI1_Zeit_alt 2000;
BA_ "GenSigTimeoutTime_Hybrid_BMS" SG_ 2000 DI1_Zeit_alt 5000;
BA_ "GenSigTimeoutMsg_Hybrid_BMS" SG_ 2000 DI1_Zeit_alt 2000;
BA_ "GenSigTimeoutTime_Hybrid_PWR" SG_ 2000 DI1_Zeit_alt 5000;
BA_ "GenSigTimeoutMsg_Hybrid_PWR" SG_ 2000 DI1_Zeit_alt 2000;
BA_ "GenSigTimeoutTime_Hybrid_MSG" SG_ 2000 DI1_Zeit_alt 5000;
BA_ "GenSigTimeoutMsg_Hybrid_MSG" SG_ 2000 DI1_Zeit_alt 2000;
BA_ "GenSigTimeoutTime_Lenkhilfe_APA" SG_ 2000 DI1_Zeit_alt 5000;
BA_ "GenSigTimeoutMsg_Lenkhilfe_APA" SG_ 2000 DI1_Zeit_alt 2000;
BA_ "GenSigTimeoutTime_PDC_PLA" SG_ 2000 DI1_Zeit_alt 5000;
BA_ "GenSigTimeoutMsg_PDC_PLA" SG_ 2000 DI1_Zeit_alt 2000;
BA_ "GenSigTimeoutTime_RKA_Plus" SG_ 2000 DI1_Zeit_alt 5000;
BA_ "GenSigTimeoutMsg_RKA_Plus" SG_ 2000 DI1_Zeit_alt 2000;
BA_ "GenSigTimeoutTime_Magne_Ride" SG_ 2000 DI1_Zeit_alt 5000;
BA_ "GenSigTimeoutMsg_Magne_Ride" SG_ 2000 DI1_Zeit_alt 2000;
BA_ "GenSigTimeoutTime_AFS" SG_ 2000 DI1_Zeit_alt 5000;
BA_ "GenSigTimeoutMsg_AFS" SG_ 2000 DI1_Zeit_alt 2000;
BA_ "GenSigTimeoutTime_ACC_Radar" SG_ 2000 DI1_Zeit_alt 5000;
BA_ "GenSigTimeoutMsg_ACC_Radar" SG_ 2000 DI1_Zeit_alt 2000;
BA_ "GenSigTimeoutTime_TRW_ESP" SG_ 2000 DI1_Zeit_alt 5000;
BA_ "GenSigTimeoutMsg_TRW_ESP" SG_ 2000 DI1_Zeit_alt 2000;
BA_ "GenSigTimeoutTime_EPB" SG_ 2000 DI1_Zeit_alt 5000;
BA_ "GenSigTimeoutMsg_EPB" SG_ 2000 DI1_Zeit_alt 2000;
BA_ "GenSigTimeoutTime_LWR" SG_ 2000 DI1_Zeit_alt 5000;
BA_ "GenSigTimeoutMsg_LWR" SG_ 2000 DI1_Zeit_alt 2000;
BA_ "GenSigTimeoutTime_Otto" SG_ 2000 DI1_Zeit_alt 5000;
BA_ "GenSigTimeoutMsg_Otto" SG_ 2000 DI1_Zeit_alt 2000;
BA_ "GenSigTimeoutTime_Diesel" SG_ 2000 DI1_Zeit_alt 5000;
BA_ "GenSigTimeoutMsg_Diesel" SG_ 2000 DI1_Zeit_alt 2000;
BA_ "GenSigTimeoutTime_Airbag" SG_ 2000 DI1_Zeit_alt 5000;
BA_ "GenSigTimeoutMsg_Airbag" SG_ 2000 DI1_Zeit_alt 2000;
BA_ "GenSigSendType" SG_ 2000 DI1_Zeit_alt 0;
BA_ "GenSigStartValue" SG_ 2000 DI1_Zeit_alt 1;
BA_ "GenSigTimeoutTime_Teves_MK60_ESP" SG_ 2000 DI1_VerlernZaehl 5000;
BA_ "GenSigTimeoutMsg_Teves_MK60_ESP" SG_ 2000 DI1_VerlernZaehl 2000;
BA_ "GenSigTimeoutTime_FLA" SG_ 2000 DI1_VerlernZaehl 5000;
BA_ "GenSigTimeoutMsg_FLA" SG_ 2000 DI1_VerlernZaehl 2000;
BA_ "GenSigTimeoutTime_ACC_Lidar" SG_ 2000 DI1_VerlernZaehl 5000;
BA_ "GenSigTimeoutMsg_ACC_Lidar" SG_ 2000 DI1_VerlernZaehl 2000;
BA_ "GenSigTimeoutTime_Allrad" SG_ 2000 DI1_VerlernZaehl 5000;
BA_ "GenSigTimeoutMsg_Allrad" SG_ 2000 DI1_VerlernZaehl 2000;
BA_ "GenSigTimeoutTime_SWA" SG_ 2000 DI1_VerlernZaehl 5000;
BA_ "GenSigTimeoutMsg_SWA" SG_ 2000 DI1_VerlernZaehl 2000;
BA_ "GenSigTimeoutTime_HCA" SG_ 2000 DI1_VerlernZaehl 5000;
BA_ "GenSigTimeoutMsg_HCA" SG_ 2000 DI1_VerlernZaehl 2000;
BA_ "GenSigTimeoutTime_Hybrid_PWR" SG_ 2000 DI1_VerlernZaehl 5000;
BA_ "GenSigTimeoutMsg_Hybrid_PWR" SG_ 2000 DI1_VerlernZaehl 2000;
BA_ "GenSigTimeoutTime_Hybrid_BMS" SG_ 2000 DI1_VerlernZaehl 5000;
BA_ "GenSigTimeoutMsg_Hybrid_BMS" SG_ 2000 DI1_VerlernZaehl 2000;
BA_ "GenSigTimeoutTime_Hybrid_MSG" SG_ 2000 DI1_VerlernZaehl 5000;
BA_ "GenSigTimeoutMsg_Hybrid_MSG" SG_ 2000 DI1_VerlernZaehl 2000;
BA_ "GenSigTimeoutTime_Daempfer" SG_ 2000 DI1_VerlernZaehl 5000;
BA_ "GenSigTimeoutMsg_Daempfer" SG_ 2000 DI1_VerlernZaehl 2000;
BA_ "GenSigTimeoutTime_VAQ" SG_ 2000 DI1_VerlernZaehl 5000;
BA_ "GenSigTimeoutMsg_VAQ" SG_ 2000 DI1_VerlernZaehl 2000;
BA_ "GenSigTimeoutTime_Lenkhilfe_APA" SG_ 2000 DI1_VerlernZaehl 5000;
BA_ "GenSigTimeoutMsg_Lenkhilfe_APA" SG_ 2000 DI1_VerlernZaehl 2000;
BA_ "GenSigTimeoutTime_PDC_PLA" SG_ 2000 DI1_VerlernZaehl 5000;
BA_ "GenSigTimeoutMsg_PDC_PLA" SG_ 2000 DI1_VerlernZaehl 2000;
BA_ "GenSigTimeoutTime_RKA_Plus" SG_ 2000 DI1_VerlernZaehl 5000;
BA_ "GenSigTimeoutMsg_RKA_Plus" SG_ 2000 DI1_VerlernZaehl 2000;
BA_ "GenSigTimeoutTime_Magne_Ride" SG_ 2000 DI1_VerlernZaehl 5000;
BA_ "GenSigTimeoutMsg_Magne_Ride" SG_ 2000 DI1_VerlernZaehl 2000;
BA_ "GenSigTimeoutTime_AFS" SG_ 2000 DI1_VerlernZaehl 5000;
BA_ "GenSigTimeoutMsg_AFS" SG_ 2000 DI1_VerlernZaehl 2000;
BA_ "GenSigTimeoutTime_ACC_Radar" SG_ 2000 DI1_VerlernZaehl 5000;
BA_ "GenSigTimeoutMsg_ACC_Radar" SG_ 2000 DI1_VerlernZaehl 2000;
BA_ "GenSigTimeoutTime_TRW_ESP" SG_ 2000 DI1_VerlernZaehl 5000;
BA_ "GenSigTimeoutMsg_TRW_ESP" SG_ 2000 DI1_VerlernZaehl 2000;
BA_ "GenSigTimeoutTime_EPB" SG_ 2000 DI1_VerlernZaehl 5000;
BA_ "GenSigTimeoutMsg_EPB" SG_ 2000 DI1_VerlernZaehl 2000;
BA_ "GenSigTimeoutTime_LWR" SG_ 2000 DI1_VerlernZaehl 5000;
BA_ "GenSigTimeoutMsg_LWR" SG_ 2000 DI1_VerlernZaehl 2000;
BA_ "GenSigTimeoutTime_Otto" SG_ 2000 DI1_VerlernZaehl 5000;
BA_ "GenSigTimeoutMsg_Otto" SG_ 2000 DI1_VerlernZaehl 2000;
BA_ "GenSigTimeoutTime_Diesel" SG_ 2000 DI1_VerlernZaehl 5000;
BA_ "GenSigTimeoutMsg_Diesel" SG_ 2000 DI1_VerlernZaehl 2000;
BA_ "GenSigTimeoutTime_Airbag" SG_ 2000 DI1_VerlernZaehl 5000;
BA_ "GenSigTimeoutMsg_Airbag" SG_ 2000 DI1_VerlernZaehl 2000;
BA_ "GenSigSendType" SG_ 2000 DI1_VerlernZaehl 0;
BA_ "GenSigTimeoutTime_TRW_ESP" SG_ 1500 VL1_Getr_SG 1000;
BA_ "GenSigTimeoutMsg_TRW_ESP" SG_ 1500 VL1_Getr_SG 1500;
BA_ "GenSigSendType" SG_ 1500 VL1_Getr_SG 0;
BA_ "INIT" SG_ 1500 VL1_Getr_SG "const";
BA_ "GenSigTimeoutTime_Hybrid_MSG" SG_ 1500 VL1_Airbag 1000;
BA_ "GenSigTimeoutMsg_Hybrid_MSG" SG_ 1500 VL1_Airbag 1500;
BA_ "GenSigTimeoutTime_TRW_ESP" SG_ 1500 VL1_Airbag 1000;
BA_ "GenSigTimeoutMsg_TRW_ESP" SG_ 1500 VL1_Airbag 1500;
BA_ "GenSigTimeoutTime_Otto" SG_ 1500 VL1_Airbag 1000;
BA_ "GenSigTimeoutMsg_Otto" SG_ 1500 VL1_Airbag 1500;
BA_ "GenSigSendType" SG_ 1500 VL1_Airbag 0;
BA_ "INIT" SG_ 1500 VL1_Airbag "const";
BA_ "GenSigTimeoutTime_TRW_ESP" SG_ 1500 VL1_Motor_SG 1000;
BA_ "GenSigTimeoutMsg_TRW_ESP" SG_ 1500 VL1_Motor_SG 1500;
BA_ "GenSigSendType" SG_ 1500 VL1_Motor_SG 0;
BA_ "INIT" SG_ 1500 VL1_Motor_SG "const";
BA_ "GenSigTimeoutTime_Hybrid_MSG" SG_ 1500 VL1_ABS 1000;
BA_ "GenSigTimeoutMsg_Hybrid_MSG" SG_ 1500 VL1_ABS 1500;
BA_ "GenSigTimeoutTime_Otto" SG_ 1500 VL1_ABS 1000;
BA_ "GenSigTimeoutMsg_Otto" SG_ 1500 VL1_ABS 1500;
BA_ "GenSigSendType" SG_ 1500 VL1_ABS 0;
BA_ "INIT" SG_ 1500 VL1_ABS "const";
BA_ "GenSigSendType" SG_ 1500 VL1_res_08 0;
BA_ "GenSigSendType" SG_ 1500 VL1_EPB 0;
BA_ "INIT" SG_ 1500 VL1_EPB "const";
BA_ "GenSigSendType" SG_ 1500 VL1_Kombi 0;
BA_ "INIT" SG_ 1500 VL1_Kombi "const";
BA_ "GenSigTimeoutTime_TRW_ESP" SG_ 1500 VL1_Allrad 1000;
BA_ "GenSigTimeoutMsg_TRW_ESP" SG_ 1500 VL1_Allrad 1500;
BA_ "GenSigTimeoutTime_Teves_MK70_MAB" SG_ 1500 VL1_Allrad 1000;
BA_ "GenSigTimeoutMsg_Teves_MK70_MAB" SG_ 1500 VL1_Allrad 1500;
BA_ "GenSigTimeoutTime_Teves_MK60_ESP" SG_ 1500 VL1_Allrad 1000;
BA_ "GenSigTimeoutMsg_Teves_MK60_ESP" SG_ 1500 VL1_Allrad 1500;
BA_ "GenSigSendType" SG_ 1500 VL1_Allrad 0;
BA_ "INIT" SG_ 1500 VL1_Allrad "const";
BA_ "GenSigTimeoutTime_TRW_ESP" SG_ 1500 VL1_LSM 1000;
BA_ "GenSigTimeoutMsg_TRW_ESP" SG_ 1500 VL1_LSM 1500;
BA_ "GenSigTimeoutTime_Hybrid_MSG" SG_ 1500 VL1_LSM 1000;
BA_ "GenSigTimeoutMsg_Hybrid_MSG" SG_ 1500 VL1_LSM 1500;
BA_ "GenSigTimeoutTime_Otto" SG_ 1500 VL1_LSM 1000;
BA_ "GenSigTimeoutMsg_Otto" SG_ 1500 VL1_LSM 1500;
BA_ "GenSigSendType" SG_ 1500 VL1_LSM 0;
BA_ "INIT" SG_ 1500 VL1_LSM "const";
BA_ "GenSigSendType" SG_ 1500 VL1_Lenkhilfe 0;
BA_ "INIT" SG_ 1500 VL1_Lenkhilfe "const";
BA_ "GenSigTimeoutTime_Teves_MK60_ESP" SG_ 1500 VL1_ADR 1000;
BA_ "GenSigTimeoutMsg_Teves_MK60_ESP" SG_ 1500 VL1_ADR 1500;
BA_ "GenSigTimeoutTime_TRW_ESP" SG_ 1500 VL1_ADR 1000;
BA_ "GenSigTimeoutMsg_TRW_ESP" SG_ 1500 VL1_ADR 1500;
BA_ "GenSigSendType" SG_ 1500 VL1_ADR 0;
BA_ "INIT" SG_ 1500 VL1_ADR "const";
BA_ "GenSigSendType" SG_ 1500 VL1_Daempfer 0;
BA_ "INIT" SG_ 1500 VL1_Daempfer "const";
BA_ "GenSigSendType" SG_ 1500 VL1_dyn_LWR 0;
BA_ "INIT" SG_ 1500 VL1_dyn_LWR "const";
BA_ "GenSigSendType" SG_ 1500 VL1_DAB 0;
BA_ "INIT" SG_ 1500 VL1_DAB "const";
BA_ "GenSigSendType" SG_ 1500 VL1_MotorSlave 0;
BA_ "INIT" SG_ 1500 VL1_MotorSlave "const";
BA_ "GenSigSendType" SG_ 1500 VL1_res_13 0;
BA_ "GenSigSendType" SG_ 1500 VL1_TSG_BT 0;
BA_ "INIT" SG_ 1500 VL1_TSG_BT "const";
BA_ "GenSigSendType" SG_ 1500 VL1_TSG_FT 0;
BA_ "INIT" SG_ 1500 VL1_TSG_FT "const";
BA_ "GenSigSendType" SG_ 1500 VL1_TSG_HL 0;
BA_ "INIT" SG_ 1500 VL1_TSG_HL "const";
BA_ "GenSigSendType" SG_ 1500 VL1_ZKE 0;
BA_ "INIT" SG_ 1500 VL1_ZKE "const";
BA_ "GenSigTimeoutTime_Hybrid_MSG" SG_ 1500 VL1_BSG_Komf 1000;
BA_ "GenSigTimeoutMsg_Hybrid_MSG" SG_ 1500 VL1_BSG_Komf 1500;
BA_ "GenSigTimeoutTime_Otto" SG_ 1500 VL1_BSG_Komf 1000;
BA_ "GenSigTimeoutMsg_Otto" SG_ 1500 VL1_BSG_Komf 1500;
BA_ "GenSigSendType" SG_ 1500 VL1_BSG_Komf 0;
BA_ "INIT" SG_ 1500 VL1_BSG_Komf "const";
BA_ "GenSigSendType" SG_ 1500 VL1_Memory 0;
BA_ "INIT" SG_ 1500 VL1_Memory "const";
BA_ "GenSigSendType" SG_ 1500 VL1_Dachmodul_K 0;
BA_ "INIT" SG_ 1500 VL1_Dachmodul_K "const";
BA_ "GenSigSendType" SG_ 1500 VL1_TSG_HR 0;
BA_ "INIT" SG_ 1500 VL1_TSG_HR "const";
BA_ "GenSigSendType" SG_ 1500 VL1_Zentralelektrik_II 0;
BA_ "INIT" SG_ 1500 VL1_Zentralelektrik_II "const";
BA_ "GenSigTimeoutTime_Hybrid_MSG" SG_ 1500 VL1_Lenksaeule 1000;
BA_ "GenSigTimeoutMsg_Hybrid_MSG" SG_ 1500 VL1_Lenksaeule 1500;
BA_ "GenSigTimeoutTime_Otto" SG_ 1500 VL1_Lenksaeule 1000;
BA_ "GenSigTimeoutMsg_Otto" SG_ 1500 VL1_Lenksaeule 1500;
BA_ "GenSigSendType" SG_ 1500 VL1_Lenksaeule 0;
BA_ "INIT" SG_ 1500 VL1_Lenksaeule "const";
BA_ "GenSigSendType" SG_ 1500 VL1_Einparkhilfe 0;
BA_ "INIT" SG_ 1500 VL1_Einparkhilfe "const";
BA_ "GenSigTimeoutTime_Hybrid_MSG" SG_ 1500 VL1_Gateway 1000;
BA_ "GenSigTimeoutMsg_Hybrid_MSG" SG_ 1500 VL1_Gateway 1500;
BA_ "GenSigTimeoutTime_Otto" SG_ 1500 VL1_Gateway 1000;
BA_ "GenSigTimeoutMsg_Otto" SG_ 1500 VL1_Gateway 1500;
BA_ "GenSigSendType" SG_ 1500 VL1_Gateway 0;
BA_ "INIT" SG_ 1500 VL1_Gateway "const";
BA_ "GenSigSendType" SG_ 1500 VL1_RDK 0;
BA_ "INIT" SG_ 1500 VL1_RDK "const";
BA_ "GenSigSendType" SG_ 1500 VL1_PTC_Heizung 0;
BA_ "INIT" SG_ 1500 VL1_PTC_Heizung "const";
BA_ "GenSigSendType" SG_ 1500 VL1_Standheiz 0;
BA_ "INIT" SG_ 1500 VL1_Standheiz "const";
BA_ "GenSigTimeoutTime_Hybrid_MSG" SG_ 1500 VL1_Clima_Komf 1000;
BA_ "GenSigTimeoutMsg_Hybrid_MSG" SG_ 1500 VL1_Clima_Komf 1500;
BA_ "GenSigTimeoutTime_Otto" SG_ 1500 VL1_Clima_Komf 1000;
BA_ "GenSigTimeoutMsg_Otto" SG_ 1500 VL1_Clima_Komf 1500;
BA_ "GenSigTimeoutTime_Diesel" SG_ 1500 VL1_Clima_Komf 1000;
BA_ "GenSigTimeoutMsg_Diesel" SG_ 1500 VL1_Clima_Komf 1500;
BA_ "GenSigSendType" SG_ 1500 VL1_Clima_Komf 0;
BA_ "INIT" SG_ 1500 VL1_Clima_Komf "const";
BA_ "GenSigSendType" SG_ 1500 VL1_res_42 0;
BA_ "GenSigSendType" SG_ 1500 VL1_RSE_I 0;
BA_ "INIT" SG_ 1500 VL1_RSE_I "const";
BA_ "GenSigSendType" SG_ 1500 VL1_Verdeck 0;
BA_ "INIT" SG_ 1500 VL1_Verdeck "const";
BA_ "GenSigSendType" SG_ 1500 VL1_MDI_I 0;
BA_ "INIT" SG_ 1500 VL1_MDI_I "const";
BA_ "GenSigSendType" SG_ 1500 VL1_Memory_BF 0;
BA_ "INIT" SG_ 1500 VL1_Memory_BF "const";
BA_ "GenSigSendType" SG_ 1500 VL1_Heckdeckel 0;
BA_ "INIT" SG_ 1500 VL1_Heckdeckel "const";
BA_ "GenSigTimeoutTime_TRW_ESP" SG_ 1500 VL1_Anhaenger 1000;
BA_ "GenSigTimeoutMsg_TRW_ESP" SG_ 1500 VL1_Anhaenger 1500;
BA_ "GenSigSendType" SG_ 1500 VL1_Anhaenger 0;
BA_ "INIT" SG_ 1500 VL1_Anhaenger "const";
BA_ "GenSigSendType" SG_ 1500 VL1_Easy_Entry_VF 0;
BA_ "INIT" SG_ 1500 VL1_Easy_Entry_VF "const";
BA_ "GenSigSendType" SG_ 1500 VL1_Sonderfzg_SG 0;
BA_ "INIT" SG_ 1500 VL1_Sonderfzg_SG "const";
BA_ "GenSigSendType" SG_ 1500 VL1_Tastenmodul 0;
BA_ "INIT" SG_ 1500 VL1_Tastenmodul "const";
BA_ "GenSigSendType" SG_ 1500 VL1_Radio 0;
BA_ "INIT" SG_ 1500 VL1_Radio "const";
BA_ "GenSigSendType" SG_ 1500 VL1_Telefon 0;
BA_ "INIT" SG_ 1500 VL1_Telefon "const";
BA_ "GenSigSendType" SG_ 1500 VL1_Navigation 0;
BA_ "INIT" SG_ 1500 VL1_Navigation "const";
BA_ "GenSigSendType" SG_ 1500 VL1_Neigungsmodul_I 0;
BA_ "GenSigSendType" SG_ 1500 VL1_ADR_getrennt 0;
BA_ "INIT" SG_ 1500 VL1_ADR_getrennt "0/1";
BA_ "GenSigSendType" SG_ 1500 VL1_DSP 0;
BA_ "INIT" SG_ 1500 VL1_DSP "const";
BA_ "GenSigSendType" SG_ 1500 VL1_Easy_Entry_VB 0;
BA_ "INIT" SG_ 1500 VL1_Easy_Entry_VB "const";
BA_ "GenSigSendType" SG_ 1500 VL1_Telematik 0;
BA_ "INIT" SG_ 1500 VL1_Telematik "const";
BA_ "GenSigSendType" SG_ 1500 VL1_TV_Tuner 0;
BA_ "INIT" SG_ 1500 VL1_TV_Tuner "const";
BA_ "GenSigSendType" SG_ 1500 VL1_WFS_K 0;
BA_ "INIT" SG_ 1500 VL1_WFS_K "const";
BA_ "GenSigSendType" SG_ 1500 VL1_Kompass 0;
BA_ "INIT" SG_ 1500 VL1_Kompass "const";
BA_ "GenSigSendType" SG_ 1500 VL1_Rearview 0;
BA_ "INIT" SG_ 1500 VL1_Rearview "const";
BA_ "GenSigSendType" SG_ 1500 VL1_GSM_Pager 0;
BA_ "INIT" SG_ 1500 VL1_GSM_Pager "const";
BA_ "GenSigSendType" SG_ 1500 VL1_InfoElektronik 0;
BA_ "INIT" SG_ 1500 VL1_InfoElektronik "const";
BA_ "GenSigSendType" SG_ 1500 VL1_Kombi_KBI 0;
BA_ "INIT" SG_ 1500 VL1_Kombi_KBI "const";
BA_ "GenSigTimeoutTime_Hybrid_MSG" SG_ 1500 VL1_Soll_eq_Ist 1000;
BA_ "GenSigTimeoutMsg_Hybrid_MSG" SG_ 1500 VL1_Soll_eq_Ist 1500;
BA_ "GenSigTimeoutTime_Otto" SG_ 1500 VL1_Soll_eq_Ist 1000;
BA_ "GenSigTimeoutMsg_Otto" SG_ 1500 VL1_Soll_eq_Ist 1500;
BA_ "GenSigSendType" SG_ 1500 VL1_Soll_eq_Ist 0;
BA_ "INIT" SG_ 1500 VL1_Soll_eq_Ist "const";
BA_ "GenSigSendType" SG_ 1500 VL1_Quersperre 0;
BA_ "INIT" SG_ 1500 VL1_Quersperre "const";
BA_ "GenSigSendType" SG_ 1500 VL1_SWA 0;
BA_ "INIT" SG_ 1500 VL1_SWA "const";
BA_ "GenSigSendType" SG_ 1500 VL1_PLA 0;
BA_ "INIT" SG_ 1500 VL1_PLA "const";
BA_ "GenSigTimeoutTime_HCA" SG_ 1500 VL1_HCA 1000;
BA_ "GenSigTimeoutMsg_HCA" SG_ 1500 VL1_HCA 1500;
BA_ "GenSigSendType" SG_ 1500 VL1_HCA 0;
BA_ "INIT" SG_ 1500 VL1_HCA "const";
BA_ "GenSigSendType" SG_ 1500 VL1_WFS_KBI 0;
BA_ "INIT" SG_ 1500 VL1_WFS_KBI "const";
BA_ "GenSigSendType" SG_ 1500 VL1_RKA_Plus 0;
BA_ "INIT" SG_ 1500 VL1_RKA_Plus "const";
BA_ "GenSigSendType" SG_ 1504 CL1_Hecksch 0;
BA_ "GenSigTimeoutTime_Diesel" SG_ 1504 CL1_Heizleist 1000;
BA_ "GenSigTimeoutMsg_Diesel" SG_ 1504 CL1_Heizleist 1504;
BA_ "GenSigSendType" SG_ 1504 CL1_Heizleist 0;
BA_ "GenSigTimeoutTime_Hybrid_MSG" SG_ 1504 CL1_Fa_Zuheiz 1000;
BA_ "GenSigTimeoutMsg_Hybrid_MSG" SG_ 1504 CL1_Fa_Zuheiz 1504;
BA_ "GenSigTimeoutTime_Diesel" SG_ 1504 CL1_Fa_Zuheiz 1000;
BA_ "GenSigTimeoutMsg_Diesel" SG_ 1504 CL1_Fa_Zuheiz 1504;
BA_ "GenSigSendType" SG_ 1504 CL1_Fa_Zuheiz 0;
BA_ "GenSigTimeoutTime_Hybrid_MSG" SG_ 1504 CL1_Kompressor 1000;
BA_ "GenSigTimeoutMsg_Hybrid_MSG" SG_ 1504 CL1_Kompressor 1504;
BA_ "GenSigTimeoutTime_Otto" SG_ 1504 CL1_Kompressor 1000;
BA_ "GenSigTimeoutMsg_Otto" SG_ 1504 CL1_Kompressor 1504;
BA_ "GenSigTimeoutTime_Diesel" SG_ 1504 CL1_Kompressor 1000;
BA_ "GenSigTimeoutMsg_Diesel" SG_ 1504 CL1_Kompressor 1504;
BA_ "GenSigSendType" SG_ 1504 CL1_Kompressor 0;
BA_ "GenSigTimeoutTime_Hybrid_MSG" SG_ 1504 CL1_Sta_Druck 1000;
BA_ "GenSigTimeoutMsg_Hybrid_MSG" SG_ 1504 CL1_Sta_Druck 1504;
BA_ "GenSigTimeoutTime_Otto" SG_ 1504 CL1_Sta_Druck 1000;
BA_ "GenSigTimeoutMsg_Otto" SG_ 1504 CL1_Sta_Druck 1504;
BA_ "GenSigSendType" SG_ 1504 CL1_Sta_Druck 0;
BA_ "GenSigSendType" SG_ 1504 CL1_Frontsch 0;
BA_ "GenSigTimeoutTime_Hybrid_MSG" SG_ 1504 CL1_Sta_Moment 1000;
BA_ "GenSigTimeoutMsg_Hybrid_MSG" SG_ 1504 CL1_Sta_Moment 1504;
BA_ "GenSigTimeoutTime_Otto" SG_ 1504 CL1_Sta_Moment 1000;
BA_ "GenSigTimeoutMsg_Otto" SG_ 1504 CL1_Sta_Moment 1504;
BA_ "GenSigSendType" SG_ 1504 CL1_Sta_Moment 0;
BA_ "GenSigTimeoutTime_Hybrid_MSG" SG_ 1504 CL1_Kompr_Last 1000;
BA_ "GenSigTimeoutMsg_Hybrid_MSG" SG_ 1504 CL1_Kompr_Last 1504;
BA_ "GenSigTimeoutTime_Otto" SG_ 1504 CL1_Kompr_Last 1000;
BA_ "GenSigTimeoutMsg_Otto" SG_ 1504 CL1_Kompr_Last 1504;
BA_ "GenSigTimeoutTime_Diesel" SG_ 1504 CL1_Kompr_Last 1000;
BA_ "GenSigTimeoutMsg_Diesel" SG_ 1504 CL1_Kompr_Last 1504;
BA_ "GenSigSendType" SG_ 1504 CL1_Kompr_Last 0;
BA_ "GenSigTimeoutTime_Hybrid_MSG" SG_ 1504 CL1_Druck 1000;
BA_ "GenSigTimeoutMsg_Hybrid_MSG" SG_ 1504 CL1_Druck 1504;
BA_ "GenSigTimeoutTime_Otto" SG_ 1504 CL1_Druck 1000;
BA_ "GenSigTimeoutMsg_Otto" SG_ 1504 CL1_Druck 1504;
BA_ "GenSigTimeoutTime_Diesel" SG_ 1504 CL1_Druck 1000;
BA_ "GenSigTimeoutMsg_Diesel" SG_ 1504 CL1_Druck 1504;
BA_ "GenSigSendType" SG_ 1504 CL1_Druck 0;
BA_ "GenSigSendType" SG_ 1504 CL1_Aussentemp 0;
BA_ "GenSigTimeoutTime_Otto" SG_ 1504 CL1_Gebl_last 1000;
BA_ "GenSigTimeoutMsg_Otto" SG_ 1504 CL1_Gebl_last 1504;
BA_ "GenSigTimeoutTime_Hybrid_BMS" SG_ 1504 CL1_Gebl_last 1000;
BA_ "GenSigTimeoutMsg_Hybrid_BMS" SG_ 1504 CL1_Gebl_last 1504;
BA_ "GenSigSendType" SG_ 1504 CL1_Gebl_last 0;
BA_ "GenSigSendType" SG_ 1504 CL1_Einheit_Temp 0;
BA_ "INIT" SG_ 1504 CL1_Einheit_Temp "const";
BA_ "GenSigTimeoutTime_Hybrid_MSG" SG_ 1504 CL1_Luefter 1000;
BA_ "GenSigTimeoutMsg_Hybrid_MSG" SG_ 1504 CL1_Luefter 1504;
BA_ "GenSigTimeoutTime_Otto" SG_ 1504 CL1_Luefter 1000;
BA_ "GenSigTimeoutMsg_Otto" SG_ 1504 CL1_Luefter 1504;
BA_ "GenSigTimeoutTime_Diesel" SG_ 1504 CL1_Luefter 1000;
BA_ "GenSigTimeoutMsg_Diesel" SG_ 1504 CL1_Luefter 1504;
BA_ "GenSigSendType" SG_ 1504 CL1_Luefter 0;
BA_ "GenSigSendType" SG_ 1504 CL1_Fehlereintr 0;
BA_ "GenSigSendType" SG_ 1504 CL1_WAPU_Zuschaltung 0;
BA_ "GenSigSendType" SG_ 1504 CL1_Restwaerme 0;
BA_ "GenSigTimeoutTime_Hybrid_MSG" SG_ 1504 CL1_LL_Dz 1000;
BA_ "GenSigTimeoutMsg_Hybrid_MSG" SG_ 1504 CL1_LL_Dz 1504;
BA_ "GenSigTimeoutTime_Otto" SG_ 1504 CL1_LL_Dz 1000;
BA_ "GenSigTimeoutMsg_Otto" SG_ 1504 CL1_LL_Dz 1504;
BA_ "GenSigTimeoutTime_Diesel" SG_ 1504 CL1_LL_Dz 1000;
BA_ "GenSigTimeoutMsg_Diesel" SG_ 1504 CL1_LL_Dz 1504;
BA_ "GenSigSendType" SG_ 1504 CL1_LL_Dz 0;
BA_ "GenSigTimeoutTime_Otto" SG_ 1504 CL1_AC_Schalter 1000;
BA_ "GenSigTimeoutMsg_Otto" SG_ 1504 CL1_AC_Schalter 1504;
BA_ "GenSigTimeoutTime_Diesel" SG_ 1504 CL1_AC_Schalter 1000;
BA_ "GenSigTimeoutMsg_Diesel" SG_ 1504 CL1_AC_Schalter 1504;
BA_ "GenSigSendType" SG_ 1504 CL1_AC_Schalter 0;
BA_ "GenSigSendType" SG_ 1504 CL1_Temp_Stoss 0;
BA_ "GenSigSendType" SG_ 1504 CL1_PTC_Hzg 0;
BA_ "GenSigTimeoutMsg_LWS" SG_ 1952 TPDyn_LWS 1952;
BA_ "GenSigTimeoutMsg_Hybrid_MSG" SG_ 1857 TPDyn_Motor_2 1857;
BA_ "GenSigTimeoutMsg_Otto" SG_ 1857 TPDyn_Motor_2 1857;
BA_ "GenSigTimeoutMsg_Diesel" SG_ 1857 TPDyn_Motor_2 1857;
BA_ "GenSigTimeoutMsg_Hybrid_MSG" SG_ 1856 TPDyn_Motor_1 1856;
BA_ "GenSigTimeoutMsg_Otto" SG_ 1856 TPDyn_Motor_1 1856;
BA_ "GenSigTimeoutMsg_Diesel" SG_ 1856 TPDyn_Motor_1 1856;
BA_ "GenSigTimeoutMsg_Hybrid_MSG" SG_ 1859 TPDyn_Motor_4 1859;
BA_ "GenSigTimeoutMsg_Otto" SG_ 1859 TPDyn_Motor_4 1859;
BA_ "GenSigTimeoutMsg_Diesel" SG_ 1859 TPDyn_Motor_4 1859;
BA_ "GenSigTimeoutMsg_SWA" SG_ 512 Tester_TP_Er 512;
BA_ "GenSigTimeoutMsg_Hybrid_DQ200" SG_ 512 Tester_TP_Er 512;
BA_ "GenSigTimeoutMsg_Hybrid_MSG" SG_ 512 Tester_TP_Er 512;
BA_ "GenSigTimeoutMsg_Daempfer" SG_ 512 Tester_TP_Er 512;
BA_ "GenSigTimeoutMsg_VAQ" SG_ 512 Tester_TP_Er 512;
BA_ "GenSigTimeoutMsg_Lenkhilfe_APA" SG_ 512 Tester_TP_Er 512;
BA_ "GenSigTimeoutMsg_PDC_PLA" SG_ 512 Tester_TP_Er 512;
BA_ "GenSigTimeoutMsg_Selespeed" SG_ 512 Tester_TP_Er 512;
BA_ "GenSigTimeoutMsg_RKA_Plus" SG_ 512 Tester_TP_Er 512;
BA_ "GenSigTimeoutMsg_Magne_Ride" SG_ 512 Tester_TP_Er 512;
BA_ "GenSigTimeoutMsg_AFS" SG_ 512 Tester_TP_Er 512;
BA_ "GenSigTimeoutMsg_ACC_Radar" SG_ 512 Tester_TP_Er 512;
BA_ "GenSigTimeoutMsg_TRW_ESP" SG_ 512 Tester_TP_Er 512;
BA_ "GenSigTimeoutMsg_EPB" SG_ 512 Tester_TP_Er 512;
BA_ "GenSigTimeoutMsg_DQ" SG_ 512 Tester_TP_Er 512;
BA_ "GenSigTimeoutMsg_Teves_MK70_MAB" SG_ 512 Tester_TP_Er 512;
BA_ "GenSigTimeoutMsg_LWR" SG_ 512 Tester_TP_Er 512;
BA_ "GenSigTimeoutMsg_LWS" SG_ 512 Tester_TP_Er 512;
BA_ "GenSigTimeoutMsg_Teves_MK60_ESP" SG_ 512 Tester_TP_Er 512;
BA_ "GenSigTimeoutMsg_Otto" SG_ 512 Tester_TP_Er 512;
BA_ "GenSigTimeoutMsg_Lenkhilfe_ZF_2" SG_ 512 Tester_TP_Er 512;
BA_ "GenSigTimeoutMsg_Diesel" SG_ 512 Tester_TP_Er 512;
BA_ "GenSigTimeoutMsg_Allrad" SG_ 512 Tester_TP_Er 512;
BA_ "GenSigTimeoutMsg_Airbag" SG_ 512 Tester_TP_Er 512;
BA_ "GenSigTimeoutMsg_AG6" SG_ 512 Tester_TP_Er 512;
BA_ "GenSigTimeoutMsg_Hybrid_MSG" SG_ 1858 TPDyn_Motor_3 1858;
BA_ "GenSigTimeoutMsg_Otto" SG_ 1858 TPDyn_Motor_3 1858;
BA_ "GenSigTimeoutMsg_Diesel" SG_ 1858 TPDyn_Motor_3 1858;
BA_ "GenSigTimeoutMsg_Allrad" SG_ 1893 TPDyn_Allrad_2 1893;
BA_ "GenSigTimeoutMsg_Daempfer" SG_ 1906 TPDyn_Daempfer_1 1906;
BA_ "GenSigTimeoutMsg_Magne_Ride" SG_ 1906 TPDyn_Daempfer_1 1906;
BA_ "GenSigTimeoutMsg_RKA_Plus" SG_ 1875 TPDyn_RKA_Plus_2 1875;
BA_ "GenSigTimeoutMsg_RKA_Plus" SG_ 1874 TPDyn_RKA_Plus_1 1874;
BA_ "GenSigTimeoutTime_SWA" SG_ 914 GK2_Sta_Lichtsensor 1000;
BA_ "GenSigTimeoutMsg_SWA" SG_ 914 GK2_Sta_Lichtsensor 914;
BA_ "GenSigTimeoutTime_AFS" SG_ 914 GK2_Sta_Lichtsensor 1000;
BA_ "GenSigTimeoutMsg_AFS" SG_ 914 GK2_Sta_Lichtsensor 914;
BA_ "GenSigSendType" SG_ 914 GK2_Sta_Lichtsensor 0;
BA_ "GenSigStartValue" SG_ 914 GK2_Sta_Lichtsensor 1;
BA_ "GenSigTimeoutTime_Otto" SG_ 914 GK2_Sta_Kessy_4 1000;
BA_ "GenSigTimeoutMsg_Otto" SG_ 914 GK2_Sta_Kessy_4 914;
BA_ "GenSigTimeoutTime_Diesel" SG_ 914 GK2_Sta_Kessy_4 1000;
BA_ "GenSigTimeoutMsg_Diesel" SG_ 914 GK2_Sta_Kessy_4 914;
BA_ "GenSigSendType" SG_ 914 GK2_Sta_Kessy_4 0;
BA_ "GenSigStartValue" SG_ 914 GK2_Sta_Kessy_4 1;
BA_ "GenSigSendType" SG_ 914 GK2_res_09 0;
BA_ "GenSigSendType" SG_ 914 GK2_Sta_LSM 0;
BA_ "GenSigStartValue" SG_ 914 GK2_Sta_LSM 1;
BA_ "GenSigTimeoutTime_SWA" SG_ 914 GK2_Helligkeit 1000;
BA_ "GenSigTimeoutMsg_SWA" SG_ 914 GK2_Helligkeit 914;
BA_ "GenSigTimeoutTime_AFS" SG_ 914 GK2_Helligkeit 1000;
BA_ "GenSigTimeoutMsg_AFS" SG_ 914 GK2_Helligkeit 914;
BA_ "GenSigSendType" SG_ 914 GK2_Helligkeit 0;
BA_ "GenSigTimeoutTime_Otto" SG_ 914 GK2_Sta_VSG 1000;
BA_ "GenSigTimeoutMsg_Otto" SG_ 914 GK2_Sta_VSG 914;
BA_ "GenSigTimeoutTime_PDC_PLA" SG_ 914 GK2_Sta_VSG 1000;
BA_ "GenSigTimeoutMsg_PDC_PLA" SG_ 914 GK2_Sta_VSG 914;
BA_ "GenSigTimeoutTime_Airbag" SG_ 914 GK2_Sta_VSG 1000;
BA_ "GenSigTimeoutMsg_Airbag" SG_ 914 GK2_Sta_VSG 914;
BA_ "GenSigSendType" SG_ 914 GK2_Sta_VSG 0;
BA_ "GenSigStartValue" SG_ 914 GK2_Sta_VSG 1;
BA_ "GenSigTimeoutTime_PDC_PLA" SG_ 914 GK2_Sta_Profil 1000;
BA_ "GenSigTimeoutMsg_PDC_PLA" SG_ 914 GK2_Sta_Profil 914;
BA_ "GenSigTimeoutTime_SWA" SG_ 914 GK2_Sta_Profil 1000;
BA_ "GenSigTimeoutMsg_SWA" SG_ 914 GK2_Sta_Profil 914;
BA_ "GenSigSendType" SG_ 914 GK2_Sta_Profil 0;
BA_ "GenSigStartValue" SG_ 914 GK2_Sta_Profil 1;
BA_ "GenSigTimeoutTime_Otto" SG_ 914 GK2_Sta_Clima2 1000;
BA_ "GenSigTimeoutMsg_Otto" SG_ 914 GK2_Sta_Clima2 914;
BA_ "GenSigTimeoutTime_Diesel" SG_ 914 GK2_Sta_Clima2 1000;
BA_ "GenSigTimeoutMsg_Diesel" SG_ 914 GK2_Sta_Clima2 914;
BA_ "GenSigSendType" SG_ 914 GK2_Sta_Clima2 0;
BA_ "GenSigStartValue" SG_ 914 GK2_Sta_Clima2 1;
BA_ "GenSigTimeoutTime_AFS" SG_ 914 GK2_Sta_Licht1 1000;
BA_ "GenSigTimeoutMsg_AFS" SG_ 914 GK2_Sta_Licht1 914;
BA_ "GenSigTimeoutTime_SWA" SG_ 914 GK2_Sta_Licht1 1000;
BA_ "GenSigTimeoutMsg_SWA" SG_ 914 GK2_Sta_Licht1 914;
BA_ "GenSigTimeoutTime_HCA" SG_ 914 GK2_Sta_Licht1 1000;
BA_ "GenSigTimeoutMsg_HCA" SG_ 914 GK2_Sta_Licht1 914;
BA_ "GenSigSendType" SG_ 914 GK2_Sta_Licht1 0;
BA_ "GenSigStartValue" SG_ 914 GK2_Sta_Licht1 1;
BA_ "GenSigSendType" SG_ 914 GK2_Feh_VLR 0;
BA_ "GenSigTimeoutTime_Otto" SG_ 914 GK2_Sta_BSG4 1000;
BA_ "GenSigTimeoutMsg_Otto" SG_ 914 GK2_Sta_BSG4 914;
BA_ "GenSigTimeoutTime_Diesel" SG_ 914 GK2_Sta_BSG4 1000;
BA_ "GenSigTimeoutMsg_Diesel" SG_ 914 GK2_Sta_BSG4 914;
BA_ "GenSigSendType" SG_ 914 GK2_Sta_BSG4 0;
BA_ "GenSigStartValue" SG_ 914 GK2_Sta_BSG4 1;
BA_ "GenSigTimeoutTime_SWA" SG_ 914 GK2_Blk_L_Kontrolle 1000;
BA_ "GenSigTimeoutMsg_SWA" SG_ 914 GK2_Blk_L_Kontrolle 914;
BA_ "GenSigTimeoutTime_HCA" SG_ 914 GK2_Blk_L_Kontrolle 1000;
BA_ "GenSigTimeoutMsg_HCA" SG_ 914 GK2_Blk_L_Kontrolle 914;
BA_ "GenSigSendType" SG_ 914 GK2_Blk_L_Kontrolle 0;
BA_ "GenSigTimeoutTime_EPB" SG_ 914 GK2_Sta_Schluessel 1000;
BA_ "GenSigTimeoutMsg_EPB" SG_ 914 GK2_Sta_Schluessel 914;
BA_ "GenSigTimeoutTime_Daempfer" SG_ 914 GK2_Sta_Schluessel 1000;
BA_ "GenSigTimeoutMsg_Daempfer" SG_ 914 GK2_Sta_Schluessel 914;
BA_ "GenSigTimeoutTime_TRW_ESP" SG_ 914 GK2_Sta_Schluessel 1000;
BA_ "GenSigTimeoutMsg_TRW_ESP" SG_ 914 GK2_Sta_Schluessel 914;
BA_ "GenSigSendType" SG_ 914 GK2_Sta_Schluessel 0;
BA_ "GenSigStartValue" SG_ 914 GK2_Sta_Schluessel 1;
BA_ "GenSigSendType" SG_ 914 GK2_res_13 0;
BA_ "GenSigTimeoutTime_AFS" SG_ 914 GK2_LS_KomFehler 1000;
BA_ "GenSigTimeoutMsg_AFS" SG_ 914 GK2_LS_KomFehler 914;
BA_ "GenSigSendType" SG_ 914 GK2_LS_KomFehler 0;
BA_ "GenSigTimeoutTime_PDC_PLA" SG_ 914 GK2_VD_zu_ver 1000;
BA_ "GenSigTimeoutMsg_PDC_PLA" SG_ 914 GK2_VD_zu_ver 914;
BA_ "GenSigSendType" SG_ 914 GK2_VD_zu_ver 0;
BA_ "GenSigTimeoutTime_SWA" SG_ 914 GK2_Blk_R_Kontrolle 1000;
BA_ "GenSigTimeoutMsg_SWA" SG_ 914 GK2_Blk_R_Kontrolle 914;
BA_ "GenSigTimeoutTime_HCA" SG_ 914 GK2_Blk_R_Kontrolle 1000;
BA_ "GenSigTimeoutMsg_HCA" SG_ 914 GK2_Blk_R_Kontrolle 914;
BA_ "GenSigSendType" SG_ 914 GK2_Blk_R_Kontrolle 0;
BA_ "GenSigTimeoutTime_Otto" SG_ 914 GK2_VD_offen_ver 1000;
BA_ "GenSigTimeoutMsg_Otto" SG_ 914 GK2_VD_offen_ver 914;
BA_ "GenSigTimeoutTime_PDC_PLA" SG_ 914 GK2_VD_offen_ver 1000;
BA_ "GenSigTimeoutMsg_PDC_PLA" SG_ 914 GK2_VD_offen_ver 914;
BA_ "GenSigTimeoutTime_Airbag" SG_ 914 GK2_VD_offen_ver 1000;
BA_ "GenSigTimeoutMsg_Airbag" SG_ 914 GK2_VD_offen_ver 914;
BA_ "GenSigSendType" SG_ 914 GK2_VD_offen_ver 0;
BA_ "GenSigTimeoutTime_AFS" SG_ 914 GK2_LS_def 1000;
BA_ "GenSigTimeoutMsg_AFS" SG_ 914 GK2_LS_def 914;
BA_ "GenSigSendType" SG_ 914 GK2_LS_def 0;
BA_ "GenSigTimeoutTime_PDC_PLA" SG_ 914 GK2_Verdeck_Anf 1000;
BA_ "GenSigTimeoutMsg_PDC_PLA" SG_ 914 GK2_Verdeck_Anf 914;
BA_ "GenSigSendType" SG_ 914 GK2_Verdeck_Anf 0;
BA_ "GenSigTimeoutTime_PDC_PLA" SG_ 914 GK2_VD_entriegelt 1000;
BA_ "GenSigTimeoutMsg_PDC_PLA" SG_ 914 GK2_VD_entriegelt 914;
BA_ "GenSigSendType" SG_ 914 GK2_VD_entriegelt 0;
BA_ "GenSigTimeoutTime_PDC_PLA" SG_ 914 GK2_VDKD_auf 1000;
BA_ "GenSigTimeoutMsg_PDC_PLA" SG_ 914 GK2_VDKD_auf 914;
BA_ "GenSigSendType" SG_ 914 GK2_VDKD_auf 0;
BA_ "GenSigTimeoutTime_Daempfer" SG_ 914 GK2_Schluessel 1000;
BA_ "GenSigTimeoutMsg_Daempfer" SG_ 914 GK2_Schluessel 914;
BA_ "GenSigSendType" SG_ 914 GK2_Schluessel 0;
BA_ "GenSigTimeoutTime_Otto" SG_ 914 GK2_EM_LIN_ungueltig 1000;
BA_ "GenSigTimeoutMsg_Otto" SG_ 914 GK2_EM_LIN_ungueltig 914;
BA_ "GenSigTimeoutTime_Diesel" SG_ 914 GK2_EM_LIN_ungueltig 1000;
BA_ "GenSigTimeoutMsg_Diesel" SG_ 914 GK2_EM_LIN_ungueltig 914;
BA_ "GenSigSendType" SG_ 914 GK2_EM_LIN_ungueltig 0;
BA_ "GenSigStartValue" SG_ 914 GK2_EM_LIN_ungueltig 1;
BA_ "GenSigTimeoutTime_AFS" SG_ 914 GK2_AFL_Schalter 1000;
BA_ "GenSigTimeoutMsg_AFS" SG_ 914 GK2_AFL_Schalter 914;
BA_ "GenSigSendType" SG_ 914 GK2_AFL_Schalter 0;
BA_ "GenSigTimeoutTime_PDC_PLA" SG_ 914 GK2_Hardtop 1000;
BA_ "GenSigTimeoutMsg_PDC_PLA" SG_ 914 GK2_Hardtop 914;
BA_ "GenSigSendType" SG_ 914 GK2_Hardtop 0;
BA_ "GenSigTimeoutTime_SWA" SG_ 914 GK2_Profil 1000;
BA_ "GenSigTimeoutMsg_SWA" SG_ 914 GK2_Profil 914;
BA_ "GenSigTimeoutTime_PDC_PLA" SG_ 914 GK2_Profil 1000;
BA_ "GenSigTimeoutMsg_PDC_PLA" SG_ 914 GK2_Profil 914;
BA_ "GenSigSendType" SG_ 914 GK2_Profil 0;
BA_ "GenSigTimeoutTime_Diesel" SG_ 914 GK2_Kl_StSt_Info 1000;
BA_ "GenSigTimeoutMsg_Diesel" SG_ 914 GK2_Kl_StSt_Info 914;
BA_ "GenSigTimeoutTime_Otto" SG_ 914 GK2_Kl_StSt_Info 1000;
BA_ "GenSigTimeoutMsg_Otto" SG_ 914 GK2_Kl_StSt_Info 914;
BA_ "GenSigSendType" SG_ 914 GK2_Kl_StSt_Info 0;
BA_ "GenSigTimeoutTime_Otto" SG_ 914 GK2_BEM_P_Generator 1000;
BA_ "GenSigTimeoutMsg_Otto" SG_ 914 GK2_BEM_P_Generator 914;
BA_ "GenSigTimeoutTime_Diesel" SG_ 914 GK2_BEM_P_Generator 1000;
BA_ "GenSigTimeoutMsg_Diesel" SG_ 914 GK2_BEM_P_Generator 914;
BA_ "GenSigSendType" SG_ 914 GK2_BEM_P_Generator 0;
BA_ "GenSigTimeoutTime_Otto" SG_ 914 GK2_BEM_Abschaltstufen 1000;
BA_ "GenSigTimeoutMsg_Otto" SG_ 914 GK2_BEM_Abschaltstufen 914;
BA_ "GenSigTimeoutTime_Diesel" SG_ 914 GK2_BEM_Abschaltstufen 1000;
BA_ "GenSigTimeoutMsg_Diesel" SG_ 914 GK2_BEM_Abschaltstufen 914;
BA_ "GenSigSendType" SG_ 914 GK2_BEM_Abschaltstufen 0;
BA_ "GenSigSendType" SG_ 914 GK2_res_60 0;
BA_ "GenSigTimeoutTime_AFS" SG_ 914 GK2_Nebelschluss 1000;
BA_ "GenSigTimeoutMsg_AFS" SG_ 914 GK2_Nebelschluss 914;
BA_ "GenSigSendType" SG_ 914 GK2_Nebelschluss 0;
BA_ "GenSigTimeoutTime_Diesel" SG_ 914 GK2_BSG_StSt_Info 1000;
BA_ "GenSigTimeoutMsg_Diesel" SG_ 914 GK2_BSG_StSt_Info 914;
BA_ "GenSigTimeoutTime_Otto" SG_ 914 GK2_BSG_StSt_Info 1000;
BA_ "GenSigTimeoutMsg_Otto" SG_ 914 GK2_BSG_StSt_Info 914;
BA_ "GenSigSendType" SG_ 914 GK2_BSG_StSt_Info 0;
BA_ "GenSigTimeoutTime_Otto" SG_ 914 GK2_BEM_DFM 1000;
BA_ "GenSigTimeoutMsg_Otto" SG_ 914 GK2_BEM_DFM 914;
BA_ "GenSigTimeoutTime_Diesel" SG_ 914 GK2_BEM_DFM 1000;
BA_ "GenSigTimeoutMsg_Diesel" SG_ 914 GK2_BEM_DFM 914;
BA_ "GenSigSendType" SG_ 914 GK2_BEM_DFM 0;
BA_ "GenSigTimeoutTime_Otto" SG_ 914 GK2_BEM_StSt_Info 1000;
BA_ "GenSigTimeoutMsg_Otto" SG_ 914 GK2_BEM_StSt_Info 914;
BA_ "GenSigTimeoutTime_Diesel" SG_ 914 GK2_BEM_StSt_Info 1000;
BA_ "GenSigTimeoutMsg_Diesel" SG_ 914 GK2_BEM_StSt_Info 914;
BA_ "GenSigSendType" SG_ 914 GK2_BEM_StSt_Info 0;
BA_ "GenSigTimeoutTime_Otto" SG_ 914 GK2_Kessy_StSt_Info 1000;
BA_ "GenSigTimeoutMsg_Otto" SG_ 914 GK2_Kessy_StSt_Info 914;
BA_ "GenSigTimeoutTime_Diesel" SG_ 914 GK2_Kessy_StSt_Info 1000;
BA_ "GenSigTimeoutMsg_Diesel" SG_ 914 GK2_Kessy_StSt_Info 914;
BA_ "GenSigSendType" SG_ 914 GK2_Kessy_StSt_Info 0;
BA_ "GenSigTimeoutMsg_PDC_PLA" SG_ 1978 TPDyn_PLA_PDC 1978;
BA_ "GenSigTimeoutMsg_TRW_ESP" SG_ 1940 TPDyn_EPB_1 1940;
BA_ "GenSigTimeoutMsg_EPB" SG_ 1940 TPDyn_EPB_1 1940;
BA_ "GenSigTimeoutMsg_VAQ" SG_ 1880 TPDyn_Quersperre_1 1880;
BA_ "GenSigTimeoutMsg_VAQ" SG_ 1881 TPDyn_Quersperre_2 1881;
BA_ "GenSigTimeoutTime_Teves_MK60_ESP" SG_ 919 ZK5_Endlage_ausgefahren 1000;
BA_ "GenSigTimeoutMsg_Teves_MK60_ESP" SG_ 919 ZK5_Endlage_ausgefahren 919;
BA_ "GenSigSendType" SG_ 919 ZK5_Endlage_ausgefahren 0;
BA_ "GenSigTimeoutTime_Teves_MK60_ESP" SG_ 919 ZK5_Status_Spoiler 1000;
BA_ "GenSigTimeoutMsg_Teves_MK60_ESP" SG_ 919 ZK5_Status_Spoiler 919;
BA_ "GenSigSendType" SG_ 919 ZK5_Status_Spoiler 0;
BA_ "GenSigTimeoutTime_Teves_MK60_ESP" SG_ 919 ZK5_Endlage_eingefahren 1000;
BA_ "GenSigTimeoutMsg_Teves_MK60_ESP" SG_ 919 ZK5_Endlage_eingefahren 919;
BA_ "GenSigSendType" SG_ 919 ZK5_Endlage_eingefahren 0;
BA_ "GenSigSendType" SG_ 919 ZK5_res_15 0;
BA_ "GenSigTimeoutTime_Teves_MK60_ESP" SG_ 919 ZK5_Zaehler 1000;
BA_ "GenSigTimeoutMsg_Teves_MK60_ESP" SG_ 919 ZK5_Zaehler 919;
BA_ "GenSigSendType" SG_ 919 ZK5_Zaehler 0;
BA_ "GenSigTimeoutTime_Teves_MK60_ESP" SG_ 919 ZK5_Checksumme 1000;
BA_ "GenSigTimeoutMsg_Teves_MK60_ESP" SG_ 919 ZK5_Checksumme 919;
BA_ "GenSigSendType" SG_ 919 ZK5_Checksumme 0;
BA_ "GenSigTimeoutTime_PDC_PLA" SG_ 919 ZK5_VD_Endlage_geschl 1000;
BA_ "GenSigTimeoutMsg_PDC_PLA" SG_ 919 ZK5_VD_Endlage_geschl 919;
BA_ "GenSigTimeoutTime_Teves_MK60_ESP" SG_ 919 ZK5_VD_Endlage_geschl 1000;
BA_ "GenSigTimeoutMsg_Teves_MK60_ESP" SG_ 919 ZK5_VD_Endlage_geschl 919;
BA_ "GenSigSendType" SG_ 919 ZK5_VD_Endlage_geschl 0;
BA_ "GenSigTimeoutTime_PDC_PLA" SG_ 919 ZK5_VD_Endlage_abgelegt 1000;
BA_ "GenSigTimeoutMsg_PDC_PLA" SG_ 919 ZK5_VD_Endlage_abgelegt 919;
BA_ "GenSigTimeoutTime_Teves_MK60_ESP" SG_ 919 ZK5_VD_Endlage_abgelegt 1000;
BA_ "GenSigTimeoutMsg_Teves_MK60_ESP" SG_ 919 ZK5_VD_Endlage_abgelegt 919;
BA_ "GenSigSendType" SG_ 919 ZK5_VD_Endlage_abgelegt 0;
BA_ "GenSigTimeoutTime_PDC_PLA" SG_ 919 ZK5_VD_Verbau 1000;
BA_ "GenSigTimeoutMsg_PDC_PLA" SG_ 919 ZK5_VD_Verbau 919;
BA_ "GenSigTimeoutTime_Teves_MK60_ESP" SG_ 919 ZK5_VD_Verbau 1000;
BA_ "GenSigTimeoutMsg_Teves_MK60_ESP" SG_ 919 ZK5_VD_Verbau 919;
BA_ "GenSigSendType" SG_ 919 ZK5_VD_Verbau 0;
BA_ "GenSigSendType" SG_ 919 ZK5_res_20 0;
BA_ "GenSigSendType" SG_ 919 ZK5_res_21 0;
BA_ "GenSigSendType" SG_ 919 ZK5_res_22 0;
BA_ "GenSigSendType" SG_ 919 ZK5_res_19 0;
BA_ "GenSigSendType" SG_ 919 ZK5_res_23 0;
BA_ "GenSigSendType" SG_ 919 ZK5_res_24 0;
BA_ "GenSigSendType" SG_ 919 ZK5_res_25 0;
BA_ "GenSigSendType" SG_ 919 ZK5_res_26 0;
BA_ "GenSigSendType" SG_ 919 ZK5_res_27 0;
BA_ "GenSigSendType" SG_ 919 ZK5_res_29 0;
BA_ "GenSigSendType" SG_ 919 ZK5_res_31 0;
BA_ "GenSigSendType" SG_ 919 ZK5_res_32 0;
BA_ "GenSigSendType" SG_ 919 ZK5_res_33 0;
BA_ "GenSigSendType" SG_ 919 ZK5_res_34 0;
BA_ "GenSigSendType" SG_ 919 ZK5_res_30 0;
BA_ "GenSigSendType" SG_ 919 ZK5_res_35 0;
BA_ "GenSigSendType" SG_ 919 ZK5_res_28 0;
BA_ "GenSigSendType" SG_ 919 ZK5_res_36 0;
BA_ "GenSigSendType" SG_ 919 ZK5_res_37 0;
BA_ "GenSigSendType" SG_ 919 ZK5_res_38 0;
BA_ "GenSigSendType" SG_ 919 ZK5_res_40 0;
BA_ "GenSigSendType" SG_ 919 ZK5_res_41 0;
BA_ "GenSigSendType" SG_ 919 ZK5_res_42 0;
BA_ "GenSigSendType" SG_ 919 ZK5_res_45 0;
BA_ "GenSigSendType" SG_ 919 ZK5_res_46 0;
BA_ "GenSigSendType" SG_ 919 ZK5_res_39 0;
BA_ "GenSigSendType" SG_ 919 ZK5_res_47 0;
BA_ "GenSigSendType" SG_ 919 ZK5_res_48 0;
BA_ "GenSigSendType" SG_ 919 ZK5_res_49 0;
BA_ "GenSigSendType" SG_ 919 ZK5_res_50 0;
BA_ "GenSigSendType" SG_ 919 ZK5_res_51 0;
BA_ "GenSigSendType" SG_ 919 ZK5_res_44 0;
BA_ "GenSigSendType" SG_ 919 ZK5_res_52 0;
BA_ "GenSigSendType" SG_ 919 ZK5_res_43 0;
BA_ "GenSigSendType" SG_ 919 ZK5_res_53 0;
BA_ "GenSigSendType" SG_ 919 ZK5_res_54 0;
BA_ "GenSigSendType" SG_ 919 ZK5_res_55 0;
BA_ "GenSigSendType" SG_ 919 ZK5_res_56 0;
BA_ "GenSigSendType" SG_ 919 ZK5_res_57 0;
BA_ "GenSigSendType" SG_ 919 ZK5_res_58 0;
BA_ "GenSigSendType" SG_ 919 ZK5_res_59 0;
BA_ "GenSigSendType" SG_ 919 ZK5_res_60 0;
BA_ "GenSigSendType" SG_ 919 ZK5_res_63 0;
BA_ "GenSigSendType" SG_ 919 ZK5_res_62 0;
BA_ "GenSigSendType" SG_ 919 ZK5_res_61 0;
BA_ "GenSigTimeoutMsg_Hybrid_MSG" SG_ 1658 BAP_Data_Anzeige_02 1658;
BA_ "GenSigTimeoutMsg_PDC_PLA" SG_ 1658 BAP_Data_Anzeige_02 1658;
BA_ "GenSigTimeoutMsg_PDC_PLA" SG_ 1530 Data_Byte_1_19 1530;
BA_ "GenSigSendType" SG_ 1530 Data_Byte_1_19 3;
BA_ "GenSigTimeoutMsg_PDC_PLA" SG_ 1530 Data_Byte_2_19 1530;
BA_ "GenSigSendType" SG_ 1530 Data_Byte_2_19 3;
BA_ "GenSigTimeoutMsg_PDC_PLA" SG_ 1530 Controller_ID_19 1530;
BA_ "GenSigSendType" SG_ 1530 Controller_ID_19 3;
BA_ "GenSigTimeoutMsg_PDC_PLA" SG_ 1530 Data_Byte_3_19 1530;
BA_ "GenSigSendType" SG_ 1530 Data_Byte_3_19 3;
BA_ "GenSigTimeoutMsg_PDC_PLA" SG_ 1530 Data_Byte_4_19 1530;
BA_ "GenSigSendType" SG_ 1530 Data_Byte_4_19 3;
BA_ "GenSigSendType" SG_ 1530 CDEF_AB_APS_res_19 3;
BA_ "GenSigTimeoutMsg_PDC_PLA" SG_ 1530 Module_ID_19 1530;
BA_ "GenSigSendType" SG_ 1530 Module_ID_19 3;
BA_ "GenSigTimeoutMsg_PDC_PLA" SG_ 1530 OpCode_19 1530;
BA_ "GenSigSendType" SG_ 1530 OpCode_19 3;
BA_ "GenSigTimeoutMsg_PDC_PLA" SG_ 1530 Update_Indikator_19 1530;
BA_ "GenSigSendType" SG_ 1530 Update_Indikator_19 3;
BA_ "GenSigTimeoutMsg_PDC_PLA" SG_ 1530 Funktions_ID_19 1530;
BA_ "GenSigSendType" SG_ 1530 Funktions_ID_19 3;
BA_ "GenSigTimeoutMsg_PDC_PLA" SG_ 1530 Data_Byte_5_19 1530;
BA_ "GenSigSendType" SG_ 1530 Data_Byte_5_19 3;
BA_ "GenSigTimeoutMsg_Otto" SG_ 2015 ISO_OBD_01_Req_Data 2015;
BA_ "GenSigTimeoutMsg_Diesel" SG_ 2015 ISO_OBD_01_Req_Data 2015;
BA_ "GenSigTimeoutMsg_DQ" SG_ 2015 ISO_OBD_01_Req_Data 2015;
BA_ "GenSigTimeoutMsg_AG6" SG_ 2015 ISO_OBD_01_Req_Data 2015;
BA_ "GenSigTimeoutMsg_Hybrid_BMS" SG_ 2015 ISO_OBD_01_Req_Data 2015;
BA_ "GenSigTimeoutMsg_Hybrid_MSG" SG_ 2015 ISO_OBD_01_Req_Data 2015;
BA_ "GenSigTimeoutMsg_Hybrid_PWR" SG_ 2015 ISO_OBD_01_Req_Data 2015;
BA_ "GenSigTimeoutMsg_Hybrid_DQ200" SG_ 2015 ISO_OBD_01_Req_Data 2015;
BA_ "GenSigTimeoutMsg_PDC_PLA" SG_ 1792 ISO_ALL_01_Req_Data 1792;
BA_ "GenSigTimeoutMsg_Lenkhilfe_ZF_3" SG_ 1792 ISO_ALL_01_Req_Data 1792;
BA_ "GenSigTimeoutMsg_ACC_Lidar" SG_ 1792 ISO_ALL_01_Req_Data 1792;
BA_ "GenSigTimeoutMsg_Airbag" SG_ 1792 ISO_ALL_01_Req_Data 1792;
BA_ "GenSigTimeoutMsg_Otto" SG_ 1792 ISO_ALL_01_Req_Data 1792;
BA_ "GenSigTimeoutMsg_AG6" SG_ 1792 ISO_ALL_01_Req_Data 1792;
BA_ "GenSigTimeoutMsg_Diesel" SG_ 1792 ISO_ALL_01_Req_Data 1792;
BA_ "GenSigTimeoutMsg_DQ" SG_ 1792 ISO_ALL_01_Req_Data 1792;
BA_ "GenSigTimeoutMsg_Hybrid_DQ200" SG_ 1792 ISO_ALL_01_Req_Data 1792;
BA_ "GenSigTimeoutMsg_Hybrid_MSG" SG_ 1792 ISO_ALL_01_Req_Data 1792;
BA_ "GenSigTimeoutMsg_Hybrid_PWR" SG_ 1792 ISO_ALL_01_Req_Data 1792;
BA_ "GenSigTimeoutMsg_Hybrid_BMS" SG_ 1792 ISO_ALL_01_Req_Data 1792;
BA_ "GenSigTimeoutMsg_EKlimakomp" SG_ 1792 ISO_ALL_01_Req_Data 1792;
BA_ "GenSigTimeoutMsg_DQ" SG_ 2017 ISO_Getriebe_01_Req_Data 2017;
BA_ "GenSigTimeoutMsg_AG6" SG_ 2017 ISO_Getriebe_01_Req_Data 2017;
BA_ "GenSigTimeoutMsg_Hybrid_DQ200" SG_ 2017 ISO_Getriebe_01_Req_Data 2017;
BA_ "GenSigTimeoutMsg_Otto" SG_ 2016 ISO_MO_01_Req_Data 2016;
BA_ "GenSigTimeoutMsg_Diesel" SG_ 2016 ISO_MO_01_Req_Data 2016;
BA_ "GenSigTimeoutMsg_Hybrid_MSG" SG_ 2016 ISO_MO_01_Req_Data 2016;
BA_ "GenSigTimeoutMsg_SWA" SG_ 1976 TPDyn_SWA_1 1976;
BA_ "GenSigTimeoutMsg_SWA" SG_ 1977 TPDyn_SWA_2 1977;
BA_ "GenSigTimeoutMsg_ACC_Lidar" SG_ 1654 BAP_Data_Anzeige 1654;
BA_ "GenSigTimeoutMsg_PDC_PLA" SG_ 1654 BAP_Data_Anzeige 1654;
BA_ "GenSigTimeoutMsg_ACC_Radar" SG_ 1654 BAP_Data_Anzeige 1654;
BA_ "GenSigTimeoutMsg_SWA" SG_ 1654 BAP_Data_Anzeige 1654;
BA_ "GenSigTimeoutMsg_HCA" SG_ 1654 BAP_Data_Anzeige 1654;
BA_ "GenSigTimeoutMsg_Lenkhilfe_ZF_3" SG_ 1810 ISO_Lenkhilfe_Req_Data 1810;
BA_ "GenSigTimeoutMsg_Airbag" SG_ 1813 ISO_Airbag_01_Req_Data 1813;
BA_ "GenSigTimeoutMsg_PDC_PLA" SG_ 1802 ISO_EPH_Req_Data 1802;
BA_ "GenSigTimeoutMsg_ACC_Lidar" SG_ 1879 ISO_ACC_Req_Data 1879;
BA_ "GenSigSendType" SG_ 1824 NMH_GW_Abschaltstufe_aktiv 0;
BA_ "GenSigSendType" SG_ 1824 NMH_GW_Car_WakeUp 0;
BA_ "GenSigSendType" SG_ 1824 NMH_GW_Eindraht_Fehler 0;
BA_ "GenSigSendType" SG_ 1824 NMH_GW_Fkt_WakeUp 0;
BA_ "GenSigSendType" SG_ 1824 NMH_GW_kein_NL 0;
BA_ "GenSigSendType" SG_ 1824 NMH_GW_KompSchutz 0;
BA_ "GenSigSendType" SG_ 1824 NMH_GW_Mute_Mode 0;
BA_ "GenSigSendType" SG_ 1824 NMH_GW_CAN_Diag_deaktiv 0;
BA_ "GenSigSendType" SG_ 1824 NMH_GW_NL_1 0;
BA_ "GenSigSendType" SG_ 1824 NMH_GW_NL_2 0;
BA_ "GenSigSendType" SG_ 1824 NMH_GW_NL_3 0;
BA_ "GenSigSendType" SG_ 1824 NMH_GW_NL_4 0;
BA_ "GenSigSendType" SG_ 1824 NMH_GW_NL_5 0;
BA_ "GenSigSendType" SG_ 1824 NMH_GW_NL_6 0;
BA_ "GenSigSendType" SG_ 1824 NMH_GW_NL_7 0;
BA_ "GenSigSendType" SG_ 1824 NMH_GW_NL_aktiv_5 0;
BA_ "GenSigSendType" SG_ 1824 NMH_GW_NL_aktiv_6 0;
BA_ "GenSigSendType" SG_ 1824 NMH_GW_NL_aktiv_7 0;
BA_ "GenSigSendType" SG_ 1824 NMH_GW_NL_aktiv_8 0;
BA_ "GenSigSendType" SG_ 1824 NMH_GW_NM_aktiv_Diagnose 0;
BA_ "GenSigSendType" SG_ 1824 NMH_GW_NM_aktiv_Klemme_15 0;
BA_ "GenSigSendType" SG_ 1824 NMH_GW_NL_aktiv_4 0;
BA_ "GenSigSendType" SG_ 1824 NMH_GW_NM_aktiv_Start 0;
BA_ "GenSigSendType" SG_ 1824 NMH_GW_Normal_Mode_1 0;
BA_ "GenSigSendType" SG_ 1824 NMH_GW_Normal_Mode_2 0;
BA_ "GenSigSendType" SG_ 1824 NMH_GW_Per_WakeUp 0;
BA_ "GenSigSendType" SG_ 1824 NMH_GW_res_04 0;
BA_ "GenSigSendType" SG_ 1824 NMH_GW_res_05 0;
BA_ "GenSigSendType" SG_ 1824 NMH_GW_res_32 0;
BA_ "GenSigSendType" SG_ 1824 NMH_GW_res_07 0;
BA_ "GenSigSendType" SG_ 1824 NMH_GW_res_41 0;
BA_ "GenSigSendType" SG_ 1824 NMH_GW_res_42 0;
BA_ "GenSigSendType" SG_ 1824 NMH_GW_res_43 0;
BA_ "GenSigSendType" SG_ 1824 NMH_GW_res_44 0;
BA_ "GenSigSendType" SG_ 1824 NMH_GW_res_45 0;
BA_ "GenSigSendType" SG_ 1824 NMH_GW_res_46 0;
BA_ "GenSigSendType" SG_ 1824 NMH_GW_res_40 0;
BA_ "GenSigSendType" SG_ 1824 NMH_GW_res_47 0;
BA_ "GenSigSendType" SG_ 1824 NMH_GW_res_48 0;
BA_ "GenSigSendType" SG_ 1824 NMH_GW_res_49 0;
BA_ "GenSigSendType" SG_ 1824 NMH_GW_res_50 0;
BA_ "GenSigSendType" SG_ 1824 NMH_GW_res_52 0;
BA_ "GenSigSendType" SG_ 1824 NMH_GW_res_53 0;
BA_ "GenSigSendType" SG_ 1824 NMH_GW_res_54 0;
BA_ "GenSigSendType" SG_ 1824 NMH_GW_res_55 0;
BA_ "GenSigTimeoutTime_TRW_ESP" SG_ 1824 NMH_GW_Start_1 2000;
BA_ "GenSigTimeoutMsg_TRW_ESP" SG_ 1824 NMH_GW_Start_1 1824;
BA_ "GenSigTimeoutTime_Teves_MK70_MAB" SG_ 1824 NMH_GW_Start_1 2000;
BA_ "GenSigTimeoutMsg_Teves_MK70_MAB" SG_ 1824 NMH_GW_Start_1 1824;
BA_ "GenSigTimeoutTime_Teves_MK60_ESP" SG_ 1824 NMH_GW_Start_1 2000;
BA_ "GenSigTimeoutMsg_Teves_MK60_ESP" SG_ 1824 NMH_GW_Start_1 1824;
BA_ "GenSigSendType" SG_ 1824 NMH_GW_Start_1 0;
BA_ "GenSigStartValue" SG_ 1824 NMH_GW_Start_1 1;
BA_ "GenSigSendType" SG_ 1824 NMH_GW_res_51 0;
BA_ "GenSigSendType" SG_ 1824 NMH_GW_Start_2 0;
BA_ "GenSigSendType" SG_ 1824 NMH_GW_TimeOut_Fehler 0;
BA_ "GenSigSendType" SG_ 1824 NMH_GW_Transport_Mode 0;
BA_ "GenSigTimeoutMsg_HCA" SG_ 1957 TPDyn_LDW_2 1957;
BA_ "GenSigTimeoutMsg_Airbag" SG_ 2033 Req_Airbag_Deployment 2033;
BA_ "GenSigSendType" SG_ 2033 Req_Airbag_Deployment 3;
BA_ "GenSigTimeoutTime_EKlimakomp" SG_ 1527 KE1_Comp_rev_rq 5000;
BA_ "GenSigTimeoutMsg_EKlimakomp" SG_ 1527 KE1_Comp_rev_rq 1527;
BA_ "GenSigSendType" SG_ 1527 KE1_Comp_rev_rq 0;
BA_ "GenSigTimeoutTime_EKlimakomp" SG_ 1527 KE1_Comp_enable 5000;
BA_ "GenSigTimeoutMsg_EKlimakomp" SG_ 1527 KE1_Comp_enable 1527;
BA_ "GenSigSendType" SG_ 1527 KE1_Comp_enable 0;
BA_ "GenSigSendType" SG_ 1527 KE1_res_01 0;
BA_ "GenSigSendType" SG_ 1527 KE1_res_16 0;
BA_ "GenSigSendType" SG_ 1527 KE1_res_03 0;
BA_ "GenSigTimeoutTime_Hybrid_BMS" SG_ 1527 KE1_Umluftstellung 5000;
BA_ "GenSigTimeoutMsg_Hybrid_BMS" SG_ 1527 KE1_Umluftstellung 1527;
BA_ "GenSigSendType" SG_ 1527 KE1_Umluftstellung 0;
BA_ "GenSigSendType" SG_ 1527 KE1_res_02 0;
BA_ "GenSigTimeoutTime_Diesel" SG_ 1392 BSL_ZAS_Kl_50 1000;
BA_ "GenSigTimeoutMsg_Diesel" SG_ 1392 BSL_ZAS_Kl_50 1392;
BA_ "GenSigTimeoutTime_Lenkhilfe_APA" SG_ 1392 BSL_ZAS_Kl_50 1000;
BA_ "GenSigTimeoutMsg_Lenkhilfe_APA" SG_ 1392 BSL_ZAS_Kl_50 1392;
BA_ "GenSigTimeoutTime_EPB" SG_ 1392 BSL_ZAS_Kl_50 1000;
BA_ "GenSigTimeoutMsg_EPB" SG_ 1392 BSL_ZAS_Kl_50 1392;
BA_ "GenSigTimeoutTime_Magne_Ride" SG_ 1392 BSL_ZAS_Kl_50 1000;
BA_ "GenSigTimeoutMsg_Magne_Ride" SG_ 1392 BSL_ZAS_Kl_50 1392;
BA_ "GenSigTimeoutTime_TRW_ESP" SG_ 1392 BSL_ZAS_Kl_50 1000;
BA_ "GenSigTimeoutMsg_TRW_ESP" SG_ 1392 BSL_ZAS_Kl_50 1392;
BA_ "GenSigSendType" SG_ 1392 BSL_ZAS_Kl_50 0;
BA_ "GenSigTimeoutTime_TRW_ESP" SG_ 1392 BSL_Kl_L 1000;
BA_ "GenSigTimeoutMsg_TRW_ESP" SG_ 1392 BSL_Kl_L 1392;
BA_ "GenSigSendType" SG_ 1392 BSL_Kl_L 0;
BA_ "GenSigTimeoutTime_FLA" SG_ 1392 BSL_ZAS_Kl_X 1000;
BA_ "GenSigTimeoutMsg_FLA" SG_ 1392 BSL_ZAS_Kl_X 1392;
BA_ "GenSigTimeoutTime_Diesel" SG_ 1392 BSL_ZAS_Kl_X 1000;
BA_ "GenSigTimeoutMsg_Diesel" SG_ 1392 BSL_ZAS_Kl_X 1392;
BA_ "GenSigTimeoutTime_HCA" SG_ 1392 BSL_ZAS_Kl_X 1000;
BA_ "GenSigTimeoutMsg_HCA" SG_ 1392 BSL_ZAS_Kl_X 1392;
BA_ "GenSigTimeoutTime_EPB" SG_ 1392 BSL_ZAS_Kl_X 1000;
BA_ "GenSigTimeoutMsg_EPB" SG_ 1392 BSL_ZAS_Kl_X 1392;
BA_ "GenSigTimeoutTime_TRW_ESP" SG_ 1392 BSL_ZAS_Kl_X 1000;
BA_ "GenSigTimeoutMsg_TRW_ESP" SG_ 1392 BSL_ZAS_Kl_X 1392;
BA_ "GenSigSendType" SG_ 1392 BSL_ZAS_Kl_X 0;
BA_ "GenSigTimeoutTime_FLA" SG_ 1392 BSL_ZAS_Kl_15 1000;
BA_ "GenSigTimeoutMsg_FLA" SG_ 1392 BSL_ZAS_Kl_15 1392;
BA_ "GenSigTimeoutTime_TRW_ESP" SG_ 1392 BSL_ZAS_Kl_15 1000;
BA_ "GenSigTimeoutMsg_TRW_ESP" SG_ 1392 BSL_ZAS_Kl_15 1392;
BA_ "GenSigTimeoutTime_EPB" SG_ 1392 BSL_ZAS_Kl_15 1000;
BA_ "GenSigTimeoutMsg_EPB" SG_ 1392 BSL_ZAS_Kl_15 1392;
BA_ "GenSigSendType" SG_ 1392 BSL_ZAS_Kl_15 0;
BA_ "GenSigTimeoutTime_TRW_ESP" SG_ 1392 BSL_Parklicht 1000;
BA_ "GenSigTimeoutMsg_TRW_ESP" SG_ 1392 BSL_Parklicht 1392;
BA_ "GenSigSendType" SG_ 1392 BSL_Parklicht 0;
BA_ "GenSigTimeoutTime_EPB" SG_ 1392 BSL_ZAS_Kl_S 1000;
BA_ "GenSigTimeoutMsg_EPB" SG_ 1392 BSL_ZAS_Kl_S 1392;
BA_ "GenSigTimeoutTime_TRW_ESP" SG_ 1392 BSL_ZAS_Kl_S 1000;
BA_ "GenSigTimeoutMsg_TRW_ESP" SG_ 1392 BSL_ZAS_Kl_S 1392;
BA_ "GenSigSendType" SG_ 1392 BSL_ZAS_Kl_S 0;
BA_ "GenSigTimeoutTime_Otto" SG_ 1392 BSL_Motor_Haube 1000;
BA_ "GenSigTimeoutMsg_Otto" SG_ 1392 BSL_Motor_Haube 1392;
BA_ "GenSigTimeoutTime_Diesel" SG_ 1392 BSL_Motor_Haube 1000;
BA_ "GenSigTimeoutMsg_Diesel" SG_ 1392 BSL_Motor_Haube 1392;
BA_ "GenSigTimeoutTime_Hybrid_MSG" SG_ 1392 BSL_Motor_Haube 1000;
BA_ "GenSigTimeoutMsg_Hybrid_MSG" SG_ 1392 BSL_Motor_Haube 1392;
BA_ "GenSigTimeoutTime_TRW_ESP" SG_ 1392 BSL_Motor_Haube 1000;
BA_ "GenSigTimeoutMsg_TRW_ESP" SG_ 1392 BSL_Motor_Haube 1392;
BA_ "GenSigSendType" SG_ 1392 BSL_Motor_Haube 0;
BA_ "GenSigTimeoutTime_TRW_ESP" SG_ 1392 BSL_Sta_UBat 1000;
BA_ "GenSigTimeoutMsg_TRW_ESP" SG_ 1392 BSL_Sta_UBat 1392;
BA_ "GenSigSendType" SG_ 1392 BSL_Sta_UBat 0;
BA_ "GenSigTimeoutTime_TRW_ESP" SG_ 1392 BSL_Fehlereintr 1000;
BA_ "GenSigTimeoutMsg_TRW_ESP" SG_ 1392 BSL_Fehlereintr 1392;
BA_ "GenSigSendType" SG_ 1392 BSL_Fehlereintr 0;
BA_ "GenSigTimeoutTime_Hybrid_MSG" SG_ 1392 BSL_LL_Anheb 1000;
BA_ "GenSigTimeoutMsg_Hybrid_MSG" SG_ 1392 BSL_LL_Anheb 1392;
BA_ "GenSigTimeoutTime_TRW_ESP" SG_ 1392 BSL_LL_Anheb 1000;
BA_ "GenSigTimeoutMsg_TRW_ESP" SG_ 1392 BSL_LL_Anheb 1392;
BA_ "GenSigTimeoutTime_Otto" SG_ 1392 BSL_LL_Anheb 1000;
BA_ "GenSigTimeoutMsg_Otto" SG_ 1392 BSL_LL_Anheb 1392;
BA_ "GenSigTimeoutTime_Diesel" SG_ 1392 BSL_LL_Anheb 1000;
BA_ "GenSigTimeoutMsg_Diesel" SG_ 1392 BSL_LL_Anheb 1392;
BA_ "GenSigSendType" SG_ 1392 BSL_LL_Anheb 0;
BA_ "GenSigTimeoutTime_TRW_ESP" SG_ 1392 BSL_Frontsch 1000;
BA_ "GenSigTimeoutMsg_TRW_ESP" SG_ 1392 BSL_Frontsch 1392;
BA_ "GenSigSendType" SG_ 1392 BSL_Frontsch 0;
BA_ "GenSigTimeoutTime_TRW_ESP" SG_ 1392 BSL_Sitzheiz 1000;
BA_ "GenSigTimeoutMsg_TRW_ESP" SG_ 1392 BSL_Sitzheiz 1392;
BA_ "GenSigSendType" SG_ 1392 BSL_Sitzheiz 0;
BA_ "GenSigTimeoutTime_TRW_ESP" SG_ 1392 BSL_Lenkradheiz 1000;
BA_ "GenSigTimeoutMsg_TRW_ESP" SG_ 1392 BSL_Lenkradheiz 1392;
BA_ "GenSigSendType" SG_ 1392 BSL_Lenkradheiz 0;
BA_ "GenSigTimeoutTime_TRW_ESP" SG_ 1392 BSL_Aussensp 1000;
BA_ "GenSigTimeoutMsg_TRW_ESP" SG_ 1392 BSL_Aussensp 1392;
BA_ "GenSigSendType" SG_ 1392 BSL_Aussensp 0;
BA_ "GenSigTimeoutTime_TRW_ESP" SG_ 1392 BSL_Sitzbelueft 1000;
BA_ "GenSigTimeoutMsg_TRW_ESP" SG_ 1392 BSL_Sitzbelueft 1392;
BA_ "GenSigSendType" SG_ 1392 BSL_Sitzbelueft 0;
BA_ "GenSigTimeoutTime_Hybrid_MSG" SG_ 1392 BSL_BSG_2_alt 1000;
BA_ "GenSigTimeoutMsg_Hybrid_MSG" SG_ 1392 BSL_BSG_2_alt 1392;
BA_ "GenSigTimeoutTime_TRW_ESP" SG_ 1392 BSL_BSG_2_alt 1000;
BA_ "GenSigTimeoutMsg_TRW_ESP" SG_ 1392 BSL_BSG_2_alt 1392;
BA_ "GenSigTimeoutTime_Otto" SG_ 1392 BSL_BSG_2_alt 1000;
BA_ "GenSigTimeoutMsg_Otto" SG_ 1392 BSL_BSG_2_alt 1392;
BA_ "GenSigTimeoutTime_Diesel" SG_ 1392 BSL_BSG_2_alt 1000;
BA_ "GenSigTimeoutMsg_Diesel" SG_ 1392 BSL_BSG_2_alt 1392;
BA_ "GenSigSendType" SG_ 1392 BSL_BSG_2_alt 0;
BA_ "GenSigStartValue" SG_ 1392 BSL_BSG_2_alt 1;
BA_ "GenSigTimeoutTime_TRW_ESP" SG_ 1392 BSL_Hecksch 1000;
BA_ "GenSigTimeoutMsg_TRW_ESP" SG_ 1392 BSL_Hecksch 1392;
BA_ "GenSigSendType" SG_ 1392 BSL_Hecksch 0;
BA_ "GenSigTimeoutTime_Hybrid_MSG" SG_ 1392 BSL_LL_Anheb2 1000;
BA_ "GenSigTimeoutMsg_Hybrid_MSG" SG_ 1392 BSL_LL_Anheb2 1392;
BA_ "GenSigTimeoutTime_TRW_ESP" SG_ 1392 BSL_LL_Anheb2 1000;
BA_ "GenSigTimeoutMsg_TRW_ESP" SG_ 1392 BSL_LL_Anheb2 1392;
BA_ "GenSigTimeoutTime_Otto" SG_ 1392 BSL_LL_Anheb2 1000;
BA_ "GenSigTimeoutMsg_Otto" SG_ 1392 BSL_LL_Anheb2 1392;
BA_ "GenSigTimeoutTime_Diesel" SG_ 1392 BSL_LL_Anheb2 1000;
BA_ "GenSigTimeoutMsg_Diesel" SG_ 1392 BSL_LL_Anheb2 1392;
BA_ "GenSigSendType" SG_ 1392 BSL_LL_Anheb2 0;
BA_ "GenSigTimeoutTime_Hybrid_MSG" SG_ 1392 BSL_Clima 1000;
BA_ "GenSigTimeoutMsg_Hybrid_MSG" SG_ 1392 BSL_Clima 1392;
BA_ "GenSigTimeoutTime_TRW_ESP" SG_ 1392 BSL_Clima 1000;
BA_ "GenSigTimeoutMsg_TRW_ESP" SG_ 1392 BSL_Clima 1392;
BA_ "GenSigTimeoutTime_Otto" SG_ 1392 BSL_Clima 1000;
BA_ "GenSigTimeoutMsg_Otto" SG_ 1392 BSL_Clima 1392;
BA_ "GenSigTimeoutTime_Diesel" SG_ 1392 BSL_Clima 1000;
BA_ "GenSigTimeoutMsg_Diesel" SG_ 1392 BSL_Clima 1392;
BA_ "GenSigSendType" SG_ 1392 BSL_Clima 0;
BA_ "GenSigTimeoutTime_Hybrid_MSG" SG_ 1392 BSL_Weckursache_ACAN 1000;
BA_ "GenSigTimeoutMsg_Hybrid_MSG" SG_ 1392 BSL_Weckursache_ACAN 1392;
BA_ "GenSigTimeoutTime_TRW_ESP" SG_ 1392 BSL_Weckursache_ACAN 1000;
BA_ "GenSigTimeoutMsg_TRW_ESP" SG_ 1392 BSL_Weckursache_ACAN 1392;
BA_ "GenSigTimeoutTime_Otto" SG_ 1392 BSL_Weckursache_ACAN 1000;
BA_ "GenSigTimeoutMsg_Otto" SG_ 1392 BSL_Weckursache_ACAN 1392;
BA_ "GenSigSendType" SG_ 1392 BSL_Weckursache_ACAN 0;
BA_ "GenSigTimeoutTime_FLA" SG_ 1392 BSL_BSG_3_alt 1000;
BA_ "GenSigTimeoutMsg_FLA" SG_ 1392 BSL_BSG_3_alt 1392;
BA_ "GenSigTimeoutTime_Lenkhilfe_APA" SG_ 1392 BSL_BSG_3_alt 1000;
BA_ "GenSigTimeoutMsg_Lenkhilfe_APA" SG_ 1392 BSL_BSG_3_alt 1392;
BA_ "GenSigTimeoutTime_HCA" SG_ 1392 BSL_BSG_3_alt 1000;
BA_ "GenSigTimeoutMsg_HCA" SG_ 1392 BSL_BSG_3_alt 1392;
BA_ "GenSigTimeoutTime_Hybrid_MSG" SG_ 1392 BSL_BSG_3_alt 1000;
BA_ "GenSigTimeoutMsg_Hybrid_MSG" SG_ 1392 BSL_BSG_3_alt 1392;
BA_ "GenSigTimeoutTime_TRW_ESP" SG_ 1392 BSL_BSG_3_alt 1000;
BA_ "GenSigTimeoutMsg_TRW_ESP" SG_ 1392 BSL_BSG_3_alt 1392;
BA_ "GenSigTimeoutTime_Otto" SG_ 1392 BSL_BSG_3_alt 1000;
BA_ "GenSigTimeoutMsg_Otto" SG_ 1392 BSL_BSG_3_alt 1392;
BA_ "GenSigTimeoutTime_Diesel" SG_ 1392 BSL_BSG_3_alt 1000;
BA_ "GenSigTimeoutMsg_Diesel" SG_ 1392 BSL_BSG_3_alt 1392;
BA_ "GenSigSendType" SG_ 1392 BSL_BSG_3_alt 0;
BA_ "GenSigStartValue" SG_ 1392 BSL_BSG_3_alt 1;
BA_ "GenSigTimeoutTime_TRW_ESP" SG_ 1392 BSL_Kl_15_Motor 1000;
BA_ "GenSigTimeoutMsg_TRW_ESP" SG_ 1392 BSL_Kl_15_Motor 1392;
BA_ "GenSigSendType" SG_ 1392 BSL_Kl_15_Motor 0;
BA_ "GenSigTimeoutTime_TRW_ESP" SG_ 1392 BSL_UBat 1000;
BA_ "GenSigTimeoutMsg_TRW_ESP" SG_ 1392 BSL_UBat 1392;
BA_ "GenSigSendType" SG_ 1392 BSL_UBat 0;
BA_ "GenSigTimeoutTime_Lenkhilfe_ZF_3" SG_ 1392 BSL_Kuehlerlueft 1000;
BA_ "GenSigTimeoutMsg_Lenkhilfe_ZF_3" SG_ 1392 BSL_Kuehlerlueft 1392;
BA_ "GenSigTimeoutTime_Hybrid_MSG" SG_ 1392 BSL_Kuehlerlueft 1000;
BA_ "GenSigTimeoutMsg_Hybrid_MSG" SG_ 1392 BSL_Kuehlerlueft 1392;
BA_ "GenSigTimeoutTime_TRW_ESP" SG_ 1392 BSL_Kuehlerlueft 1000;
BA_ "GenSigTimeoutMsg_TRW_ESP" SG_ 1392 BSL_Kuehlerlueft 1392;
BA_ "GenSigTimeoutTime_Otto" SG_ 1392 BSL_Kuehlerlueft 1000;
BA_ "GenSigTimeoutMsg_Otto" SG_ 1392 BSL_Kuehlerlueft 1392;
BA_ "GenSigTimeoutTime_Lenkhilfe_ZF_2" SG_ 1392 BSL_Kuehlerlueft 1000;
BA_ "GenSigTimeoutMsg_Lenkhilfe_ZF_2" SG_ 1392 BSL_Kuehlerlueft 1392;
BA_ "GenSigTimeoutTime_Diesel" SG_ 1392 BSL_Kuehlerlueft 1000;
BA_ "GenSigTimeoutMsg_Diesel" SG_ 1392 BSL_Kuehlerlueft 1392;
BA_ "GenSigSendType" SG_ 1392 BSL_Kuehlerlueft 0;
BA_ "GenSigTimeoutTime_TRW_ESP" SG_ 1392 BSL_Sta_LWR 1000;
BA_ "GenSigTimeoutMsg_TRW_ESP" SG_ 1392 BSL_Sta_LWR 1392;
BA_ "GenSigSendType" SG_ 1392 BSL_Sta_LWR 0;
BA_ "GenSigTimeoutTime_TRW_ESP" SG_ 1392 BSL_Sta_StBat 1000;
BA_ "GenSigTimeoutMsg_TRW_ESP" SG_ 1392 BSL_Sta_StBat 1392;
BA_ "GenSigSendType" SG_ 1392 BSL_Sta_StBat 0;
BA_ "GenSigTimeoutTime_Lenkhilfe_ZF_3" SG_ 1392 BSL_Ab_Batterie 1000;
BA_ "GenSigTimeoutMsg_Lenkhilfe_ZF_3" SG_ 1392 BSL_Ab_Batterie 1392;
BA_ "GenSigTimeoutTime_Hybrid_MSG" SG_ 1392 BSL_Ab_Batterie 1000;
BA_ "GenSigTimeoutMsg_Hybrid_MSG" SG_ 1392 BSL_Ab_Batterie 1392;
BA_ "GenSigTimeoutTime_Lenkhilfe_APA" SG_ 1392 BSL_Ab_Batterie 1000;
BA_ "GenSigTimeoutMsg_Lenkhilfe_APA" SG_ 1392 BSL_Ab_Batterie 1392;
BA_ "GenSigTimeoutTime_TRW_ESP" SG_ 1392 BSL_Ab_Batterie 1000;
BA_ "GenSigTimeoutMsg_TRW_ESP" SG_ 1392 BSL_Ab_Batterie 1392;
BA_ "GenSigTimeoutTime_Otto" SG_ 1392 BSL_Ab_Batterie 1000;
BA_ "GenSigTimeoutMsg_Otto" SG_ 1392 BSL_Ab_Batterie 1392;
BA_ "GenSigTimeoutTime_Lenkhilfe_ZF_2" SG_ 1392 BSL_Ab_Batterie 1000;
BA_ "GenSigTimeoutMsg_Lenkhilfe_ZF_2" SG_ 1392 BSL_Ab_Batterie 1392;
BA_ "GenSigTimeoutTime_Diesel" SG_ 1392 BSL_Ab_Batterie 1000;
BA_ "GenSigTimeoutMsg_Diesel" SG_ 1392 BSL_Ab_Batterie 1392;
BA_ "GenSigSendType" SG_ 1392 BSL_Ab_Batterie 0;
BA_ "GenSigTimeoutTime_TRW_ESP" SG_ 1392 BSL_Wasserheiz 1000;
BA_ "GenSigTimeoutMsg_TRW_ESP" SG_ 1392 BSL_Wasserheiz 1392;
BA_ "GenSigSendType" SG_ 1392 BSL_Wasserheiz 0;
BA_ "GenSigTimeoutTime_Hybrid_MSG" SG_ 1392 BSL_Wake_Up_ACAN 1000;
BA_ "GenSigTimeoutMsg_Hybrid_MSG" SG_ 1392 BSL_Wake_Up_ACAN 1392;
BA_ "GenSigTimeoutTime_TRW_ESP" SG_ 1392 BSL_Wake_Up_ACAN 1000;
BA_ "GenSigTimeoutMsg_TRW_ESP" SG_ 1392 BSL_Wake_Up_ACAN 1392;
BA_ "GenSigTimeoutTime_Otto" SG_ 1392 BSL_Wake_Up_ACAN 1000;
BA_ "GenSigTimeoutMsg_Otto" SG_ 1392 BSL_Wake_Up_ACAN 1392;
BA_ "GenSigSendType" SG_ 1392 BSL_Wake_Up_ACAN 0;
BA_ "GenSigTimeoutTime_TRW_ESP" SG_ 1392 BSL_Starterlaubnis 1000;
BA_ "GenSigTimeoutMsg_TRW_ESP" SG_ 1392 BSL_Starterlaubnis 1392;
BA_ "GenSigSendType" SG_ 1392 BSL_Starterlaubnis 3;
BA_ "GenSigTimeoutTime_Selespeed" SG_ 1394 ZA1_S_Kontakt 1000;
BA_ "GenSigTimeoutMsg_Selespeed" SG_ 1394 ZA1_S_Kontakt 1394;
BA_ "GenSigTimeoutTime_Diesel" SG_ 1394 ZA1_S_Kontakt 1000;
BA_ "GenSigTimeoutMsg_Diesel" SG_ 1394 ZA1_S_Kontakt 1394;
BA_ "GenSigSendType" SG_ 1394 ZA1_S_Kontakt 3;
BA_ "GenSigTimeoutTime_Hybrid_MSG" SG_ 1394 ZA1_Klemme_15 1000;
BA_ "GenSigTimeoutMsg_Hybrid_MSG" SG_ 1394 ZA1_Klemme_15 1394;
BA_ "GenSigTimeoutTime_PDC_PLA" SG_ 1394 ZA1_Klemme_15 1000;
BA_ "GenSigTimeoutMsg_PDC_PLA" SG_ 1394 ZA1_Klemme_15 1394;
BA_ "GenSigTimeoutTime_Otto" SG_ 1394 ZA1_Klemme_15 1000;
BA_ "GenSigTimeoutMsg_Otto" SG_ 1394 ZA1_Klemme_15 1394;
BA_ "GenSigTimeoutTime_Diesel" SG_ 1394 ZA1_Klemme_15 1000;
BA_ "GenSigTimeoutMsg_Diesel" SG_ 1394 ZA1_Klemme_15 1394;
BA_ "GenSigSendType" SG_ 1394 ZA1_Klemme_15 3;
BA_ "GenSigTimeoutTime_Diesel" SG_ 1394 ZA1_Klemme_P 1000;
BA_ "GenSigTimeoutMsg_Diesel" SG_ 1394 ZA1_Klemme_P 1394;
BA_ "GenSigSendType" SG_ 1394 ZA1_Klemme_P 3;
BA_ "GenSigTimeoutTime_PDC_PLA" SG_ 1394 ZA1_Klemme_X 1000;
BA_ "GenSigTimeoutMsg_PDC_PLA" SG_ 1394 ZA1_Klemme_X 1394;
BA_ "GenSigTimeoutTime_AFS" SG_ 1394 ZA1_Klemme_X 1000;
BA_ "GenSigTimeoutMsg_AFS" SG_ 1394 ZA1_Klemme_X 1394;
BA_ "GenSigTimeoutTime_Diesel" SG_ 1394 ZA1_Klemme_X 1000;
BA_ "GenSigTimeoutMsg_Diesel" SG_ 1394 ZA1_Klemme_X 1394;
BA_ "GenSigSendType" SG_ 1394 ZA1_Klemme_X 3;
BA_ "GenSigTimeoutTime_Selespeed" SG_ 1394 ZA1_Klemme_50 1000;
BA_ "GenSigTimeoutMsg_Selespeed" SG_ 1394 ZA1_Klemme_50 1394;
BA_ "GenSigTimeoutTime_Hybrid_MSG" SG_ 1394 ZA1_Klemme_50 1000;
BA_ "GenSigTimeoutMsg_Hybrid_MSG" SG_ 1394 ZA1_Klemme_50 1394;
BA_ "GenSigTimeoutTime_AFS" SG_ 1394 ZA1_Klemme_50 1000;
BA_ "GenSigTimeoutMsg_AFS" SG_ 1394 ZA1_Klemme_50 1394;
BA_ "GenSigTimeoutTime_Otto" SG_ 1394 ZA1_Klemme_50 1000;
BA_ "GenSigTimeoutMsg_Otto" SG_ 1394 ZA1_Klemme_50 1394;
BA_ "GenSigTimeoutTime_Diesel" SG_ 1394 ZA1_Klemme_50 1000;
BA_ "GenSigTimeoutMsg_Diesel" SG_ 1394 ZA1_Klemme_50 1394;
BA_ "GenSigSendType" SG_ 1394 ZA1_Klemme_50 3;
BA_ "GenSigSendType" SG_ 1394 ZA1_Klemme_SV 3;
BA_ "GenSigSendType" SG_ 1394 ZA1_Reserve3 3;
BA_ "GenSigSendType" SG_ 1394 ZA1_Reserve1 3;
BA_ "GenSigSendType" SG_ 1394 ZA1_Zaehler 3;
BA_ "GenSigSendType" SG_ 1394 ZA1_Checksumme 3;
BA_ "INIT" SG_ 1394 ZA1_Checksumme "CHK";
BA_ "GenSigSendType" SG_ 1394 ZA1_Fehlereintr 3;
BA_ "GenSigSendType" SG_ 1394 ZA1_res07 3;
BA_ "GenSigSendType" SG_ 1394 ZA1_Reserve4 3;
BA_ "GenSigTimeoutMsg_ACC_Radar" SG_ 1904 TPDyn_ADR_1 1904;
BA_ "GenSigTimeoutMsg_FLA" SG_ 1864 TPDyn_FLA_1 1864;
BA_ "NWM-WakeUpAllowed" SG_ 1982 ISO_LWRAFS_Resp_Data 1;
BA_ "NWM-WakeUpAllowed" SG_ 1917 ISO_ABS_Resp_Data 1;
BA_ "NWM-WakeUpAllowed" SG_ 2027 ISO_OBD_reserv1_Resp_Data 1;
BA_ "NWM-WakeUpAllowed" SG_ 2028 ISO_OBD_reserv2_Resp_Data 1;
BA_ "NWM-WakeUpAllowed" SG_ 2030 ISO_OBD_DMCM_Resp_Data 1;
BA_ "NWM-WakeUpAllowed" SG_ 2031 ISO_OBD_reserv5_Resp_Data 1;
BA_ "NWM-WakeUpAllowed" SG_ 2029 ISO_OBD_BECM_Resp_Data 1;
BA_ "NWM-WakeUpAllowed" SG_ 2026 ISO_MOS_01_Resp_Data 1;
BA_ "NWM-WakeUpAllowed" SG_ 1817 ISO_EKomp_Req_Data 1;
VAL_ 1488 SY1_Diag_Ant 1 "CAN_Antrieb_in_Diagnose" 0 "zZt_keine_Antrieb_Diagnose" ;
VAL_ 1488 SY1_CAN_extern 1 "CANextern_zugeschaltet" 0 "CANextern_getrennt" ;
VAL_ 1488 SY1_Diag_Komf 1 "Diagnoseanf_im_CAN_Komf_erkannt" 0 "zZt_keine_Komfort_Diagnose" ;
VAL_ 1488 SY1_Sleep_Info 1 "Busruhe" 0 "keine_Busruhe" ;
VAL_ 1488 SY1_Sleep_Komf 1 "Busruhe" 0 "keine_Busruhe" ;
VAL_ 1488 SY1_CAN_Info 1 "verbaut" 0 "nicht_verbaut" ;
VAL_ 1488 SY1_Diag_Info 1 "Diagnoseanf_im_CAN_Infot_erkannt" 0 "zZt_keine_Infotainement_Diagnose" ;
VAL_ 1488 SY1_Verbauinfo 1 "gueltig" 0 "ungueltig" ;
VAL_ 1488 SY1_Fzg_Marke 15 "Porsche" 14 "Ford" 8 "RollsRoyce" 7 "Bentley" 6 "Lamborghini" 5 "Bugatti" 4 "VN_VWNutzfzg" 3 "SK_Skoda" 2 "SE_Seat" 1 "AU_Audi" 0 "VW_Volkswagen" ;
VAL_ 1488 SY1_Fzg_Klasse 9 "L_Klasse" 8 "LT_Klasse" 7 "T_Klasse" 6 "D_Klasse" 5 "C_Klasse" 4 "B_Klasse" 3 "A_Klasse" 2 "A0_Klasse" 1 "A00_Klasse" 0 "A000_Klasse" ;
VAL_ 1488 SY1_Fzg_Index 15 "nicht_bekannt" 9 "Sonstige" 8 "Hochdach" 7 "Flachdach" 6 "geschlossene_Aufbauten" 5 "offene_Aufbauten" 4 "Hochmotorisierung" 3 "Syncro" 2 "geaenderte_Front_Heck" 1 "langer_Radstand" 0 "kurzer_Radstand" ;
VAL_ 1488 SY1_Tueren 1 "Vier_Tueren_oder_mehr" 0 "Kleiner_vier_Tueren" ;
VAL_ 1488 SY1_Fzg_Derivat 15 "nicht_bekannt" 9 "Sonstige" 8 "MPV" 7 "CityVan_PickUp" 6 "Offroad" 5 "Cabrio_Roadstar_Spider" 4 "Coupe_Sportwagen" 3 "Fliessheck" 2 "Variant" 1 "Stufenheck_Nutz" 0 "Kurzheck_Multivan" ;
VAL_ 1488 SY1_Lenker 1 "Rechtslenker" 0 "Linkslenker" ;
VAL_ 1488 SY1_Fehlereintr 1 "Fehlereintrag" 0 "kein_Fehlereintrag" ;
VAL_ 1488 SY1_Transportmode 1 "aktiv" 0 "nicht_aktiv" ;
VAL_ 1488 SY1_Notbrems_Status 1 "Notbremssituation" 0 "keine_Notbremsung" ;
VAL_ 1488 SY1_ELV_Lock_Supply 1 "Freigabe" 0 "keine_Freigabe" ;
VAL_ 1488 SY1_Relais_FAS_Zweig 3 "reserviert" 2 "Relais_im_Fehlerfall_geoeffnet" 1 "Relais_planmaessig_geoeffnet" 0 "Relais_geschlossen" ;
VAL_ 1488 SY1_QRS_Messmodus 1 "QRS_ein" 0 "QRS_aus" ;
VAL_ 1488 SY1_NWDF_gueltig 1 "NWDF_Fkt_unterstuetzt" 0 "NWDF_Fkt_nicht_unterstuetzt" ;
VAL_ 1488 SY1_NWDF 1 "Ueberwachung_freigegeben" 0 "Ueberwachung_nicht_freigegeben" ;
VAL_ 2000 DI1_Minute 63 "ungueltig" 62 "ungueltig" 61 "ungueltig" 60 "ungueltig" ;
VAL_ 2000 DI1_Monat 15 "Spezialfall" 14 "relatives_Datum" 13 "ungueltig" 0 "ungueltig" ;
VAL_ 2000 DI1_Sekunde 63 "ungueltig" 62 "ungueltig" 61 "ungueltig" 60 "ungueltig" ;
VAL_ 2000 DI1_Stunde 31 "ungueltig" 30 "ungueltig" 29 "ungueltig" 28 "ungueltig" 27 "ungueltig" 26 "ungueltig" 25 "ungueltig" 24 "ungueltig" ;
VAL_ 2000 DI1_KM_Stand_alt 1 "veraltet" 0 "aktuell" ;
VAL_ 2000 DI1_Zeit_alt 1 "veraltet" 0 "aktuell" ;
VAL_ 2000 DI1_VerlernZaehl 255 "Fehler" ;
VAL_ 1500 VL1_Getr_SG 1 "Sollverbau" ;
VAL_ 1500 VL1_Airbag 1 "Sollverbau" ;
VAL_ 1500 VL1_Motor_SG 1 "Sollverbau" ;
VAL_ 1500 VL1_ABS 1 "Sollverbau" ;
VAL_ 1500 VL1_res_08 1 "Sollverbau" ;
VAL_ 1500 VL1_EPB 1 "Sollverbau" ;
VAL_ 1500 VL1_Kombi 1 "Sollverbau" ;
VAL_ 1500 VL1_Allrad 1 "Sollverbau" ;
VAL_ 1500 VL1_LSM 1 "Sollverbau" ;
VAL_ 1500 VL1_Lenkhilfe 1 "Sollverbau" ;
VAL_ 1500 VL1_ADR 1 "Sollverbau" ;
VAL_ 1500 VL1_Daempfer 1 "Sollverbau" ;
VAL_ 1500 VL1_dyn_LWR 1 "Sollverbau" ;
VAL_ 1500 VL1_DAB 1 "Sollverbau" ;
VAL_ 1500 VL1_MotorSlave 1 "Sollverbau" ;
VAL_ 1500 VL1_TSG_BT 1 "Sollverbau" ;
VAL_ 1500 VL1_TSG_FT 1 "Sollverbau" ;
VAL_ 1500 VL1_TSG_HL 1 "Sollverbau" ;
VAL_ 1500 VL1_ZKE 1 "Sollverbau" ;
VAL_ 1500 VL1_BSG_Komf 1 "Sollverbau" ;
VAL_ 1500 VL1_Memory 1 "Sollverbau" ;
VAL_ 1500 VL1_Dachmodul_K 1 "Sollverbau" ;
VAL_ 1500 VL1_TSG_HR 1 "Sollverbau" ;
VAL_ 1500 VL1_Zentralelektrik_II 1 "Sollverbau" ;
VAL_ 1500 VL1_Lenksaeule 1 "Sollverbau" ;
VAL_ 1500 VL1_Einparkhilfe 1 "Sollverbau" ;
VAL_ 1500 VL1_Gateway 1 "Sollverbau" ;
VAL_ 1500 VL1_RDK 1 "Sollverbau" ;
VAL_ 1500 VL1_PTC_Heizung 1 "Sollverbau" ;
VAL_ 1500 VL1_Standheiz 1 "Sollverbau" ;
VAL_ 1500 VL1_Clima_Komf 1 "Sollverbau" ;
VAL_ 1500 VL1_res_42 1 "Sollverbau" ;
VAL_ 1500 VL1_RSE_I 1 "Sollverbau" ;
VAL_ 1500 VL1_Verdeck 1 "Sollverbau" ;
VAL_ 1500 VL1_MDI_I 1 "Sollverbau" ;
VAL_ 1500 VL1_Memory_BF 1 "Sollverbau" ;
VAL_ 1500 VL1_Heckdeckel 1 "Sollverbau" ;
VAL_ 1500 VL1_Anhaenger 1 "Sollverbau" ;
VAL_ 1500 VL1_Easy_Entry_VF 1 "Sollverbau" ;
VAL_ 1500 VL1_Sonderfzg_SG 1 "Sollverbau" ;
VAL_ 1500 VL1_Tastenmodul 1 "Sollverbau" ;
VAL_ 1500 VL1_Radio 1 "Sollverbau" ;
VAL_ 1500 VL1_Telefon 1 "Sollverbau" ;
VAL_ 1500 VL1_Navigation 1 "Sollverbau" ;
VAL_ 1500 VL1_Neigungsmodul_I 1 "Sollverbau" ;
VAL_ 1500 VL1_ADR_getrennt 1 "getrennt" 0 "geschlossen" ;
VAL_ 1500 VL1_DSP 1 "Sollverbau" ;
VAL_ 1500 VL1_Easy_Entry_VB 1 "Sollverbau" ;
VAL_ 1500 VL1_Telematik 1 "Sollverbau" ;
VAL_ 1500 VL1_TV_Tuner 1 "Sollverbau" ;
VAL_ 1500 VL1_WFS_K 1 "Sollverbau" ;
VAL_ 1500 VL1_Kompass 1 "Sollverbau" ;
VAL_ 1500 VL1_Rearview 1 "Sollverbau" ;
VAL_ 1500 VL1_GSM_Pager 1 "Sollverbau" ;
VAL_ 1500 VL1_InfoElektronik 1 "Sollverbau" ;
VAL_ 1500 VL1_Kombi_KBI 1 "Sollverbau" ;
VAL_ 1500 VL1_Soll_eq_Ist 1 "gleich" 0 "ungleich" ;
VAL_ 1500 VL1_Quersperre 1 "Sollverbau" ;
VAL_ 1500 VL1_SWA 1 "Sollverbau" ;
VAL_ 1500 VL1_PLA 1 "Sollverbau" ;
VAL_ 1500 VL1_HCA 1 "Sollverbau" ;
VAL_ 1500 VL1_WFS_KBI 1 "Sollverbau" ;
VAL_ 1500 VL1_RKA_Plus 1 "Sollverbau" ;
VAL_ 1504 CL1_Hecksch 1 "ein" 0 "aus" ;
VAL_ 1504 CL1_Heizleist 1 "keine_Heizleistung" 0 "Heizleistung" ;
VAL_ 1504 CL1_Fa_Zuheiz 1 "ein" 0 "aus" ;
VAL_ 1504 CL1_Kompressor 1 "ein" 0 "aus" ;
VAL_ 1504 CL1_Sta_Druck 1 "veraltet" 0 "aktuell" ;
VAL_ 1504 CL1_Frontsch 1 "ein" 0 "aus" ;
VAL_ 1504 CL1_Sta_Moment 1 "veraltet" 0 "aktuell" ;
VAL_ 1504 CL1_Kompr_Last 255 "Fehler" ;
VAL_ 1504 CL1_Druck 255 "Fehler" ;
VAL_ 1504 CL1_Aussentemp 255 "Fehler" ;
VAL_ 1504 CL1_Gebl_last 255 "Fehler" ;
VAL_ 1504 CL1_Einheit_Temp 1 "Fahrenheit" 0 "Grad_Celsius" ;
VAL_ 1504 CL1_Luefter 255 "Fehler" 0 "keine_Anforderung" ;
VAL_ 1504 CL1_Fehlereintr 1 "Fehlerspeichereintrag" 0 "kein_Fehlerspeichereintrag" ;
VAL_ 1504 CL1_WAPU_Zuschaltung 1 "WAPU_AUS" 0 "WAPU_EIN" ;
VAL_ 1504 CL1_Restwaerme 1 "aktiviert" 0 "nicht_aktiviert" ;
VAL_ 1504 CL1_LL_Dz 1 "Anhebung" 0 "keine_Anhebung" ;
VAL_ 1504 CL1_AC_Schalter 1 "ein_gedrueckt_oder_an" 0 "aus" ;
VAL_ 1504 CL1_Temp_Stoss 255 "Fehler" ;
VAL_ 914 GK2_Sta_Lichtsensor 1 "veraltet" 0 "aktuell_empfangen" ;
VAL_ 914 GK2_Sta_Kessy_4 1 "veraltet" 0 "aktuell_empfangen" ;
VAL_ 914 GK2_Sta_LSM 1 "veraltet" 0 "aktuell_empfangen" ;
VAL_ 914 GK2_Sta_VSG 1 "veraltet" 0 "aktuell_empfangen" ;
VAL_ 914 GK2_Sta_Profil 1 "veraltet" 0 "aktuell_empfangen" ;
VAL_ 914 GK2_Sta_Clima2 1 "veraltet" 0 "aktuell_empfangen" ;
VAL_ 914 GK2_Sta_Licht1 1 "veraltet" 0 "aktuell_empfangen" ;
VAL_ 914 GK2_Feh_VLR 1 "Fehler" 0 "kein_Fehler" ;
VAL_ 914 GK2_Sta_BSG4 1 "veraltet" 0 "aktuell_empfangen" ;
VAL_ 914 GK2_Sta_Schluessel 1 "veraltet" 0 "aktuell_empfangen" ;
VAL_ 914 GK2_LS_KomFehler 1 "Fehler" 0 "iO" ;
VAL_ 914 GK2_VD_zu_ver 1 "Verdeck_geschl_verr" 0 "Verdeck_nicht_geschl_verr" ;
VAL_ 914 GK2_VD_offen_ver 1 "Verdeck_offen_verr" 0 "Verdeck_nicht_offen_verr" ;
VAL_ 914 GK2_LS_def 1 "Fehler" 0 "iO" ;
VAL_ 914 GK2_Verdeck_Anf 1 "Anforderung_Verdeckbetrieb" 0 "keine_Verdeckanforderung" ;
VAL_ 914 GK2_VD_entriegelt 1 "Verdeck_bzw_VDKD_auf" 0 "Verdeck_und_VDKD_zu" ;
VAL_ 914 GK2_VDKD_auf 1 "VDKD_vollstaendig_auf" 0 "VDKD_nicht_vollst_auf" ;
VAL_ 914 GK2_EM_LIN_ungueltig 1 "ungueltig" 0 "gueltig" ;
VAL_ 914 GK2_AFL_Schalter 1 "Schalter_auf_AFL" 0 "Schalter_nicht_auf_AFL" ;
VAL_ 914 GK2_Hardtop 1 "Hardtop_montiert" 0 "Hardtop_nicht_montiert" ;
VAL_ 914 GK2_Kl_StSt_Info 3 "Systemfehler" 2 "Motoranlauf_notw" 1 "Stoppverbot_Motoranl_nn" 0 "Motorlauf_nn" ;
VAL_ 914 GK2_BEM_P_Generator 255 "Fehler" ;
VAL_ 914 GK2_BEM_Abschaltstufen 7 "Ruhestrommessmodus" 4 "Transportmodus" 3 "Stufe_3" 2 "Stufe_2" 1 "Stufe_1" 0 "Stufe_0_keine_Einschraenkung" ;
VAL_ 914 GK2_Nebelschluss 1 "Nebelschluss_ein" 0 "Nebelschluss_aus" ;
VAL_ 914 GK2_BSG_StSt_Info 3 "Systemfehler" 2 "Motoranlauf_notw" 1 "Stoppverbot_Motoranl_nn" 0 "Motorlauf_nn" ;
VAL_ 914 GK2_BEM_StSt_Info 3 "Systemfehler" 2 "Motoranlauf_notw" 1 "Stoppverbot_Motoranl_nn" 0 "Motorlauf_nn" ;
VAL_ 914 GK2_Kessy_StSt_Info 3 "Systemfehler" 2 "Motoranlauf_notw" 1 "Stoppverbot_Motoranl_nn" 0 "Motorlauf_nn" ;
VAL_ 919 ZK5_VD_Endlage_geschl 1 "Endlage_erreicht" 0 "Endlage_nicht_erreicht" ;
VAL_ 919 ZK5_VD_Endlage_abgelegt 1 "Endlage_erreicht" 0 "Endlage_nicht_erreicht" ;
VAL_ 919 ZK5_VD_Verbau 1 "man_Verdeck" 0 "autom_Verdeck" ;
VAL_ 1824 NMH_GW_Abschaltstufe_aktiv 1 "Abschaltstufe_aktiv" ;
VAL_ 1824 NMH_GW_Car_WakeUp 1 "Car_WakeUp" ;
VAL_ 1824 NMH_GW_Eindraht_Fehler 1 "Eindrahtbetrieb_erkannt" ;
VAL_ 1824 NMH_GW_Fkt_WakeUp 7 "LIN2Event" 6 "LIN1Event" 5 "ECANEvent" 4 "ICANEvent" 3 "KCANEvent" 2 "KBICANEvent" 1 "ACANEvent" 0 "Peripheriewakeup" ;
VAL_ 1824 NMH_GW_kein_NL 1 "kein_Nachlauf" ;
VAL_ 1824 NMH_GW_KompSchutz 1 "Komponentenschutz_aktiv" ;
VAL_ 1824 NMH_GW_Mute_Mode 1 "Mute_Mode_aktiv" ;
VAL_ 1824 NMH_GW_CAN_Diag_deaktiv 1 "keine_CANbez_Eigendiag" ;
VAL_ 1824 NMH_GW_NL_aktiv_5 1 "Nachlaufursache_5" ;
VAL_ 1824 NMH_GW_NL_aktiv_6 1 "Nachlaufursache_6" ;
VAL_ 1824 NMH_GW_NL_aktiv_7 1 "Nachlaufursache_7" ;
VAL_ 1824 NMH_GW_NL_aktiv_8 1 "Nachlaufursache_8" ;
VAL_ 1824 NMH_GW_NM_aktiv_Diagnose 1 "Diagnose_bei_Kl_15_aus" ;
VAL_ 1824 NMH_GW_NM_aktiv_Klemme_15 1 "Klemme_15_ein" ;
VAL_ 1824 NMH_GW_NL_aktiv_4 1 "Nachlaufursache_4" ;
VAL_ 1824 NMH_GW_NM_aktiv_Start 1 "Mindestaktivzeit_START" ;
VAL_ 1824 NMH_GW_Normal_Mode_1 1 "NORMAL_MODE_v_START" ;
VAL_ 1824 NMH_GW_Normal_Mode_2 1 "NORMAL_MODE_v_READY_TO_SLEEP" ;
VAL_ 1824 NMH_GW_Per_WakeUp 11 "WULtg" 9 "LIN1Transceiver" 7 "ICANTransceiver" 6 "KCANTransceiver" 3 "KL_15_HW" 2 "P_Wakeup_Ursache_unbekannt" 1 "CAN" 0 "Funktionswakeup" ;
VAL_ 1824 NMH_GW_Start_1 1 "START_v_SLEEP" ;
VAL_ 1824 NMH_GW_Start_2 1 "START_v_PREP_TO_SLEEP" ;
VAL_ 1824 NMH_GW_TimeOut_Fehler 1 "Timeout_Fehlereintrag" ;
VAL_ 1824 NMH_GW_Transport_Mode 1 "Transport_Mode_aktiv" ;
VAL_ 1527 KE1_Comp_rev_rq 0 "INIT" ;
VAL_ 1527 KE1_Comp_enable 1 "Enable" 0 "Disable" ;
VAL_ 1392 BSL_ZAS_Kl_50 1 "Klemme_50_aktiv" 0 "Grundzustand" ;
VAL_ 1392 BSL_Kl_L 1 "Klemme_L_aktiv" 0 "Grundzustand" ;
VAL_ 1392 BSL_ZAS_Kl_X 1 "Klemme_X_aktiv" 0 "Grundzustand" ;
VAL_ 1392 BSL_ZAS_Kl_15 1 "Klemme_15_aktiv" 0 "Grundzustand" ;
VAL_ 1392 BSL_Parklicht 1 "Klemme_P_aktiv" 0 "Grundzustand" ;
VAL_ 1392 BSL_ZAS_Kl_S 1 "S_Kontakt_aktiv" 0 "Grundzustand" ;
VAL_ 1392 BSL_Motor_Haube 1 "Haube_offen" 0 "Haube_geschlossen" ;
VAL_ 1392 BSL_Sta_UBat 3 "Fehler" 2 "entladen" 1 "kritisch" 0 "i_O" ;
VAL_ 1392 BSL_Fehlereintr 1 "Fehlerspeichereintrag" 0 "kein_Fehlerspeichereintrag" ;
VAL_ 1392 BSL_LL_Anheb 1 "Drehzahlanheb_gefordert" 0 "Grundzustand" ;
VAL_ 1392 BSL_Frontsch 1 "Verbraucher_abschalten" 0 "Grundzustand" ;
VAL_ 1392 BSL_Sitzheiz 1 "Verbraucher_abschalten" 0 "Grundzustand" ;
VAL_ 1392 BSL_Lenkradheiz 1 "Verbraucher_abschalten" 0 "Grundzustand" ;
VAL_ 1392 BSL_Aussensp 1 "Verbraucher_abschalten" 0 "Grundzustand" ;
VAL_ 1392 BSL_Sitzbelueft 1 "Verbraucher_abschalten" 0 "Grundzustand" ;
VAL_ 1392 BSL_BSG_2_alt 1 "veraltet" 0 "aktuell_empfangen" ;
VAL_ 1392 BSL_Hecksch 1 "Verbraucher_abschalten" 0 "Grundzustand" ;
VAL_ 1392 BSL_LL_Anheb2 1 "Drehzahlanheb_gefordert" 0 "Grundzustand" ;
VAL_ 1392 BSL_Clima 1 "Verbraucher_abschalten" 0 "Grundzustand" ;
VAL_ 1392 BSL_Weckursache_ACAN 3 "Weckursache_Tuerkontakt" 2 "Weckursache_StHzg" 0 "kein_EKP_Vorlauf" ;
VAL_ 1392 BSL_BSG_3_alt 1 "veraltet" 0 "aktuell_empfangen" ;
VAL_ 1392 BSL_Kl_15_Motor 1 "Klemme_15_aktiv" 0 "Grundzustand" ;
VAL_ 1392 BSL_UBat 255 "Fehler" ;
VAL_ 1392 BSL_Kuehlerlueft 1 "einschalten" 0 "keine_Anforderung" ;
VAL_ 1392 BSL_Sta_LWR 1 "LWR_Fehler" 0 "LWR_i_O" ;
VAL_ 1392 BSL_Sta_StBat 3 "Fehler" 2 "entladen" 1 "kritisch" 0 "i_O" ;
VAL_ 1392 BSL_Ab_Batterie 1 "Batterie_Ab" 0 "Batterie_am_Bordnetz" ;
VAL_ 1392 BSL_Wasserheiz 1 "Verbraucher_abschalten" 0 "Grundzustand" ;
VAL_ 1392 BSL_Wake_Up_ACAN 1 "Wecken_ACAN" 0 "kein_Wecken_ACAN" ;
VAL_ 1392 BSL_Starterlaubnis 1 "Start_erlaubt" 0 "Start_nicht_erlaubt" ;
VAL_ 1394 ZA1_S_Kontakt 1 "Kontakt_geschlossen" 0 "Kontakt_offen" ;
VAL_ 1394 ZA1_Klemme_15 1 "Zuendung_ein" 0 "Zuendung_aus" ;
VAL_ 1394 ZA1_Klemme_P 1 "Parklichtstellung" 0 "keine_Parklichtstellung" ;
VAL_ 1394 ZA1_Klemme_X 1 "Klemme_X_aktiv" 0 "Grundzustand" ;
VAL_ 1394 ZA1_Klemme_50 1 "Starten" 0 "kein_Starten" ;
VAL_ 1394 ZA1_Klemme_SV 1 "Kl_15_SV_ein" 0 "Kl_15_SV_aus" ;
VAL_ 1394 ZA1_Fehlereintr 1 "Fehlerspeichereintrag" 0 "kein_Fehlerspeichereintrag" ;
